VERSION "canboat-NMEA2000-curated"

NS_ :

BS_:

BU_: Vector__XXX
BO_ 2583633408 PGN_130846_furunoMotionSensorStatusExtended: 28 Vector__XXX
 SG_ Manufacturer_Code : 0|11@1+ (1.0,0) [0|2047] "" Vector__XXX
 SG_ Industry_Code : 13|3@1+ (1.0,0) [0|7] "" Vector__XXX
 SG_ Status : 16|8@1+ (1.0,0) [0|255] "" Vector__XXX
 SG_ Data : 24|200@1+ (1.0,0) [0|1606938044258990275541962092341162602522202993782792835301375] "" Vector__XXX

BO_ 2583633408 PGN_130846_maretronBatteryAmpHourRecord: 223 Vector__XXX
 SG_ Manufacturer_Code : 0|11@1+ (1.0,0) [0|2047] "" Vector__XXX
 SG_ Industry_Code : 13|3@1+ (1.0,0) [0|7] "" Vector__XXX
 SG_ Data : 16|1768@1+ (1.0,0) [0|16635364987126134419907490844611231857889171561340108669757218330385068731224834608417815051548234195819468783937845710359164977421616154908223175941492902641772198991471137845920843845811776377869137773379678289214194183661112800944378464511794046030758602257005203964634516091405743061582849883160885255175229773660916874237270946647032424101972117051870087763059119895517977437771543686400460392041962138103436564399831189767740372774280024852942859855049773927338342604171805121253257539126169331943684033945189625789470637817855] "" Vector__XXX

BO_ 2583633408 PGN_130846_simnetParameterSet: 12 Vector__XXX
 SG_ Manufacturer_Code : 0|11@1+ (1.0,0) [0|2047] "" Vector__XXX
 SG_ Industry_Code : 13|3@1+ (1.0,0) [0|7] "" Vector__XXX
 SG_ Address : 16|8@1+ (1.0,0) [0|255] "" Vector__XXX
 SG_ Instance : 24|8@1+ (1.0,0) [0|255] "" Vector__XXX
 SG_ Network_Group : 32|8@1+ (1.0,0) [0|255] "" Vector__XXX
 SG_ Source : 40|8@1+ (1.0,0) [0|255] "" Vector__XXX
 SG_ Key : 48|24@1+ (1.0,0) [0|16777215] "" Vector__XXX
 SG_ Operation : 72|8@1+ (1.0,0) [0|255] "" Vector__XXX
 SG_ Length : 80|8@1+ (1.0,0) [0|255] "" Vector__XXX
 SG_ Value : 88|8@1+ (1.0,0) [0|255] "" Vector__XXX

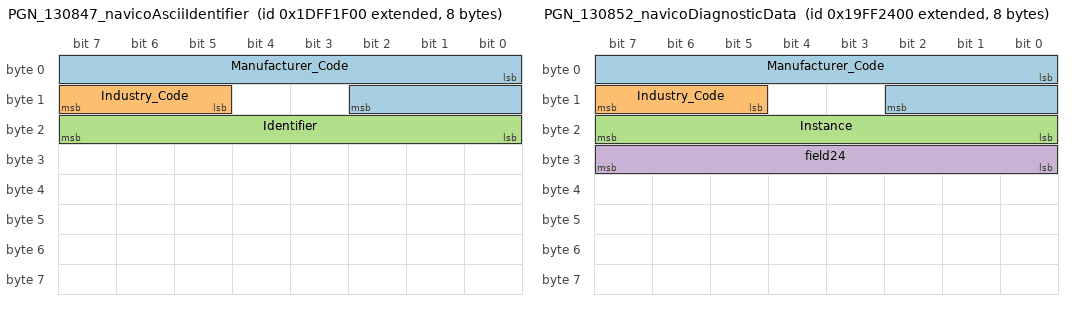
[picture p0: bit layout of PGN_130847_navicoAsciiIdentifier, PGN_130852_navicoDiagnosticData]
BO_ 2650742528 PGN_130847_navicoAsciiIdentifier: 8 Vector__XXX
 SG_ Manufacturer_Code : 0|11@1+ (1.0,0) [0|2047] "" Vector__XXX
 SG_ Industry_Code : 13|3@1+ (1.0,0) [0|7] "" Vector__XXX
 SG_ Identifier : 16|8@1+ (1.0,0) [0|255] "" Vector__XXX

BO_ 2583633664 PGN_130847_seatalkNodeStatistics: 10 Vector__XXX
 SG_ Manufacturer_Code : 0|11@1+ (1.0,0) [0|2047] "" Vector__XXX
 SG_ Industry_Code : 13|3@1+ (1.0,0) [0|7] "" Vector__XXX
 SG_ Product_Code : 16|16@1+ (1.0,0) [0|65535] "" Vector__XXX
 SG_ Year : 32|8@1+ (1.0,0) [0|255] "" Vector__XXX
 SG_ Month : 40|8@1+ (1.0,0) [0|255] "" Vector__XXX
 SG_ Device_Number : 48|16@1+ (1.0,0) [0|65535] "" Vector__XXX
 SG_ Node_Voltage : 64|16@1+ (0.01,0) [0.0|655.35] "" Vector__XXX

BO_ 2650742784 PGN_130848_seatalkWaypointInformation: 31 Vector__XXX
 SG_ Manufacturer_Code : 0|11@1+ (1.0,0) [0|2047] "" Vector__XXX
 SG_ Industry_Code : 13|3@1+ (1.0,0) [0|7] "" Vector__XXX
 SG_ SID : 16|8@1+ (1.0,0) [0|255] "" Vector__XXX
 SG_ Waypoint_Name : 24|128@1+ (1.0,0) [0|340282366920938463463374607431768211455] "" Vector__XXX
 SG_ Waypoint_Sequence : 152|32@1+ (1.0,0) [0|4294967295] "" Vector__XXX
 SG_ Bearing_to_Waypoint__True : 184|16@1+ (0.0001,0) [0.0|6.5535000000000005] "" Vector__XXX
 SG_ Bearing_to_Waypoint__Magnetic : 200|16@1+ (0.0001,0) [0.0|6.5535000000000005] "" Vector__XXX
 SG_ Distance_to_Waypoint : 216|32@1+ (0.01,0) [0.0|42949672.95] "" Vector__XXX

BO_ 2583634176 PGN_130849_navicoProprietaryFp: 8 Vector__XXX
 SG_ Manufacturer_Code : 0|11@1+ (1.0,0) [0|2047] "" Vector__XXX
 SG_ Industry_Code : 13|3@1+ (1.0,0) [0|7] "" Vector__XXX

BO_ 2315198976 PGN_130850_simnetAlarm: 12 Vector__XXX
 SG_ Manufacturer_Code : 0|11@1+ (1.0,0) [0|2047] "" Vector__XXX
 SG_ Industry_Code : 13|3@1+ (1.0,0) [0|7] "" Vector__XXX
 SG_ Address : 16|8@1+ (1.0,0) [0|255] "" Vector__XXX
 SG_ Network_Group : 32|8@1+ (1.0,0) [0|255] "" Vector__XXX
 SG_ Event_Type : 40|8@1+ (1.0,0) [0|255] "" Vector__XXX
 SG_ Command : 48|8@1+ (1.0,0) [0|255] "" Vector__XXX
 SG_ Spare : 56|8@1+ (1.0,0) [0|255] "" Vector__XXX
 SG_ Alarm_ID : 64|16@1+ (1.0,0) [0|65535] "" Vector__XXX
 SG_ F : 80|8@1+ (1.0,0) [0|255] "" Vector__XXX
 SG_ G : 88|8@1+ (1.0,0) [0|255] "" Vector__XXX

BO_ 2315198976 PGN_130850_simnetApCommand: 12 Vector__XXX
 SG_ Manufacturer_Code : 0|11@1+ (1.0,0) [0|2047] "" Vector__XXX
 SG_ Industry_Code : 13|3@1+ (1.0,0) [0|7] "" Vector__XXX
 SG_ Address : 16|8@1+ (1.0,0) [0|255] "" Vector__XXX
 SG_ Network_Group : 32|8@1+ (1.0,0) [0|255] "" Vector__XXX
 SG_ Command_Type : 40|8@1+ (1.0,0) [0|255] "" Vector__XXX
 SG_ Event : 48|8@1+ (1.0,0) [0|255] "" Vector__XXX
 SG_ Spare : 56|8@1+ (1.0,0) [0|255] "" Vector__XXX

BO_ 2315198976 PGN_130850_simnetCommandApChangeCourse: 12 Vector__XXX
 SG_ Manufacturer_Code : 0|11@1+ (1.0,0) [0|2047] "" Vector__XXX
 SG_ Industry_Code : 13|3@1+ (1.0,0) [0|7] "" Vector__XXX
 SG_ Address : 16|8@1+ (1.0,0) [0|255] "" Vector__XXX
 SG_ Network_Group : 32|8@1+ (1.0,0) [0|255] "" Vector__XXX
 SG_ Command_Type : 40|8@1+ (1.0,0) [0|255] "" Vector__XXX
 SG_ Event : 48|8@1+ (1.0,0) [0|255] "" Vector__XXX
 SG_ Spare : 56|8@1+ (1.0,0) [0|255] "" Vector__XXX
 SG_ Direction : 64|8@1+ (1.0,0) [0|255] "" Vector__XXX
 SG_ Angle : 72|16@1+ (0.0001,0) [0.0|6.5535000000000005] "" Vector__XXX

BO_ 2315198976 PGN_130850_simnetCommandApFollowUp: 12 Vector__XXX
 SG_ Manufacturer_Code : 0|11@1+ (1.0,0) [0|2047] "" Vector__XXX
 SG_ Industry_Code : 13|3@1+ (1.0,0) [0|7] "" Vector__XXX
 SG_ Address : 16|8@1+ (1.0,0) [0|255] "" Vector__XXX
 SG_ Network_Group : 32|8@1+ (1.0,0) [0|255] "" Vector__XXX
 SG_ Command_Type : 40|8@1+ (1.0,0) [0|255] "" Vector__XXX
 SG_ Event : 48|8@1+ (1.0,0) [0|255] "" Vector__XXX
 SG_ Spare : 56|8@1+ (1.0,0) [0|255] "" Vector__XXX

BO_ 2315198976 PGN_130850_simnetCommandApHeading: 12 Vector__XXX
 SG_ Manufacturer_Code : 0|11@1+ (1.0,0) [0|2047] "" Vector__XXX
 SG_ Industry_Code : 13|3@1+ (1.0,0) [0|7] "" Vector__XXX
 SG_ Address : 16|8@1+ (1.0,0) [0|255] "" Vector__XXX
 SG_ Network_Group : 32|8@1+ (1.0,0) [0|255] "" Vector__XXX
 SG_ Command_Type : 40|8@1+ (1.0,0) [0|255] "" Vector__XXX
 SG_ Event : 48|8@1+ (1.0,0) [0|255] "" Vector__XXX
 SG_ Spare : 56|8@1+ (1.0,0) [0|255] "" Vector__XXX

BO_ 2315198976 PGN_130850_simnetCommandApNav: 12 Vector__XXX
 SG_ Manufacturer_Code : 0|11@1+ (1.0,0) [0|2047] "" Vector__XXX
 SG_ Industry_Code : 13|3@1+ (1.0,0) [0|7] "" Vector__XXX
 SG_ Address : 16|8@1+ (1.0,0) [0|255] "" Vector__XXX
 SG_ Network_Group : 32|8@1+ (1.0,0) [0|255] "" Vector__XXX
 SG_ Command_Type : 40|8@1+ (1.0,0) [0|255] "" Vector__XXX
 SG_ Event : 48|8@1+ (1.0,0) [0|255] "" Vector__XXX
 SG_ Spare : 56|8@1+ (1.0,0) [0|255] "" Vector__XXX

BO_ 2315198976 PGN_130850_simnetCommandApNodrift: 12 Vector__XXX
 SG_ Manufacturer_Code : 0|11@1+ (1.0,0) [0|2047] "" Vector__XXX
 SG_ Industry_Code : 13|3@1+ (1.0,0) [0|7] "" Vector__XXX
 SG_ Address : 16|8@1+ (1.0,0) [0|255] "" Vector__XXX
 SG_ Network_Group : 32|8@1+ (1.0,0) [0|255] "" Vector__XXX
 SG_ Command_Type : 40|8@1+ (1.0,0) [0|255] "" Vector__XXX
 SG_ Event : 48|8@1+ (1.0,0) [0|255] "" Vector__XXX
 SG_ Spare : 56|8@1+ (1.0,0) [0|255] "" Vector__XXX

BO_ 2315198976 PGN_130850_simnetCommandApStandby: 12 Vector__XXX
 SG_ Manufacturer_Code : 0|11@1+ (1.0,0) [0|2047] "" Vector__XXX
 SG_ Industry_Code : 13|3@1+ (1.0,0) [0|7] "" Vector__XXX
 SG_ Address : 16|8@1+ (1.0,0) [0|255] "" Vector__XXX
 SG_ Network_Group : 32|8@1+ (1.0,0) [0|255] "" Vector__XXX
 SG_ Command_Type : 40|8@1+ (1.0,0) [0|255] "" Vector__XXX
 SG_ Event : 48|8@1+ (1.0,0) [0|255] "" Vector__XXX
 SG_ Spare : 56|8@1+ (1.0,0) [0|255] "" Vector__XXX

BO_ 2315198976 PGN_130850_simnetCommandApTack: 12 Vector__XXX
 SG_ Manufacturer_Code : 0|11@1+ (1.0,0) [0|2047] "" Vector__XXX
 SG_ Industry_Code : 13|3@1+ (1.0,0) [0|7] "" Vector__XXX
 SG_ Address : 16|8@1+ (1.0,0) [0|255] "" Vector__XXX
 SG_ Network_Group : 32|8@1+ (1.0,0) [0|255] "" Vector__XXX
 SG_ Command_Type : 40|8@1+ (1.0,0) [0|255] "" Vector__XXX
 SG_ Event : 48|8@1+ (1.0,0) [0|255] "" Vector__XXX
 SG_ Unknown_A : 56|8@1+ (1.0,0) [0|255] "" Vector__XXX
 SG_ Unknown_B : 64|8@1+ (1.0,0) [0|255] "" Vector__XXX

BO_ 2315198976 PGN_130850_simnetCommandApWind: 12 Vector__XXX
 SG_ Manufacturer_Code : 0|11@1+ (1.0,0) [0|2047] "" Vector__XXX
 SG_ Industry_Code : 13|3@1+ (1.0,0) [0|7] "" Vector__XXX
 SG_ Address : 16|8@1+ (1.0,0) [0|255] "" Vector__XXX
 SG_ Network_Group : 32|8@1+ (1.0,0) [0|255] "" Vector__XXX
 SG_ Command_Type : 40|8@1+ (1.0,0) [0|255] "" Vector__XXX
 SG_ Event : 48|8@1+ (1.0,0) [0|255] "" Vector__XXX
 SG_ Spare : 56|8@1+ (1.0,0) [0|255] "" Vector__XXX

BO_ 2315198976 PGN_130850_simnetEvent: 12 Vector__XXX
 SG_ Manufacturer_Code : 0|11@1+ (1.0,0) [0|2047] "" Vector__XXX
 SG_ Industry_Code : 13|3@1+ (1.0,0) [0|7] "" Vector__XXX
 SG_ Address : 16|8@1+ (1.0,0) [0|255] "" Vector__XXX
 SG_ Network_Group : 32|8@1+ (1.0,0) [0|255] "" Vector__XXX

BO_ 2315198976 PGN_130850_simnetEventCommandTimer: 12 Vector__XXX
 SG_ Manufacturer_Code : 0|11@1+ (1.0,0) [0|2047] "" Vector__XXX
 SG_ Industry_Code : 13|3@1+ (1.0,0) [0|7] "" Vector__XXX
 SG_ Address : 16|8@1+ (1.0,0) [0|255] "" Vector__XXX
 SG_ Network_Group : 32|8@1+ (1.0,0) [0|255] "" Vector__XXX
 SG_ Event_Type : 40|8@1+ (1.0,0) [0|255] "" Vector__XXX
 SG_ Event : 48|16@1+ (1.0,0) [0|65535] "" Vector__XXX
 SG_ Parameter_1 : 64|8@1+ (1.0,0) [0|255] "" Vector__XXX
 SG_ Parameter_2 : 72|16@1+ (1.0,0) [0|65535] "" Vector__XXX
 SG_ Parameter_3 : 88|8@1+ (1.0,0) [0|255] "" Vector__XXX

BO_ 2650743552 PGN_130851_simnetApCommandReply: 12 Vector__XXX
 SG_ Manufacturer_Code : 0|11@1+ (1.0,0) [0|2047] "" Vector__XXX
 SG_ Industry_Code : 13|3@1+ (1.0,0) [0|7] "" Vector__XXX
 SG_ Address : 16|8@1+ (1.0,0) [0|255] "" Vector__XXX
 SG_ Network_Group : 32|8@1+ (1.0,0) [0|255] "" Vector__XXX
 SG_ Command_Type : 40|8@1+ (1.0,0) [0|255] "" Vector__XXX
 SG_ Event : 48|8@1+ (1.0,0) [0|255] "" Vector__XXX
 SG_ Spare : 56|8@1+ (1.0,0) [0|255] "" Vector__XXX
 SG_ D : 64|8@1+ (1.0,0) [0|255] "" Vector__XXX
 SG_ Value : 72|16@1+ (1.0,0) [0|65535] "" Vector__XXX

BO_ 2650743552 PGN_130851_simnetApCommandReplyChangeCourse: 12 Vector__XXX
 SG_ Manufacturer_Code : 0|11@1+ (1.0,0) [0|2047] "" Vector__XXX
 SG_ Industry_Code : 13|3@1+ (1.0,0) [0|7] "" Vector__XXX
 SG_ Address : 16|8@1+ (1.0,0) [0|255] "" Vector__XXX
 SG_ Network_Group : 32|8@1+ (1.0,0) [0|255] "" Vector__XXX
 SG_ Command_Type : 40|8@1+ (1.0,0) [0|255] "" Vector__XXX
 SG_ Event : 48|8@1+ (1.0,0) [0|255] "" Vector__XXX
 SG_ Spare : 56|8@1+ (1.0,0) [0|255] "" Vector__XXX
 SG_ Direction : 64|8@1+ (1.0,0) [0|255] "" Vector__XXX
 SG_ Angle : 72|16@1+ (0.0001,0) [0.0|6.5535000000000005] "" Vector__XXX

BO_ 2583634944 PGN_130852_navicoDiagnosticData: 8 Vector__XXX
 SG_ Manufacturer_Code : 0|11@1+ (1.0,0) [0|2047] "" Vector__XXX
 SG_ Industry_Code : 13|3@1+ (1.0,0) [0|7] "" Vector__XXX
 SG_ Instance : 16|8@1+ (1.0,0) [0|255] "" Vector__XXX
 SG_ field24 : 24|8@1+ (1.0,0) [0|255] "" Vector__XXX

CM_ BO_ 2583633408 "NMEA2000: PGN 130846 - Furuno: Motion Sensor Status Extended (type: Fast)";
CM_ BO_ 2583633408 "NMEA2000: PGN 130846 - Maretron: Battery Amp Hour Record (type: Fast)";
CM_ BO_ 2583633408 "NMEA2000: PGN 130846 - Simnet: Key Value - Long (type: Fast)";
CM_ BO_ 2650742528 "NMEA2000: PGN 130847 - Navico: ASCII Identifier (type: Fast)";
CM_ BO_ 2583633664 "NMEA2000: PGN 130847 - SeaTalk: Node Statistics (type: Fast)";
CM_ BO_ 2650742784 "NMEA2000: PGN 130848 - SeaTalk: Waypoint Information (type: Fast)";
CM_ BO_ 2583634176 "NMEA2000: PGN 130849 - Navico: Proprietary FP (type: Fast)";
CM_ BO_ 2315198976 "NMEA2000: PGN 130850 - Simnet: Alarm (type: Fast)";
CM_ BO_ 2315198976 "NMEA2000: PGN 130850 - Simnet: AP command (type: Fast)";
CM_ BO_ 2315198976 "NMEA2000: PGN 130850 - Simnet: Command AP Change Course (type: Fast)";
CM_ BO_ 2315198976 "NMEA2000: PGN 130850 - Simnet: Command AP Follow Up (type: Fast)";
CM_ BO_ 2315198976 "NMEA2000: PGN 130850 - Simnet: Command AP Heading (type: Fast)";
CM_ BO_ 2315198976 "NMEA2000: PGN 130850 - Simnet: Command AP Nav (type: Fast)";
CM_ BO_ 2315198976 "NMEA2000: PGN 130850 - Simnet: Command AP NoDrift (type: Fast)";
CM_ BO_ 2315198976 "NMEA2000: PGN 130850 - Simnet: Command AP Standby (type: Fast)";
CM_ BO_ 2315198976 "NMEA2000: PGN 130850 - Simnet: Command AP Tack (type: Fast)";
CM_ BO_ 2315198976 "NMEA2000: PGN 130850 - Simnet: Command AP Wind (type: Fast)";
CM_ BO_ 2315198976 "NMEA2000: PGN 130850 - Simnet: Event (type: Fast)";
CM_ BO_ 2315198976 "NMEA2000: PGN 130850 - Simnet: Event Command: Timer (type: Fast)";
CM_ BO_ 2650743552 "NMEA2000: PGN 130851 - Simnet: AP command Reply (type: Fast)";
CM_ BO_ 2650743552 "NMEA2000: PGN 130851 - Simnet: AP command Reply: Change Course (type: Fast)";
CM_ BO_ 2583634944 "NMEA2000: PGN 130852 - Navico: Diagnostic Data (type: Fast)";
CM_ SG_ 2583633408 Manufacturer_Code "Furuno; canboat type: LOOKUP";
CM_ SG_ 2583633408 Industry_Code "Marine Industry; canboat type: LOOKUP";
CM_ SG_ 2583633408 Status "canboat type: UINT8";
CM_ SG_ 2583633408 Data "canboat type: BINARY";
CM_ SG_ 2583633408 Manufacturer_Code "Maretron; canboat type: LOOKUP";
CM_ SG_ 2583633408 Industry_Code "Marine Industry; canboat type: LOOKUP";
CM_ SG_ 2583633408 Data "canboat type: BINARY";
CM_ SG_ 2583633408 Manufacturer_Code "Simrad; canboat type: LOOKUP";
CM_ SG_ 2583633408 Industry_Code "Marine Industry; canboat type: LOOKUP";
CM_ SG_ 2583633408 Address "NMEA 2000 address of commanded device; canboat type: UINT8";
CM_ SG_ 2583633408 Instance "Instance index when a Key has multiple sources/instances; 0xFF when not applicable. Caller-supplied and echoed back in replies.; canboat type: UINT8";
CM_ SG_ 2583633408 Network_Group "This can be either the Display Group, Units Group, Damping Group or Alarms Group, depending on which key is being set; canboat type: LOOKUP";
CM_ SG_ 2583633408 Source "Source/owner that provided the value; set by the responder when Operation = Reply, 0xFF in read/set requests. This is NOT an NMEA 2000 bus address.; canboat type: UINT8";
CM_ SG_ 2583633408 Key "Composite 24-bit little-endian key = command group (low byte) | parameter key (upper 16 bits) << 8. The two parts are NOT split into separate fields because the parameter key is only unique within a command group (e.g. key 1 is 'True wind high' in group 4 but 'Deep water' in group 8), so the value's data type can only be resolved from the group and key together. This key space is distinct from the PGN 130822 tDataType ids and from the B&G and Mercury key spaces.; canboat type: DYNAMIC_FIELD_KEY";
CM_ SG_ 2583633408 Operation "canboat type: LOOKUP";
CM_ SG_ 2583633408 Length "Number of bytes in the Value field that follows; canboat type: DYNAMIC_FIELD_LENGTH";
CM_ SG_ 2583633408 Value "Variable-width value; width given by Length, datatype resolved per Key; canboat type: DYNAMIC_FIELD_VALUE";
CM_ SG_ 2650742528 Manufacturer_Code "Navico; canboat type: LOOKUP";
CM_ SG_ 2650742528 Industry_Code "Marine Industry; canboat type: LOOKUP";
CM_ SG_ 2650742528 Identifier "canboat type: STRING_LZ";
CM_ SG_ 2583633664 Manufacturer_Code "Raymarine; canboat type: LOOKUP";
CM_ SG_ 2583633664 Industry_Code "Marine Industry; canboat type: LOOKUP";
CM_ SG_ 2583633664 Product_Code "canboat type: UINT16";
CM_ SG_ 2583633664 Year "canboat type: UINT8";
CM_ SG_ 2583633664 Month "canboat type: UINT8";
CM_ SG_ 2583633664 Device_Number "canboat type: UINT16";
CM_ SG_ 2583633664 Node_Voltage "canboat type: VOLTAGE_UFIX16_10MV";
CM_ SG_ 2650742784 Manufacturer_Code "Raymarine; canboat type: LOOKUP";
CM_ SG_ 2650742784 Industry_Code "Marine Industry; canboat type: LOOKUP";
CM_ SG_ 2650742784 SID "canboat type: UINT8";
CM_ SG_ 2650742784 Waypoint_Name "canboat type: STRING_FIX";
CM_ SG_ 2650742784 Waypoint_Sequence "canboat type: STRING_FIX";
CM_ SG_ 2650742784 Bearing_to_Waypoint__True "canboat type: ANGLE_UFIX16";
CM_ SG_ 2650742784 Bearing_to_Waypoint__Magnetic "canboat type: ANGLE_UFIX16";
CM_ SG_ 2650742784 Distance_to_Waypoint "canboat type: LENGTH_UFIX32_CM";
CM_ SG_ 2583634176 Manufacturer_Code "Navico; canboat type: LOOKUP";
CM_ SG_ 2583634176 Industry_Code "Marine Industry; canboat type: LOOKUP";
CM_ SG_ 2315198976 Manufacturer_Code "Simrad; canboat type: LOOKUP";
CM_ SG_ 2315198976 Industry_Code "Marine Industry; canboat type: LOOKUP";
CM_ SG_ 2315198976 Address "NMEA 2000 address of commanded device; canboat type: UINT8";
CM_ SG_ 2315198976 Network_Group "canboat type: LOOKUP";
CM_ SG_ 2315198976 Event_Type "Alarm; canboat type: LOOKUP";
CM_ SG_ 2315198976 Command "canboat type: LOOKUP";
CM_ SG_ 2315198976 Spare "canboat type: SPARE";
CM_ SG_ 2315198976 Alarm_ID "canboat type: LOOKUP";
CM_ SG_ 2315198976 F "canboat type: UINT8";
CM_ SG_ 2315198976 G "canboat type: UINT8";
CM_ SG_ 2315198976 Manufacturer_Code "Simrad; canboat type: LOOKUP";
CM_ SG_ 2315198976 Industry_Code "Marine Industry; canboat type: LOOKUP";
CM_ SG_ 2315198976 Address "NMEA 2000 address of commanded device; canboat type: UINT8";
CM_ SG_ 2315198976 Network_Group "canboat type: LOOKUP";
CM_ SG_ 2315198976 Command_Type "AP Command; canboat type: LOOKUP";
CM_ SG_ 2315198976 Event "canboat type: LOOKUP";
CM_ SG_ 2315198976 Spare "canboat type: SPARE";
CM_ SG_ 2315198976 Manufacturer_Code "Simrad; canboat type: LOOKUP";
CM_ SG_ 2315198976 Industry_Code "Marine Industry; canboat type: LOOKUP";
CM_ SG_ 2315198976 Address "NMEA 2000 address of commanded device; canboat type: UINT8";
CM_ SG_ 2315198976 Network_Group "canboat type: LOOKUP";
CM_ SG_ 2315198976 Command_Type "AP Command; canboat type: LOOKUP";
CM_ SG_ 2315198976 Event "Change course; canboat type: LOOKUP";
CM_ SG_ 2315198976 Spare "canboat type: SPARE";
CM_ SG_ 2315198976 Direction "canboat type: LOOKUP";
CM_ SG_ 2315198976 Angle "Absolute change in desired attitude, generally 1 or 10 degrees; canboat type: ANGLE_UFIX16";
CM_ SG_ 2315198976 Manufacturer_Code "Simrad; canboat type: LOOKUP";
CM_ SG_ 2315198976 Industry_Code "Marine Industry; canboat type: LOOKUP";
CM_ SG_ 2315198976 Address "NMEA 2000 address of commanded device; canboat type: UINT8";
CM_ SG_ 2315198976 Network_Group "canboat type: LOOKUP";
CM_ SG_ 2315198976 Command_Type "Follow Up; canboat type: LOOKUP";
CM_ SG_ 2315198976 Event "Follow Up mode; canboat type: LOOKUP";
CM_ SG_ 2315198976 Spare "canboat type: SPARE";
CM_ SG_ 2315198976 Manufacturer_Code "Simrad; canboat type: LOOKUP";
CM_ SG_ 2315198976 Industry_Code "Marine Industry; canboat type: LOOKUP";
CM_ SG_ 2315198976 Address "NMEA 2000 address of commanded device; canboat type: UINT8";
CM_ SG_ 2315198976 Network_Group "canboat type: LOOKUP";
CM_ SG_ 2315198976 Command_Type "AP Command; canboat type: LOOKUP";
CM_ SG_ 2315198976 Event "Heading mode; canboat type: LOOKUP";
CM_ SG_ 2315198976 Spare "canboat type: SPARE";
CM_ SG_ 2315198976 Manufacturer_Code "Simrad; canboat type: LOOKUP";
CM_ SG_ 2315198976 Industry_Code "Marine Industry; canboat type: LOOKUP";
CM_ SG_ 2315198976 Address "NMEA 2000 address of commanded device; canboat type: UINT8";
CM_ SG_ 2315198976 Network_Group "canboat type: LOOKUP";
CM_ SG_ 2315198976 Command_Type "AP Command; canboat type: LOOKUP";
CM_ SG_ 2315198976 Event "Nav mode; canboat type: LOOKUP";
CM_ SG_ 2315198976 Spare "canboat type: SPARE";
CM_ SG_ 2315198976 Manufacturer_Code "Simrad; canboat type: LOOKUP";
CM_ SG_ 2315198976 Industry_Code "Marine Industry; canboat type: LOOKUP";
CM_ SG_ 2315198976 Address "NMEA 2000 address of commanded device; canboat type: UINT8";
CM_ SG_ 2315198976 Network_Group "canboat type: LOOKUP";
CM_ SG_ 2315198976 Command_Type "AP Command; canboat type: LOOKUP";
CM_ SG_ 2315198976 Event "No Drift mode; canboat type: LOOKUP";
CM_ SG_ 2315198976 Spare "canboat type: SPARE";
CM_ SG_ 2315198976 Manufacturer_Code "Simrad; canboat type: LOOKUP";
CM_ SG_ 2315198976 Industry_Code "Marine Industry; canboat type: LOOKUP";
CM_ SG_ 2315198976 Address "NMEA 2000 address of commanded device; canboat type: UINT8";
CM_ SG_ 2315198976 Network_Group "canboat type: LOOKUP";
CM_ SG_ 2315198976 Command_Type "AP Command; canboat type: LOOKUP";
CM_ SG_ 2315198976 Event "Standby; canboat type: LOOKUP";
CM_ SG_ 2315198976 Spare "canboat type: SPARE";
CM_ SG_ 2315198976 Manufacturer_Code "Simrad; canboat type: LOOKUP";
CM_ SG_ 2315198976 Industry_Code "Marine Industry; canboat type: LOOKUP";
CM_ SG_ 2315198976 Address "NMEA 2000 address of commanded device; canboat type: UINT8";
CM_ SG_ 2315198976 Network_Group "canboat type: LOOKUP";
CM_ SG_ 2315198976 Command_Type "AP Command; canboat type: LOOKUP";
CM_ SG_ 2315198976 Event "Tack; canboat type: LOOKUP";
CM_ SG_ 2315198976 Unknown_A "canboat type: UINT8";
CM_ SG_ 2315198976 Unknown_B "canboat type: UINT8";
CM_ SG_ 2315198976 Manufacturer_Code "Simrad; canboat type: LOOKUP";
CM_ SG_ 2315198976 Industry_Code "Marine Industry; canboat type: LOOKUP";
CM_ SG_ 2315198976 Address "NMEA 2000 address of commanded device; canboat type: UINT8";
CM_ SG_ 2315198976 Network_Group "canboat type: LOOKUP";
CM_ SG_ 2315198976 Command_Type "AP Command; canboat type: LOOKUP";
CM_ SG_ 2315198976 Event "Wind mode; canboat type: LOOKUP";
CM_ SG_ 2315198976 Spare "canboat type: SPARE";
CM_ SG_ 2315198976 Manufacturer_Code "Simrad; canboat type: LOOKUP";
CM_ SG_ 2315198976 Industry_Code "Marine Industry; canboat type: LOOKUP";
CM_ SG_ 2315198976 Address "NMEA 2000 address of commanded device; canboat type: UINT8";
CM_ SG_ 2315198976 Network_Group "canboat type: LOOKUP";
CM_ SG_ 2315198976 Manufacturer_Code "Simrad; canboat type: LOOKUP";
CM_ SG_ 2315198976 Industry_Code "Marine Industry; canboat type: LOOKUP";
CM_ SG_ 2315198976 Address "NMEA 2000 address of commanded device, used for autopilot events; canboat type: UINT8";
CM_ SG_ 2315198976 Network_Group "canboat type: LOOKUP";
CM_ SG_ 2315198976 Event_Type "Timer; canboat type: LOOKUP";
CM_ SG_ 2315198976 Event "canboat type: LOOKUP";
CM_ SG_ 2315198976 Parameter_1 "Event dependent; for the trip timer 0 = Trip 1, 1 = Trip 2; canboat type: UINT8";
CM_ SG_ 2315198976 Parameter_2 "Event dependent; canboat type: UINT16";
CM_ SG_ 2315198976 Parameter_3 "Event dependent; canboat type: UINT8";
CM_ SG_ 2650743552 Manufacturer_Code "Simrad; canboat type: LOOKUP";
CM_ SG_ 2650743552 Industry_Code "Marine Industry; canboat type: LOOKUP";
CM_ SG_ 2650743552 Address "NMEA 2000 address of the autopilot that ran the command; canboat type: UINT8";
CM_ SG_ 2650743552 Network_Group "canboat type: LOOKUP";
CM_ SG_ 2650743552 Command_Type "AP Command; canboat type: LOOKUP";
CM_ SG_ 2650743552 Event "canboat type: LOOKUP";
CM_ SG_ 2650743552 Spare "canboat type: SPARE";
CM_ SG_ 2650743552 D "canboat type: UINT8";
CM_ SG_ 2650743552 Value "canboat type: UINT16";
CM_ SG_ 2650743552 Manufacturer_Code "Simrad; canboat type: LOOKUP";
CM_ SG_ 2650743552 Industry_Code "Marine Industry; canboat type: LOOKUP";
CM_ SG_ 2650743552 Address "NMEA 2000 address of the autopilot that ran the command; canboat type: UINT8";
CM_ SG_ 2650743552 Network_Group "canboat type: LOOKUP";
CM_ SG_ 2650743552 Command_Type "AP Command; canboat type: LOOKUP";
CM_ SG_ 2650743552 Event "Change course; canboat type: LOOKUP";
CM_ SG_ 2650743552 Spare "canboat type: SPARE";
CM_ SG_ 2650743552 Direction "canboat type: LOOKUP";
CM_ SG_ 2650743552 Angle "Absolute change in desired attitude, generally 1 or 10 degrees; canboat type: ANGLE_UFIX16";
CM_ SG_ 2583634944 Manufacturer_Code "Navico; canboat type: LOOKUP";
CM_ SG_ 2583634944 Industry_Code "Marine Industry; canboat type: LOOKUP";
CM_ SG_ 2583634944 Instance "Diagnostic channel/instance the report covers; echoed from the request (0 when unspecified); canboat type: UINT8";
CM_ SG_ 2583634944 field24 "canboat type: NUMBER";
VAL_ 2583633408 Manufacturer_Code 69 "ARKS Enterprises" 78 "FW Murphy/Enovation Controls" 80 "Twin Disc" 85 "Kohler Power Systems" 88 "Hemisphere GPS" 135 "Airmar" 137 "Maretron" 140 "Lowrance" 144 "Mercury Marine" 147 "Nautibus Electronic" 148 "Blue Water Data" 154 "Westerbeke" 157 "ISSPRO" 161 "Offshore Systems (UK)" 163 "Evinrude/BRP" 165 "CPAC Systems" 168 "Xantrex Technology" 169 "Marlin Technologies" 172 "Yanmar Marine" 174 "Volvo Penta" 176 "Carling Technologies Inc. (Moritz Aerospace)" 185 "Beede Instruments" 192 "Floscan Instrument" 193 "Nobeltec" 198 "Mystic Valley Communications" 199 "Actia" 201 "Disenos Y Technologia" 211 "Digital Switching Systems" 215 "Xintex/Atena" 224 "EMMI NETWORK" 228 "ZF" 229 "Garmin" 233 "Yacht Monitoring Solutions" 235 "Sailormade Marine Telemetry/Tetra Technology" 243 "Eride" 257 "Honda Motor" 272 "Groco" 273 "Actisense" 274 "Amphenol LTW Technology" 275 "Navico" 283 "Hamilton Jet" 285 "Sea Recovery" 286 "Coelmo SRL Italy" 295 "BEP Marine" 304 "Empir Bus" 305 "NovAtel" 306 "Sleipner Motor" 307 "MBW Technologies" 315 "ICOM" 328 "Qwerty" 329 "Dief" 341 "Boening Automationstechnologie" 345 "Korean Maritime University" 351 "Thrane and Thrane" 355 "Mastervolt" 356 "Fischer Panda Generators" 358 "Victron Energy" 370 "Rolls Royce Marine" 373 "Electronic Design" 374 "Northern Lights" 378 "Glendinning" 381 "B & G" 384 "Rose Point Navigation Systems" 385 "Johnson Outdoors Marine Electronics Inc Geonav" 394 "Capi 2" 396 "Beyond Measure" 400 "Livorsi Marine" 404 "ComNav" 409 "Chetco" 419 "Fusion Electronics" 421 "Standard Horizon" 422 "True Heading" 426 "Egersund Marine Electronics" 427 "em-trak Marine Electronics" 431 "Tohatsu Co, JP" 437 "Digital Yacht" 438 "Comar Systems Limited" 440 "Cummins" 443 "VDO (aka Continental-Corporation)" 451 "Parker Hannifin aka Village Marine Tech" 459 "Alltek Marine Electronics" 460 "SAN GIORGIO S.E.I.N" 466 "Veethree Electronics & Marine" 470 "SI-TEX Marine Electronics" 471 "Sea Cross Marine" 475 "GME aka Standard Communications" 476 "Humminbird Marine Electronics" 478 "Ocean Sat" 481 "Chetco Digital Instruments" 493 "Watcheye" 499 "Lcj Capteurs" 502 "Attwood Marine" 503 "Naviop S.R.L." 504 "Vesper Marine" 510 "Marinesoft" 513 "Simarine" 517 "NoLand Engineering" 518 "Transas USA" 529 "National Instruments Korea" 530 "National Marine Electronics Association" 532 "Onwa Marine" 540 "Webasto" 571 "Marinecraft (South Korea)" 573 "McMurdo Group aka Orolia" 578 "Advansea" 579 "KVH" 580 "San Jose Technology" 583 "Yacht Control" 586 "Suzuki Motor" 591 "US Coast Guard" 595 "Ship Module aka Customware" 600 "Aquatic AV" 605 "Aventics" 606 "Intellian" 612 "SamwonIT" 614 "Arlt Tecnologies" 637 "Bavaria Yachts" 641 "Diverse Yacht Services" 644 "Wema U.S.A dba KUS" 658 "Shenzhen Jiuzhou Himunication" 688 "Rockford" 699 "Harman International" 704 "JL Audio" 708 "Lars Thrane" 715 "Autonnic" 717 "Yacht Devices" 734 "REAP Systems" 735 "AEM Performance Electronics" 739 "LxNav" 741 "Littelfuse, Inc (formerly Carling Technologies)" 743 "DaeMyung" 744 "Woosung" 748 "ISOTTA IFRA srl" 773 "Clarion US" 776 "HMI Systems" 777 "Ocean Signal" 778 "Seakeeper" 781 "Poly Planar" 785 "Fischer Panda DE" 795 "Broyda Industries" 796 "Canadian Automotive" 797 "Tides Marine" 798 "Lumishore" 799 "Still Water Designs and Audio" 802 "BJ Technologies (Beneteau)" 803 "Gill Sensors" 811 "Blue Water Desalination" 815 "FLIR" 824 "Undheim Systems" 826 "Lewmar" 838 "TeamSurv" 844 "Fell Marine" 847 "Oceanvolt" 862 "Prospec" 868 "Data Panel" 890 "L3 Technologies" 894 "Rhodan Marine Systems" 896 "Nexfour Solutions" 905 "ASA Electronics" 909 "Marines Co (South Korea)" 911 "Nautic-on" 917 "Sentinel" 929 "JL Marine Systems" 930 "Ecotronix" 944 "Zontisa Marine" 951 "EXOR International" 962 "Timbolier Industries" 963 "TJC Micro" 968 "Cox Powertrain" 969 "Blue Seas" 981 "Kobelt Manufacturing" 992 "Blue Ocean IOT" 997 "Xenta Systems" 999 "Signal K" 1004 "Ultraflex" 1008 "Lintest SmartBoat" 1011 "Soundmax" 1020 "Team Italia Marine (Onyx Marine Automation s.r.l)" 1021 "Entratech" 1022 "ITC" 1029 "The Marine Guardian" 1047 "Sonic" 1051 "ProNav" 1053 "Vetus Maxwell INC." 1056 "Lithium Pros" 1059 "Boatrax" 1062 "Marol Co ltd" 1065 "CALYPSO Instruments" 1066 "Spot Zero Water" 1069 "Lithionics Battery" 1070 "Quick-teck Electronics" 1075 "Uniden America" 1083 "Nauticoncept" 1084 "Shadow-Caster LED lighting" 1085 "Wet Sounds" 1088 "E-T-A Circuit Breakers" 1092 "Scheiber" 1100 "Smart Yachts International Limited" 1109 "Dockmate" 1114 "Bobs Machine" 1118 "L3Harris ASV" 1119 "Balmar" 1120 "Elettromedia" 1127 "Electromaax" 1140 "Across Oceans Systems" 1145 "Kiwi Yachting" 1150 "BSB Artificial Intelligence" 1151 "Orca Technologies" 1154 "TBS Electronics" 1158 "Technoton Electroics" 1160 "MG Energy Systems" 1169 "Sea Machine Robotics" 1171 "Vista Manufacturing" 1183 "Zipwake" 1186 "Sailmon" 1192 "Airmoniq Pro Kft" 1194 "Sierra Marine" 1200 "Xinuo Information Technology (Xiamen)" 1218 "Septentrio" 1233 "NKE Marine Electronics" 1238 "SuperTrack Aps" 1239 "Honda Electronics" 1245 "Raritan Engineering" 1249 "Integrated Power Solutions AG" 1260 "Interactive Technologies" 1283 "LTG-Tech" 1299 "Energy Solutions (UK)" 1300 "WATT Fuel Cell" 1302 "Pro Mainer" 1305 "Dragonfly Energy" 1306 "Koden Electronics" 1311 "Humphree" 1316 "Hinkley Yachts" 1317 "Global Marine Management GmbH (GMM)" 1320 "Triskel Marine" 1330 "Warwick Control Technologies" 1331 "Dolphin Charger" 1337 "Barnacle Systems" 1348 "Radian IoT" 1353 "Ocean LED Marine" 1359 "BluNav" 1361 "OVA (Nantong Saiyang Electronics Co., Ltd)" 1368 "RAD Propulsion" 1369 "Electric Yacht" 1372 "Elco Motor Yachts" 1384 "Tecnoseal Foundry S.r.l" 1385 "Pro Charging Systems" 1389 "EVEX" 1398 "Gobius Sensor Technology" 1403 "Arco Marine" 1408 "Lenco Marine" 1413 "Naocontrol" 1417 "Revatek" 1438 "Aeolionics" 1439 "PredictWind" 1440 "Egis Mobile Electric" 1445 "Starboard Yacht Group" 1446 "Roswell Marine" 1451 "ePropulsion (Guangdong ePropulsion Technology Ltd.)" 1452 "Micro-Air" 1453 "Vital Battery" 1458 "Ride Controller" 1460 "Tocaro Blue" 1461 "Vanquish Yachts" 1471 "FT Technologies" 1478 "Alps Alpine" 1481 "E-Force Marine" 1482 "CMC Marine" 1483 "Nanjing Sandemarine Information Technology" 1850 "Teleflex Marine (SeaStar Solutions)" 1851 "Raymarine" 1852 "Navionics" 1853 "Japan Radio" 1854 "Northstar Technologies" 1855 "Furuno" 1856 "Trimble" 1857 "Simrad" 1858 "Litton" 1859 "Kvasar" 1860 "MMP" 1861 "Vector Cantech" 1862 "Yamaha Marine" 1863 "Faria Instruments" ;
VAL_ 2583633408 Industry_Code 0 "Global" 1 "Highway" 2 "Agriculture" 3 "Construction" 4 "Marine Industry" 5 "Industrial" ;
VAL_ 2583633408 Manufacturer_Code 69 "ARKS Enterprises" 78 "FW Murphy/Enovation Controls" 80 "Twin Disc" 85 "Kohler Power Systems" 88 "Hemisphere GPS" 135 "Airmar" 137 "Maretron" 140 "Lowrance" 144 "Mercury Marine" 147 "Nautibus Electronic" 148 "Blue Water Data" 154 "Westerbeke" 157 "ISSPRO" 161 "Offshore Systems (UK)" 163 "Evinrude/BRP" 165 "CPAC Systems" 168 "Xantrex Technology" 169 "Marlin Technologies" 172 "Yanmar Marine" 174 "Volvo Penta" 176 "Carling Technologies Inc. (Moritz Aerospace)" 185 "Beede Instruments" 192 "Floscan Instrument" 193 "Nobeltec" 198 "Mystic Valley Communications" 199 "Actia" 201 "Disenos Y Technologia" 211 "Digital Switching Systems" 215 "Xintex/Atena" 224 "EMMI NETWORK" 228 "ZF" 229 "Garmin" 233 "Yacht Monitoring Solutions" 235 "Sailormade Marine Telemetry/Tetra Technology" 243 "Eride" 257 "Honda Motor" 272 "Groco" 273 "Actisense" 274 "Amphenol LTW Technology" 275 "Navico" 283 "Hamilton Jet" 285 "Sea Recovery" 286 "Coelmo SRL Italy" 295 "BEP Marine" 304 "Empir Bus" 305 "NovAtel" 306 "Sleipner Motor" 307 "MBW Technologies" 315 "ICOM" 328 "Qwerty" 329 "Dief" 341 "Boening Automationstechnologie" 345 "Korean Maritime University" 351 "Thrane and Thrane" 355 "Mastervolt" 356 "Fischer Panda Generators" 358 "Victron Energy" 370 "Rolls Royce Marine" 373 "Electronic Design" 374 "Northern Lights" 378 "Glendinning" 381 "B & G" 384 "Rose Point Navigation Systems" 385 "Johnson Outdoors Marine Electronics Inc Geonav" 394 "Capi 2" 396 "Beyond Measure" 400 "Livorsi Marine" 404 "ComNav" 409 "Chetco" 419 "Fusion Electronics" 421 "Standard Horizon" 422 "True Heading" 426 "Egersund Marine Electronics" 427 "em-trak Marine Electronics" 431 "Tohatsu Co, JP" 437 "Digital Yacht" 438 "Comar Systems Limited" 440 "Cummins" 443 "VDO (aka Continental-Corporation)" 451 "Parker Hannifin aka Village Marine Tech" 459 "Alltek Marine Electronics" 460 "SAN GIORGIO S.E.I.N" 466 "Veethree Electronics & Marine" 470 "SI-TEX Marine Electronics" 471 "Sea Cross Marine" 475 "GME aka Standard Communications" 476 "Humminbird Marine Electronics" 478 "Ocean Sat" 481 "Chetco Digital Instruments" 493 "Watcheye" 499 "Lcj Capteurs" 502 "Attwood Marine" 503 "Naviop S.R.L." 504 "Vesper Marine" 510 "Marinesoft" 513 "Simarine" 517 "NoLand Engineering" 518 "Transas USA" 529 "National Instruments Korea" 530 "National Marine Electronics Association" 532 "Onwa Marine" 540 "Webasto" 571 "Marinecraft (South Korea)" 573 "McMurdo Group aka Orolia" 578 "Advansea" 579 "KVH" 580 "San Jose Technology" 583 "Yacht Control" 586 "Suzuki Motor" 591 "US Coast Guard" 595 "Ship Module aka Customware" 600 "Aquatic AV" 605 "Aventics" 606 "Intellian" 612 "SamwonIT" 614 "Arlt Tecnologies" 637 "Bavaria Yachts" 641 "Diverse Yacht Services" 644 "Wema U.S.A dba KUS" 658 "Shenzhen Jiuzhou Himunication" 688 "Rockford" 699 "Harman International" 704 "JL Audio" 708 "Lars Thrane" 715 "Autonnic" 717 "Yacht Devices" 734 "REAP Systems" 735 "AEM Performance Electronics" 739 "LxNav" 741 "Littelfuse, Inc (formerly Carling Technologies)" 743 "DaeMyung" 744 "Woosung" 748 "ISOTTA IFRA srl" 773 "Clarion US" 776 "HMI Systems" 777 "Ocean Signal" 778 "Seakeeper" 781 "Poly Planar" 785 "Fischer Panda DE" 795 "Broyda Industries" 796 "Canadian Automotive" 797 "Tides Marine" 798 "Lumishore" 799 "Still Water Designs and Audio" 802 "BJ Technologies (Beneteau)" 803 "Gill Sensors" 811 "Blue Water Desalination" 815 "FLIR" 824 "Undheim Systems" 826 "Lewmar" 838 "TeamSurv" 844 "Fell Marine" 847 "Oceanvolt" 862 "Prospec" 868 "Data Panel" 890 "L3 Technologies" 894 "Rhodan Marine Systems" 896 "Nexfour Solutions" 905 "ASA Electronics" 909 "Marines Co (South Korea)" 911 "Nautic-on" 917 "Sentinel" 929 "JL Marine Systems" 930 "Ecotronix" 944 "Zontisa Marine" 951 "EXOR International" 962 "Timbolier Industries" 963 "TJC Micro" 968 "Cox Powertrain" 969 "Blue Seas" 981 "Kobelt Manufacturing" 992 "Blue Ocean IOT" 997 "Xenta Systems" 999 "Signal K" 1004 "Ultraflex" 1008 "Lintest SmartBoat" 1011 "Soundmax" 1020 "Team Italia Marine (Onyx Marine Automation s.r.l)" 1021 "Entratech" 1022 "ITC" 1029 "The Marine Guardian" 1047 "Sonic" 1051 "ProNav" 1053 "Vetus Maxwell INC." 1056 "Lithium Pros" 1059 "Boatrax" 1062 "Marol Co ltd" 1065 "CALYPSO Instruments" 1066 "Spot Zero Water" 1069 "Lithionics Battery" 1070 "Quick-teck Electronics" 1075 "Uniden America" 1083 "Nauticoncept" 1084 "Shadow-Caster LED lighting" 1085 "Wet Sounds" 1088 "E-T-A Circuit Breakers" 1092 "Scheiber" 1100 "Smart Yachts International Limited" 1109 "Dockmate" 1114 "Bobs Machine" 1118 "L3Harris ASV" 1119 "Balmar" 1120 "Elettromedia" 1127 "Electromaax" 1140 "Across Oceans Systems" 1145 "Kiwi Yachting" 1150 "BSB Artificial Intelligence" 1151 "Orca Technologies" 1154 "TBS Electronics" 1158 "Technoton Electroics" 1160 "MG Energy Systems" 1169 "Sea Machine Robotics" 1171 "Vista Manufacturing" 1183 "Zipwake" 1186 "Sailmon" 1192 "Airmoniq Pro Kft" 1194 "Sierra Marine" 1200 "Xinuo Information Technology (Xiamen)" 1218 "Septentrio" 1233 "NKE Marine Electronics" 1238 "SuperTrack Aps" 1239 "Honda Electronics" 1245 "Raritan Engineering" 1249 "Integrated Power Solutions AG" 1260 "Interactive Technologies" 1283 "LTG-Tech" 1299 "Energy Solutions (UK)" 1300 "WATT Fuel Cell" 1302 "Pro Mainer" 1305 "Dragonfly Energy" 1306 "Koden Electronics" 1311 "Humphree" 1316 "Hinkley Yachts" 1317 "Global Marine Management GmbH (GMM)" 1320 "Triskel Marine" 1330 "Warwick Control Technologies" 1331 "Dolphin Charger" 1337 "Barnacle Systems" 1348 "Radian IoT" 1353 "Ocean LED Marine" 1359 "BluNav" 1361 "OVA (Nantong Saiyang Electronics Co., Ltd)" 1368 "RAD Propulsion" 1369 "Electric Yacht" 1372 "Elco Motor Yachts" 1384 "Tecnoseal Foundry S.r.l" 1385 "Pro Charging Systems" 1389 "EVEX" 1398 "Gobius Sensor Technology" 1403 "Arco Marine" 1408 "Lenco Marine" 1413 "Naocontrol" 1417 "Revatek" 1438 "Aeolionics" 1439 "PredictWind" 1440 "Egis Mobile Electric" 1445 "Starboard Yacht Group" 1446 "Roswell Marine" 1451 "ePropulsion (Guangdong ePropulsion Technology Ltd.)" 1452 "Micro-Air" 1453 "Vital Battery" 1458 "Ride Controller" 1460 "Tocaro Blue" 1461 "Vanquish Yachts" 1471 "FT Technologies" 1478 "Alps Alpine" 1481 "E-Force Marine" 1482 "CMC Marine" 1483 "Nanjing Sandemarine Information Technology" 1850 "Teleflex Marine (SeaStar Solutions)" 1851 "Raymarine" 1852 "Navionics" 1853 "Japan Radio" 1854 "Northstar Technologies" 1855 "Furuno" 1856 "Trimble" 1857 "Simrad" 1858 "Litton" 1859 "Kvasar" 1860 "MMP" 1861 "Vector Cantech" 1862 "Yamaha Marine" 1863 "Faria Instruments" ;
VAL_ 2583633408 Industry_Code 0 "Global" 1 "Highway" 2 "Agriculture" 3 "Construction" 4 "Marine Industry" 5 "Industrial" ;
VAL_ 2583633408 Manufacturer_Code 69 "ARKS Enterprises" 78 "FW Murphy/Enovation Controls" 80 "Twin Disc" 85 "Kohler Power Systems" 88 "Hemisphere GPS" 135 "Airmar" 137 "Maretron" 140 "Lowrance" 144 "Mercury Marine" 147 "Nautibus Electronic" 148 "Blue Water Data" 154 "Westerbeke" 157 "ISSPRO" 161 "Offshore Systems (UK)" 163 "Evinrude/BRP" 165 "CPAC Systems" 168 "Xantrex Technology" 169 "Marlin Technologies" 172 "Yanmar Marine" 174 "Volvo Penta" 176 "Carling Technologies Inc. (Moritz Aerospace)" 185 "Beede Instruments" 192 "Floscan Instrument" 193 "Nobeltec" 198 "Mystic Valley Communications" 199 "Actia" 201 "Disenos Y Technologia" 211 "Digital Switching Systems" 215 "Xintex/Atena" 224 "EMMI NETWORK" 228 "ZF" 229 "Garmin" 233 "Yacht Monitoring Solutions" 235 "Sailormade Marine Telemetry/Tetra Technology" 243 "Eride" 257 "Honda Motor" 272 "Groco" 273 "Actisense" 274 "Amphenol LTW Technology" 275 "Navico" 283 "Hamilton Jet" 285 "Sea Recovery" 286 "Coelmo SRL Italy" 295 "BEP Marine" 304 "Empir Bus" 305 "NovAtel" 306 "Sleipner Motor" 307 "MBW Technologies" 315 "ICOM" 328 "Qwerty" 329 "Dief" 341 "Boening Automationstechnologie" 345 "Korean Maritime University" 351 "Thrane and Thrane" 355 "Mastervolt" 356 "Fischer Panda Generators" 358 "Victron Energy" 370 "Rolls Royce Marine" 373 "Electronic Design" 374 "Northern Lights" 378 "Glendinning" 381 "B & G" 384 "Rose Point Navigation Systems" 385 "Johnson Outdoors Marine Electronics Inc Geonav" 394 "Capi 2" 396 "Beyond Measure" 400 "Livorsi Marine" 404 "ComNav" 409 "Chetco" 419 "Fusion Electronics" 421 "Standard Horizon" 422 "True Heading" 426 "Egersund Marine Electronics" 427 "em-trak Marine Electronics" 431 "Tohatsu Co, JP" 437 "Digital Yacht" 438 "Comar Systems Limited" 440 "Cummins" 443 "VDO (aka Continental-Corporation)" 451 "Parker Hannifin aka Village Marine Tech" 459 "Alltek Marine Electronics" 460 "SAN GIORGIO S.E.I.N" 466 "Veethree Electronics & Marine" 470 "SI-TEX Marine Electronics" 471 "Sea Cross Marine" 475 "GME aka Standard Communications" 476 "Humminbird Marine Electronics" 478 "Ocean Sat" 481 "Chetco Digital Instruments" 493 "Watcheye" 499 "Lcj Capteurs" 502 "Attwood Marine" 503 "Naviop S.R.L." 504 "Vesper Marine" 510 "Marinesoft" 513 "Simarine" 517 "NoLand Engineering" 518 "Transas USA" 529 "National Instruments Korea" 530 "National Marine Electronics Association" 532 "Onwa Marine" 540 "Webasto" 571 "Marinecraft (South Korea)" 573 "McMurdo Group aka Orolia" 578 "Advansea" 579 "KVH" 580 "San Jose Technology" 583 "Yacht Control" 586 "Suzuki Motor" 591 "US Coast Guard" 595 "Ship Module aka Customware" 600 "Aquatic AV" 605 "Aventics" 606 "Intellian" 612 "SamwonIT" 614 "Arlt Tecnologies" 637 "Bavaria Yachts" 641 "Diverse Yacht Services" 644 "Wema U.S.A dba KUS" 658 "Shenzhen Jiuzhou Himunication" 688 "Rockford" 699 "Harman International" 704 "JL Audio" 708 "Lars Thrane" 715 "Autonnic" 717 "Yacht Devices" 734 "REAP Systems" 735 "AEM Performance Electronics" 739 "LxNav" 741 "Littelfuse, Inc (formerly Carling Technologies)" 743 "DaeMyung" 744 "Woosung" 748 "ISOTTA IFRA srl" 773 "Clarion US" 776 "HMI Systems" 777 "Ocean Signal" 778 "Seakeeper" 781 "Poly Planar" 785 "Fischer Panda DE" 795 "Broyda Industries" 796 "Canadian Automotive" 797 "Tides Marine" 798 "Lumishore" 799 "Still Water Designs and Audio" 802 "BJ Technologies (Beneteau)" 803 "Gill Sensors" 811 "Blue Water Desalination" 815 "FLIR" 824 "Undheim Systems" 826 "Lewmar" 838 "TeamSurv" 844 "Fell Marine" 847 "Oceanvolt" 862 "Prospec" 868 "Data Panel" 890 "L3 Technologies" 894 "Rhodan Marine Systems" 896 "Nexfour Solutions" 905 "ASA Electronics" 909 "Marines Co (South Korea)" 911 "Nautic-on" 917 "Sentinel" 929 "JL Marine Systems" 930 "Ecotronix" 944 "Zontisa Marine" 951 "EXOR International" 962 "Timbolier Industries" 963 "TJC Micro" 968 "Cox Powertrain" 969 "Blue Seas" 981 "Kobelt Manufacturing" 992 "Blue Ocean IOT" 997 "Xenta Systems" 999 "Signal K" 1004 "Ultraflex" 1008 "Lintest SmartBoat" 1011 "Soundmax" 1020 "Team Italia Marine (Onyx Marine Automation s.r.l)" 1021 "Entratech" 1022 "ITC" 1029 "The Marine Guardian" 1047 "Sonic" 1051 "ProNav" 1053 "Vetus Maxwell INC." 1056 "Lithium Pros" 1059 "Boatrax" 1062 "Marol Co ltd" 1065 "CALYPSO Instruments" 1066 "Spot Zero Water" 1069 "Lithionics Battery" 1070 "Quick-teck Electronics" 1075 "Uniden America" 1083 "Nauticoncept" 1084 "Shadow-Caster LED lighting" 1085 "Wet Sounds" 1088 "E-T-A Circuit Breakers" 1092 "Scheiber" 1100 "Smart Yachts International Limited" 1109 "Dockmate" 1114 "Bobs Machine" 1118 "L3Harris ASV" 1119 "Balmar" 1120 "Elettromedia" 1127 "Electromaax" 1140 "Across Oceans Systems" 1145 "Kiwi Yachting" 1150 "BSB Artificial Intelligence" 1151 "Orca Technologies" 1154 "TBS Electronics" 1158 "Technoton Electroics" 1160 "MG Energy Systems" 1169 "Sea Machine Robotics" 1171 "Vista Manufacturing" 1183 "Zipwake" 1186 "Sailmon" 1192 "Airmoniq Pro Kft" 1194 "Sierra Marine" 1200 "Xinuo Information Technology (Xiamen)" 1218 "Septentrio" 1233 "NKE Marine Electronics" 1238 "SuperTrack Aps" 1239 "Honda Electronics" 1245 "Raritan Engineering" 1249 "Integrated Power Solutions AG" 1260 "Interactive Technologies" 1283 "LTG-Tech" 1299 "Energy Solutions (UK)" 1300 "WATT Fuel Cell" 1302 "Pro Mainer" 1305 "Dragonfly Energy" 1306 "Koden Electronics" 1311 "Humphree" 1316 "Hinkley Yachts" 1317 "Global Marine Management GmbH (GMM)" 1320 "Triskel Marine" 1330 "Warwick Control Technologies" 1331 "Dolphin Charger" 1337 "Barnacle Systems" 1348 "Radian IoT" 1353 "Ocean LED Marine" 1359 "BluNav" 1361 "OVA (Nantong Saiyang Electronics Co., Ltd)" 1368 "RAD Propulsion" 1369 "Electric Yacht" 1372 "Elco Motor Yachts" 1384 "Tecnoseal Foundry S.r.l" 1385 "Pro Charging Systems" 1389 "EVEX" 1398 "Gobius Sensor Technology" 1403 "Arco Marine" 1408 "Lenco Marine" 1413 "Naocontrol" 1417 "Revatek" 1438 "Aeolionics" 1439 "PredictWind" 1440 "Egis Mobile Electric" 1445 "Starboard Yacht Group" 1446 "Roswell Marine" 1451 "ePropulsion (Guangdong ePropulsion Technology Ltd.)" 1452 "Micro-Air" 1453 "Vital Battery" 1458 "Ride Controller" 1460 "Tocaro Blue" 1461 "Vanquish Yachts" 1471 "FT Technologies" 1478 "Alps Alpine" 1481 "E-Force Marine" 1482 "CMC Marine" 1483 "Nanjing Sandemarine Information Technology" 1850 "Teleflex Marine (SeaStar Solutions)" 1851 "Raymarine" 1852 "Navionics" 1853 "Japan Radio" 1854 "Northstar Technologies" 1855 "Furuno" 1856 "Trimble" 1857 "Simrad" 1858 "Litton" 1859 "Kvasar" 1860 "MMP" 1861 "Vector Cantech" 1862 "Yamaha Marine" 1863 "Faria Instruments" ;
VAL_ 2583633408 Industry_Code 0 "Global" 1 "Highway" 2 "Agriculture" 3 "Construction" 4 "Marine Industry" 5 "Industrial" ;
VAL_ 2583633408 Network_Group 0 "None" 1 "Default" 2 "Group 1" 3 "Group 2" 4 "Group 3" 5 "Group 4" 6 "Group 5" 7 "Group 6" ;
VAL_ 2583633408 Operation 0 "Read" 1 "Set" 2 "Reply" ;
VAL_ 2650742528 Manufacturer_Code 69 "ARKS Enterprises" 78 "FW Murphy/Enovation Controls" 80 "Twin Disc" 85 "Kohler Power Systems" 88 "Hemisphere GPS" 135 "Airmar" 137 "Maretron" 140 "Lowrance" 144 "Mercury Marine" 147 "Nautibus Electronic" 148 "Blue Water Data" 154 "Westerbeke" 157 "ISSPRO" 161 "Offshore Systems (UK)" 163 "Evinrude/BRP" 165 "CPAC Systems" 168 "Xantrex Technology" 169 "Marlin Technologies" 172 "Yanmar Marine" 174 "Volvo Penta" 176 "Carling Technologies Inc. (Moritz Aerospace)" 185 "Beede Instruments" 192 "Floscan Instrument" 193 "Nobeltec" 198 "Mystic Valley Communications" 199 "Actia" 201 "Disenos Y Technologia" 211 "Digital Switching Systems" 215 "Xintex/Atena" 224 "EMMI NETWORK" 228 "ZF" 229 "Garmin" 233 "Yacht Monitoring Solutions" 235 "Sailormade Marine Telemetry/Tetra Technology" 243 "Eride" 257 "Honda Motor" 272 "Groco" 273 "Actisense" 274 "Amphenol LTW Technology" 275 "Navico" 283 "Hamilton Jet" 285 "Sea Recovery" 286 "Coelmo SRL Italy" 295 "BEP Marine" 304 "Empir Bus" 305 "NovAtel" 306 "Sleipner Motor" 307 "MBW Technologies" 315 "ICOM" 328 "Qwerty" 329 "Dief" 341 "Boening Automationstechnologie" 345 "Korean Maritime University" 351 "Thrane and Thrane" 355 "Mastervolt" 356 "Fischer Panda Generators" 358 "Victron Energy" 370 "Rolls Royce Marine" 373 "Electronic Design" 374 "Northern Lights" 378 "Glendinning" 381 "B & G" 384 "Rose Point Navigation Systems" 385 "Johnson Outdoors Marine Electronics Inc Geonav" 394 "Capi 2" 396 "Beyond Measure" 400 "Livorsi Marine" 404 "ComNav" 409 "Chetco" 419 "Fusion Electronics" 421 "Standard Horizon" 422 "True Heading" 426 "Egersund Marine Electronics" 427 "em-trak Marine Electronics" 431 "Tohatsu Co, JP" 437 "Digital Yacht" 438 "Comar Systems Limited" 440 "Cummins" 443 "VDO (aka Continental-Corporation)" 451 "Parker Hannifin aka Village Marine Tech" 459 "Alltek Marine Electronics" 460 "SAN GIORGIO S.E.I.N" 466 "Veethree Electronics & Marine" 470 "SI-TEX Marine Electronics" 471 "Sea Cross Marine" 475 "GME aka Standard Communications" 476 "Humminbird Marine Electronics" 478 "Ocean Sat" 481 "Chetco Digital Instruments" 493 "Watcheye" 499 "Lcj Capteurs" 502 "Attwood Marine" 503 "Naviop S.R.L." 504 "Vesper Marine" 510 "Marinesoft" 513 "Simarine" 517 "NoLand Engineering" 518 "Transas USA" 529 "National Instruments Korea" 530 "National Marine Electronics Association" 532 "Onwa Marine" 540 "Webasto" 571 "Marinecraft (South Korea)" 573 "McMurdo Group aka Orolia" 578 "Advansea" 579 "KVH" 580 "San Jose Technology" 583 "Yacht Control" 586 "Suzuki Motor" 591 "US Coast Guard" 595 "Ship Module aka Customware" 600 "Aquatic AV" 605 "Aventics" 606 "Intellian" 612 "SamwonIT" 614 "Arlt Tecnologies" 637 "Bavaria Yachts" 641 "Diverse Yacht Services" 644 "Wema U.S.A dba KUS" 658 "Shenzhen Jiuzhou Himunication" 688 "Rockford" 699 "Harman International" 704 "JL Audio" 708 "Lars Thrane" 715 "Autonnic" 717 "Yacht Devices" 734 "REAP Systems" 735 "AEM Performance Electronics" 739 "LxNav" 741 "Littelfuse, Inc (formerly Carling Technologies)" 743 "DaeMyung" 744 "Woosung" 748 "ISOTTA IFRA srl" 773 "Clarion US" 776 "HMI Systems" 777 "Ocean Signal" 778 "Seakeeper" 781 "Poly Planar" 785 "Fischer Panda DE" 795 "Broyda Industries" 796 "Canadian Automotive" 797 "Tides Marine" 798 "Lumishore" 799 "Still Water Designs and Audio" 802 "BJ Technologies (Beneteau)" 803 "Gill Sensors" 811 "Blue Water Desalination" 815 "FLIR" 824 "Undheim Systems" 826 "Lewmar" 838 "TeamSurv" 844 "Fell Marine" 847 "Oceanvolt" 862 "Prospec" 868 "Data Panel" 890 "L3 Technologies" 894 "Rhodan Marine Systems" 896 "Nexfour Solutions" 905 "ASA Electronics" 909 "Marines Co (South Korea)" 911 "Nautic-on" 917 "Sentinel" 929 "JL Marine Systems" 930 "Ecotronix" 944 "Zontisa Marine" 951 "EXOR International" 962 "Timbolier Industries" 963 "TJC Micro" 968 "Cox Powertrain" 969 "Blue Seas" 981 "Kobelt Manufacturing" 992 "Blue Ocean IOT" 997 "Xenta Systems" 999 "Signal K" 1004 "Ultraflex" 1008 "Lintest SmartBoat" 1011 "Soundmax" 1020 "Team Italia Marine (Onyx Marine Automation s.r.l)" 1021 "Entratech" 1022 "ITC" 1029 "The Marine Guardian" 1047 "Sonic" 1051 "ProNav" 1053 "Vetus Maxwell INC." 1056 "Lithium Pros" 1059 "Boatrax" 1062 "Marol Co ltd" 1065 "CALYPSO Instruments" 1066 "Spot Zero Water" 1069 "Lithionics Battery" 1070 "Quick-teck Electronics" 1075 "Uniden America" 1083 "Nauticoncept" 1084 "Shadow-Caster LED lighting" 1085 "Wet Sounds" 1088 "E-T-A Circuit Breakers" 1092 "Scheiber" 1100 "Smart Yachts International Limited" 1109 "Dockmate" 1114 "Bobs Machine" 1118 "L3Harris ASV" 1119 "Balmar" 1120 "Elettromedia" 1127 "Electromaax" 1140 "Across Oceans Systems" 1145 "Kiwi Yachting" 1150 "BSB Artificial Intelligence" 1151 "Orca Technologies" 1154 "TBS Electronics" 1158 "Technoton Electroics" 1160 "MG Energy Systems" 1169 "Sea Machine Robotics" 1171 "Vista Manufacturing" 1183 "Zipwake" 1186 "Sailmon" 1192 "Airmoniq Pro Kft" 1194 "Sierra Marine" 1200 "Xinuo Information Technology (Xiamen)" 1218 "Septentrio" 1233 "NKE Marine Electronics" 1238 "SuperTrack Aps" 1239 "Honda Electronics" 1245 "Raritan Engineering" 1249 "Integrated Power Solutions AG" 1260 "Interactive Technologies" 1283 "LTG-Tech" 1299 "Energy Solutions (UK)" 1300 "WATT Fuel Cell" 1302 "Pro Mainer" 1305 "Dragonfly Energy" 1306 "Koden Electronics" 1311 "Humphree" 1316 "Hinkley Yachts" 1317 "Global Marine Management GmbH (GMM)" 1320 "Triskel Marine" 1330 "Warwick Control Technologies" 1331 "Dolphin Charger" 1337 "Barnacle Systems" 1348 "Radian IoT" 1353 "Ocean LED Marine" 1359 "BluNav" 1361 "OVA (Nantong Saiyang Electronics Co., Ltd)" 1368 "RAD Propulsion" 1369 "Electric Yacht" 1372 "Elco Motor Yachts" 1384 "Tecnoseal Foundry S.r.l" 1385 "Pro Charging Systems" 1389 "EVEX" 1398 "Gobius Sensor Technology" 1403 "Arco Marine" 1408 "Lenco Marine" 1413 "Naocontrol" 1417 "Revatek" 1438 "Aeolionics" 1439 "PredictWind" 1440 "Egis Mobile Electric" 1445 "Starboard Yacht Group" 1446 "Roswell Marine" 1451 "ePropulsion (Guangdong ePropulsion Technology Ltd.)" 1452 "Micro-Air" 1453 "Vital Battery" 1458 "Ride Controller" 1460 "Tocaro Blue" 1461 "Vanquish Yachts" 1471 "FT Technologies" 1478 "Alps Alpine" 1481 "E-Force Marine" 1482 "CMC Marine" 1483 "Nanjing Sandemarine Information Technology" 1850 "Teleflex Marine (SeaStar Solutions)" 1851 "Raymarine" 1852 "Navionics" 1853 "Japan Radio" 1854 "Northstar Technologies" 1855 "Furuno" 1856 "Trimble" 1857 "Simrad" 1858 "Litton" 1859 "Kvasar" 1860 "MMP" 1861 "Vector Cantech" 1862 "Yamaha Marine" 1863 "Faria Instruments" ;
VAL_ 2650742528 Industry_Code 0 "Global" 1 "Highway" 2 "Agriculture" 3 "Construction" 4 "Marine Industry" 5 "Industrial" ;
VAL_ 2583633664 Manufacturer_Code 69 "ARKS Enterprises" 78 "FW Murphy/Enovation Controls" 80 "Twin Disc" 85 "Kohler Power Systems" 88 "Hemisphere GPS" 135 "Airmar" 137 "Maretron" 140 "Lowrance" 144 "Mercury Marine" 147 "Nautibus Electronic" 148 "Blue Water Data" 154 "Westerbeke" 157 "ISSPRO" 161 "Offshore Systems (UK)" 163 "Evinrude/BRP" 165 "CPAC Systems" 168 "Xantrex Technology" 169 "Marlin Technologies" 172 "Yanmar Marine" 174 "Volvo Penta" 176 "Carling Technologies Inc. (Moritz Aerospace)" 185 "Beede Instruments" 192 "Floscan Instrument" 193 "Nobeltec" 198 "Mystic Valley Communications" 199 "Actia" 201 "Disenos Y Technologia" 211 "Digital Switching Systems" 215 "Xintex/Atena" 224 "EMMI NETWORK" 228 "ZF" 229 "Garmin" 233 "Yacht Monitoring Solutions" 235 "Sailormade Marine Telemetry/Tetra Technology" 243 "Eride" 257 "Honda Motor" 272 "Groco" 273 "Actisense" 274 "Amphenol LTW Technology" 275 "Navico" 283 "Hamilton Jet" 285 "Sea Recovery" 286 "Coelmo SRL Italy" 295 "BEP Marine" 304 "Empir Bus" 305 "NovAtel" 306 "Sleipner Motor" 307 "MBW Technologies" 315 "ICOM" 328 "Qwerty" 329 "Dief" 341 "Boening Automationstechnologie" 345 "Korean Maritime University" 351 "Thrane and Thrane" 355 "Mastervolt" 356 "Fischer Panda Generators" 358 "Victron Energy" 370 "Rolls Royce Marine" 373 "Electronic Design" 374 "Northern Lights" 378 "Glendinning" 381 "B & G" 384 "Rose Point Navigation Systems" 385 "Johnson Outdoors Marine Electronics Inc Geonav" 394 "Capi 2" 396 "Beyond Measure" 400 "Livorsi Marine" 404 "ComNav" 409 "Chetco" 419 "Fusion Electronics" 421 "Standard Horizon" 422 "True Heading" 426 "Egersund Marine Electronics" 427 "em-trak Marine Electronics" 431 "Tohatsu Co, JP" 437 "Digital Yacht" 438 "Comar Systems Limited" 440 "Cummins" 443 "VDO (aka Continental-Corporation)" 451 "Parker Hannifin aka Village Marine Tech" 459 "Alltek Marine Electronics" 460 "SAN GIORGIO S.E.I.N" 466 "Veethree Electronics & Marine" 470 "SI-TEX Marine Electronics" 471 "Sea Cross Marine" 475 "GME aka Standard Communications" 476 "Humminbird Marine Electronics" 478 "Ocean Sat" 481 "Chetco Digital Instruments" 493 "Watcheye" 499 "Lcj Capteurs" 502 "Attwood Marine" 503 "Naviop S.R.L." 504 "Vesper Marine" 510 "Marinesoft" 513 "Simarine" 517 "NoLand Engineering" 518 "Transas USA" 529 "National Instruments Korea" 530 "National Marine Electronics Association" 532 "Onwa Marine" 540 "Webasto" 571 "Marinecraft (South Korea)" 573 "McMurdo Group aka Orolia" 578 "Advansea" 579 "KVH" 580 "San Jose Technology" 583 "Yacht Control" 586 "Suzuki Motor" 591 "US Coast Guard" 595 "Ship Module aka Customware" 600 "Aquatic AV" 605 "Aventics" 606 "Intellian" 612 "SamwonIT" 614 "Arlt Tecnologies" 637 "Bavaria Yachts" 641 "Diverse Yacht Services" 644 "Wema U.S.A dba KUS" 658 "Shenzhen Jiuzhou Himunication" 688 "Rockford" 699 "Harman International" 704 "JL Audio" 708 "Lars Thrane" 715 "Autonnic" 717 "Yacht Devices" 734 "REAP Systems" 735 "AEM Performance Electronics" 739 "LxNav" 741 "Littelfuse, Inc (formerly Carling Technologies)" 743 "DaeMyung" 744 "Woosung" 748 "ISOTTA IFRA srl" 773 "Clarion US" 776 "HMI Systems" 777 "Ocean Signal" 778 "Seakeeper" 781 "Poly Planar" 785 "Fischer Panda DE" 795 "Broyda Industries" 796 "Canadian Automotive" 797 "Tides Marine" 798 "Lumishore" 799 "Still Water Designs and Audio" 802 "BJ Technologies (Beneteau)" 803 "Gill Sensors" 811 "Blue Water Desalination" 815 "FLIR" 824 "Undheim Systems" 826 "Lewmar" 838 "TeamSurv" 844 "Fell Marine" 847 "Oceanvolt" 862 "Prospec" 868 "Data Panel" 890 "L3 Technologies" 894 "Rhodan Marine Systems" 896 "Nexfour Solutions" 905 "ASA Electronics" 909 "Marines Co (South Korea)" 911 "Nautic-on" 917 "Sentinel" 929 "JL Marine Systems" 930 "Ecotronix" 944 "Zontisa Marine" 951 "EXOR International" 962 "Timbolier Industries" 963 "TJC Micro" 968 "Cox Powertrain" 969 "Blue Seas" 981 "Kobelt Manufacturing" 992 "Blue Ocean IOT" 997 "Xenta Systems" 999 "Signal K" 1004 "Ultraflex" 1008 "Lintest SmartBoat" 1011 "Soundmax" 1020 "Team Italia Marine (Onyx Marine Automation s.r.l)" 1021 "Entratech" 1022 "ITC" 1029 "The Marine Guardian" 1047 "Sonic" 1051 "ProNav" 1053 "Vetus Maxwell INC." 1056 "Lithium Pros" 1059 "Boatrax" 1062 "Marol Co ltd" 1065 "CALYPSO Instruments" 1066 "Spot Zero Water" 1069 "Lithionics Battery" 1070 "Quick-teck Electronics" 1075 "Uniden America" 1083 "Nauticoncept" 1084 "Shadow-Caster LED lighting" 1085 "Wet Sounds" 1088 "E-T-A Circuit Breakers" 1092 "Scheiber" 1100 "Smart Yachts International Limited" 1109 "Dockmate" 1114 "Bobs Machine" 1118 "L3Harris ASV" 1119 "Balmar" 1120 "Elettromedia" 1127 "Electromaax" 1140 "Across Oceans Systems" 1145 "Kiwi Yachting" 1150 "BSB Artificial Intelligence" 1151 "Orca Technologies" 1154 "TBS Electronics" 1158 "Technoton Electroics" 1160 "MG Energy Systems" 1169 "Sea Machine Robotics" 1171 "Vista Manufacturing" 1183 "Zipwake" 1186 "Sailmon" 1192 "Airmoniq Pro Kft" 1194 "Sierra Marine" 1200 "Xinuo Information Technology (Xiamen)" 1218 "Septentrio" 1233 "NKE Marine Electronics" 1238 "SuperTrack Aps" 1239 "Honda Electronics" 1245 "Raritan Engineering" 1249 "Integrated Power Solutions AG" 1260 "Interactive Technologies" 1283 "LTG-Tech" 1299 "Energy Solutions (UK)" 1300 "WATT Fuel Cell" 1302 "Pro Mainer" 1305 "Dragonfly Energy" 1306 "Koden Electronics" 1311 "Humphree" 1316 "Hinkley Yachts" 1317 "Global Marine Management GmbH (GMM)" 1320 "Triskel Marine" 1330 "Warwick Control Technologies" 1331 "Dolphin Charger" 1337 "Barnacle Systems" 1348 "Radian IoT" 1353 "Ocean LED Marine" 1359 "BluNav" 1361 "OVA (Nantong Saiyang Electronics Co., Ltd)" 1368 "RAD Propulsion" 1369 "Electric Yacht" 1372 "Elco Motor Yachts" 1384 "Tecnoseal Foundry S.r.l" 1385 "Pro Charging Systems" 1389 "EVEX" 1398 "Gobius Sensor Technology" 1403 "Arco Marine" 1408 "Lenco Marine" 1413 "Naocontrol" 1417 "Revatek" 1438 "Aeolionics" 1439 "PredictWind" 1440 "Egis Mobile Electric" 1445 "Starboard Yacht Group" 1446 "Roswell Marine" 1451 "ePropulsion (Guangdong ePropulsion Technology Ltd.)" 1452 "Micro-Air" 1453 "Vital Battery" 1458 "Ride Controller" 1460 "Tocaro Blue" 1461 "Vanquish Yachts" 1471 "FT Technologies" 1478 "Alps Alpine" 1481 "E-Force Marine" 1482 "CMC Marine" 1483 "Nanjing Sandemarine Information Technology" 1850 "Teleflex Marine (SeaStar Solutions)" 1851 "Raymarine" 1852 "Navionics" 1853 "Japan Radio" 1854 "Northstar Technologies" 1855 "Furuno" 1856 "Trimble" 1857 "Simrad" 1858 "Litton" 1859 "Kvasar" 1860 "MMP" 1861 "Vector Cantech" 1862 "Yamaha Marine" 1863 "Faria Instruments" ;
VAL_ 2583633664 Industry_Code 0 "Global" 1 "Highway" 2 "Agriculture" 3 "Construction" 4 "Marine Industry" 5 "Industrial" ;
VAL_ 2650742784 Manufacturer_Code 69 "ARKS Enterprises" 78 "FW Murphy/Enovation Controls" 80 "Twin Disc" 85 "Kohler Power Systems" 88 "Hemisphere GPS" 135 "Airmar" 137 "Maretron" 140 "Lowrance" 144 "Mercury Marine" 147 "Nautibus Electronic" 148 "Blue Water Data" 154 "Westerbeke" 157 "ISSPRO" 161 "Offshore Systems (UK)" 163 "Evinrude/BRP" 165 "CPAC Systems" 168 "Xantrex Technology" 169 "Marlin Technologies" 172 "Yanmar Marine" 174 "Volvo Penta" 176 "Carling Technologies Inc. (Moritz Aerospace)" 185 "Beede Instruments" 192 "Floscan Instrument" 193 "Nobeltec" 198 "Mystic Valley Communications" 199 "Actia" 201 "Disenos Y Technologia" 211 "Digital Switching Systems" 215 "Xintex/Atena" 224 "EMMI NETWORK" 228 "ZF" 229 "Garmin" 233 "Yacht Monitoring Solutions" 235 "Sailormade Marine Telemetry/Tetra Technology" 243 "Eride" 257 "Honda Motor" 272 "Groco" 273 "Actisense" 274 "Amphenol LTW Technology" 275 "Navico" 283 "Hamilton Jet" 285 "Sea Recovery" 286 "Coelmo SRL Italy" 295 "BEP Marine" 304 "Empir Bus" 305 "NovAtel" 306 "Sleipner Motor" 307 "MBW Technologies" 315 "ICOM" 328 "Qwerty" 329 "Dief" 341 "Boening Automationstechnologie" 345 "Korean Maritime University" 351 "Thrane and Thrane" 355 "Mastervolt" 356 "Fischer Panda Generators" 358 "Victron Energy" 370 "Rolls Royce Marine" 373 "Electronic Design" 374 "Northern Lights" 378 "Glendinning" 381 "B & G" 384 "Rose Point Navigation Systems" 385 "Johnson Outdoors Marine Electronics Inc Geonav" 394 "Capi 2" 396 "Beyond Measure" 400 "Livorsi Marine" 404 "ComNav" 409 "Chetco" 419 "Fusion Electronics" 421 "Standard Horizon" 422 "True Heading" 426 "Egersund Marine Electronics" 427 "em-trak Marine Electronics" 431 "Tohatsu Co, JP" 437 "Digital Yacht" 438 "Comar Systems Limited" 440 "Cummins" 443 "VDO (aka Continental-Corporation)" 451 "Parker Hannifin aka Village Marine Tech" 459 "Alltek Marine Electronics" 460 "SAN GIORGIO S.E.I.N" 466 "Veethree Electronics & Marine" 470 "SI-TEX Marine Electronics" 471 "Sea Cross Marine" 475 "GME aka Standard Communications" 476 "Humminbird Marine Electronics" 478 "Ocean Sat" 481 "Chetco Digital Instruments" 493 "Watcheye" 499 "Lcj Capteurs" 502 "Attwood Marine" 503 "Naviop S.R.L." 504 "Vesper Marine" 510 "Marinesoft" 513 "Simarine" 517 "NoLand Engineering" 518 "Transas USA" 529 "National Instruments Korea" 530 "National Marine Electronics Association" 532 "Onwa Marine" 540 "Webasto" 571 "Marinecraft (South Korea)" 573 "McMurdo Group aka Orolia" 578 "Advansea" 579 "KVH" 580 "San Jose Technology" 583 "Yacht Control" 586 "Suzuki Motor" 591 "US Coast Guard" 595 "Ship Module aka Customware" 600 "Aquatic AV" 605 "Aventics" 606 "Intellian" 612 "SamwonIT" 614 "Arlt Tecnologies" 637 "Bavaria Yachts" 641 "Diverse Yacht Services" 644 "Wema U.S.A dba KUS" 658 "Shenzhen Jiuzhou Himunication" 688 "Rockford" 699 "Harman International" 704 "JL Audio" 708 "Lars Thrane" 715 "Autonnic" 717 "Yacht Devices" 734 "REAP Systems" 735 "AEM Performance Electronics" 739 "LxNav" 741 "Littelfuse, Inc (formerly Carling Technologies)" 743 "DaeMyung" 744 "Woosung" 748 "ISOTTA IFRA srl" 773 "Clarion US" 776 "HMI Systems" 777 "Ocean Signal" 778 "Seakeeper" 781 "Poly Planar" 785 "Fischer Panda DE" 795 "Broyda Industries" 796 "Canadian Automotive" 797 "Tides Marine" 798 "Lumishore" 799 "Still Water Designs and Audio" 802 "BJ Technologies (Beneteau)" 803 "Gill Sensors" 811 "Blue Water Desalination" 815 "FLIR" 824 "Undheim Systems" 826 "Lewmar" 838 "TeamSurv" 844 "Fell Marine" 847 "Oceanvolt" 862 "Prospec" 868 "Data Panel" 890 "L3 Technologies" 894 "Rhodan Marine Systems" 896 "Nexfour Solutions" 905 "ASA Electronics" 909 "Marines Co (South Korea)" 911 "Nautic-on" 917 "Sentinel" 929 "JL Marine Systems" 930 "Ecotronix" 944 "Zontisa Marine" 951 "EXOR International" 962 "Timbolier Industries" 963 "TJC Micro" 968 "Cox Powertrain" 969 "Blue Seas" 981 "Kobelt Manufacturing" 992 "Blue Ocean IOT" 997 "Xenta Systems" 999 "Signal K" 1004 "Ultraflex" 1008 "Lintest SmartBoat" 1011 "Soundmax" 1020 "Team Italia Marine (Onyx Marine Automation s.r.l)" 1021 "Entratech" 1022 "ITC" 1029 "The Marine Guardian" 1047 "Sonic" 1051 "ProNav" 1053 "Vetus Maxwell INC." 1056 "Lithium Pros" 1059 "Boatrax" 1062 "Marol Co ltd" 1065 "CALYPSO Instruments" 1066 "Spot Zero Water" 1069 "Lithionics Battery" 1070 "Quick-teck Electronics" 1075 "Uniden America" 1083 "Nauticoncept" 1084 "Shadow-Caster LED lighting" 1085 "Wet Sounds" 1088 "E-T-A Circuit Breakers" 1092 "Scheiber" 1100 "Smart Yachts International Limited" 1109 "Dockmate" 1114 "Bobs Machine" 1118 "L3Harris ASV" 1119 "Balmar" 1120 "Elettromedia" 1127 "Electromaax" 1140 "Across Oceans Systems" 1145 "Kiwi Yachting" 1150 "BSB Artificial Intelligence" 1151 "Orca Technologies" 1154 "TBS Electronics" 1158 "Technoton Electroics" 1160 "MG Energy Systems" 1169 "Sea Machine Robotics" 1171 "Vista Manufacturing" 1183 "Zipwake" 1186 "Sailmon" 1192 "Airmoniq Pro Kft" 1194 "Sierra Marine" 1200 "Xinuo Information Technology (Xiamen)" 1218 "Septentrio" 1233 "NKE Marine Electronics" 1238 "SuperTrack Aps" 1239 "Honda Electronics" 1245 "Raritan Engineering" 1249 "Integrated Power Solutions AG" 1260 "Interactive Technologies" 1283 "LTG-Tech" 1299 "Energy Solutions (UK)" 1300 "WATT Fuel Cell" 1302 "Pro Mainer" 1305 "Dragonfly Energy" 1306 "Koden Electronics" 1311 "Humphree" 1316 "Hinkley Yachts" 1317 "Global Marine Management GmbH (GMM)" 1320 "Triskel Marine" 1330 "Warwick Control Technologies" 1331 "Dolphin Charger" 1337 "Barnacle Systems" 1348 "Radian IoT" 1353 "Ocean LED Marine" 1359 "BluNav" 1361 "OVA (Nantong Saiyang Electronics Co., Ltd)" 1368 "RAD Propulsion" 1369 "Electric Yacht" 1372 "Elco Motor Yachts" 1384 "Tecnoseal Foundry S.r.l" 1385 "Pro Charging Systems" 1389 "EVEX" 1398 "Gobius Sensor Technology" 1403 "Arco Marine" 1408 "Lenco Marine" 1413 "Naocontrol" 1417 "Revatek" 1438 "Aeolionics" 1439 "PredictWind" 1440 "Egis Mobile Electric" 1445 "Starboard Yacht Group" 1446 "Roswell Marine" 1451 "ePropulsion (Guangdong ePropulsion Technology Ltd.)" 1452 "Micro-Air" 1453 "Vital Battery" 1458 "Ride Controller" 1460 "Tocaro Blue" 1461 "Vanquish Yachts" 1471 "FT Technologies" 1478 "Alps Alpine" 1481 "E-Force Marine" 1482 "CMC Marine" 1483 "Nanjing Sandemarine Information Technology" 1850 "Teleflex Marine (SeaStar Solutions)" 1851 "Raymarine" 1852 "Navionics" 1853 "Japan Radio" 1854 "Northstar Technologies" 1855 "Furuno" 1856 "Trimble" 1857 "Simrad" 1858 "Litton" 1859 "Kvasar" 1860 "MMP" 1861 "Vector Cantech" 1862 "Yamaha Marine" 1863 "Faria Instruments" ;
VAL_ 2650742784 Industry_Code 0 "Global" 1 "Highway" 2 "Agriculture" 3 "Construction" 4 "Marine Industry" 5 "Industrial" ;
VAL_ 2583634176 Manufacturer_Code 69 "ARKS Enterprises" 78 "FW Murphy/Enovation Controls" 80 "Twin Disc" 85 "Kohler Power Systems" 88 "Hemisphere GPS" 135 "Airmar" 137 "Maretron" 140 "Lowrance" 144 "Mercury Marine" 147 "Nautibus Electronic" 148 "Blue Water Data" 154 "Westerbeke" 157 "ISSPRO" 161 "Offshore Systems (UK)" 163 "Evinrude/BRP" 165 "CPAC Systems" 168 "Xantrex Technology" 169 "Marlin Technologies" 172 "Yanmar Marine" 174 "Volvo Penta" 176 "Carling Technologies Inc. (Moritz Aerospace)" 185 "Beede Instruments" 192 "Floscan Instrument" 193 "Nobeltec" 198 "Mystic Valley Communications" 199 "Actia" 201 "Disenos Y Technologia" 211 "Digital Switching Systems" 215 "Xintex/Atena" 224 "EMMI NETWORK" 228 "ZF" 229 "Garmin" 233 "Yacht Monitoring Solutions" 235 "Sailormade Marine Telemetry/Tetra Technology" 243 "Eride" 257 "Honda Motor" 272 "Groco" 273 "Actisense" 274 "Amphenol LTW Technology" 275 "Navico" 283 "Hamilton Jet" 285 "Sea Recovery" 286 "Coelmo SRL Italy" 295 "BEP Marine" 304 "Empir Bus" 305 "NovAtel" 306 "Sleipner Motor" 307 "MBW Technologies" 315 "ICOM" 328 "Qwerty" 329 "Dief" 341 "Boening Automationstechnologie" 345 "Korean Maritime University" 351 "Thrane and Thrane" 355 "Mastervolt" 356 "Fischer Panda Generators" 358 "Victron Energy" 370 "Rolls Royce Marine" 373 "Electronic Design" 374 "Northern Lights" 378 "Glendinning" 381 "B & G" 384 "Rose Point Navigation Systems" 385 "Johnson Outdoors Marine Electronics Inc Geonav" 394 "Capi 2" 396 "Beyond Measure" 400 "Livorsi Marine" 404 "ComNav" 409 "Chetco" 419 "Fusion Electronics" 421 "Standard Horizon" 422 "True Heading" 426 "Egersund Marine Electronics" 427 "em-trak Marine Electronics" 431 "Tohatsu Co, JP" 437 "Digital Yacht" 438 "Comar Systems Limited" 440 "Cummins" 443 "VDO (aka Continental-Corporation)" 451 "Parker Hannifin aka Village Marine Tech" 459 "Alltek Marine Electronics" 460 "SAN GIORGIO S.E.I.N" 466 "Veethree Electronics & Marine" 470 "SI-TEX Marine Electronics" 471 "Sea Cross Marine" 475 "GME aka Standard Communications" 476 "Humminbird Marine Electronics" 478 "Ocean Sat" 481 "Chetco Digital Instruments" 493 "Watcheye" 499 "Lcj Capteurs" 502 "Attwood Marine" 503 "Naviop S.R.L." 504 "Vesper Marine" 510 "Marinesoft" 513 "Simarine" 517 "NoLand Engineering" 518 "Transas USA" 529 "National Instruments Korea" 530 "National Marine Electronics Association" 532 "Onwa Marine" 540 "Webasto" 571 "Marinecraft (South Korea)" 573 "McMurdo Group aka Orolia" 578 "Advansea" 579 "KVH" 580 "San Jose Technology" 583 "Yacht Control" 586 "Suzuki Motor" 591 "US Coast Guard" 595 "Ship Module aka Customware" 600 "Aquatic AV" 605 "Aventics" 606 "Intellian" 612 "SamwonIT" 614 "Arlt Tecnologies" 637 "Bavaria Yachts" 641 "Diverse Yacht Services" 644 "Wema U.S.A dba KUS" 658 "Shenzhen Jiuzhou Himunication" 688 "Rockford" 699 "Harman International" 704 "JL Audio" 708 "Lars Thrane" 715 "Autonnic" 717 "Yacht Devices" 734 "REAP Systems" 735 "AEM Performance Electronics" 739 "LxNav" 741 "Littelfuse, Inc (formerly Carling Technologies)" 743 "DaeMyung" 744 "Woosung" 748 "ISOTTA IFRA srl" 773 "Clarion US" 776 "HMI Systems" 777 "Ocean Signal" 778 "Seakeeper" 781 "Poly Planar" 785 "Fischer Panda DE" 795 "Broyda Industries" 796 "Canadian Automotive" 797 "Tides Marine" 798 "Lumishore" 799 "Still Water Designs and Audio" 802 "BJ Technologies (Beneteau)" 803 "Gill Sensors" 811 "Blue Water Desalination" 815 "FLIR" 824 "Undheim Systems" 826 "Lewmar" 838 "TeamSurv" 844 "Fell Marine" 847 "Oceanvolt" 862 "Prospec" 868 "Data Panel" 890 "L3 Technologies" 894 "Rhodan Marine Systems" 896 "Nexfour Solutions" 905 "ASA Electronics" 909 "Marines Co (South Korea)" 911 "Nautic-on" 917 "Sentinel" 929 "JL Marine Systems" 930 "Ecotronix" 944 "Zontisa Marine" 951 "EXOR International" 962 "Timbolier Industries" 963 "TJC Micro" 968 "Cox Powertrain" 969 "Blue Seas" 981 "Kobelt Manufacturing" 992 "Blue Ocean IOT" 997 "Xenta Systems" 999 "Signal K" 1004 "Ultraflex" 1008 "Lintest SmartBoat" 1011 "Soundmax" 1020 "Team Italia Marine (Onyx Marine Automation s.r.l)" 1021 "Entratech" 1022 "ITC" 1029 "The Marine Guardian" 1047 "Sonic" 1051 "ProNav" 1053 "Vetus Maxwell INC." 1056 "Lithium Pros" 1059 "Boatrax" 1062 "Marol Co ltd" 1065 "CALYPSO Instruments" 1066 "Spot Zero Water" 1069 "Lithionics Battery" 1070 "Quick-teck Electronics" 1075 "Uniden America" 1083 "Nauticoncept" 1084 "Shadow-Caster LED lighting" 1085 "Wet Sounds" 1088 "E-T-A Circuit Breakers" 1092 "Scheiber" 1100 "Smart Yachts International Limited" 1109 "Dockmate" 1114 "Bobs Machine" 1118 "L3Harris ASV" 1119 "Balmar" 1120 "Elettromedia" 1127 "Electromaax" 1140 "Across Oceans Systems" 1145 "Kiwi Yachting" 1150 "BSB Artificial Intelligence" 1151 "Orca Technologies" 1154 "TBS Electronics" 1158 "Technoton Electroics" 1160 "MG Energy Systems" 1169 "Sea Machine Robotics" 1171 "Vista Manufacturing" 1183 "Zipwake" 1186 "Sailmon" 1192 "Airmoniq Pro Kft" 1194 "Sierra Marine" 1200 "Xinuo Information Technology (Xiamen)" 1218 "Septentrio" 1233 "NKE Marine Electronics" 1238 "SuperTrack Aps" 1239 "Honda Electronics" 1245 "Raritan Engineering" 1249 "Integrated Power Solutions AG" 1260 "Interactive Technologies" 1283 "LTG-Tech" 1299 "Energy Solutions (UK)" 1300 "WATT Fuel Cell" 1302 "Pro Mainer" 1305 "Dragonfly Energy" 1306 "Koden Electronics" 1311 "Humphree" 1316 "Hinkley Yachts" 1317 "Global Marine Management GmbH (GMM)" 1320 "Triskel Marine" 1330 "Warwick Control Technologies" 1331 "Dolphin Charger" 1337 "Barnacle Systems" 1348 "Radian IoT" 1353 "Ocean LED Marine" 1359 "BluNav" 1361 "OVA (Nantong Saiyang Electronics Co., Ltd)" 1368 "RAD Propulsion" 1369 "Electric Yacht" 1372 "Elco Motor Yachts" 1384 "Tecnoseal Foundry S.r.l" 1385 "Pro Charging Systems" 1389 "EVEX" 1398 "Gobius Sensor Technology" 1403 "Arco Marine" 1408 "Lenco Marine" 1413 "Naocontrol" 1417 "Revatek" 1438 "Aeolionics" 1439 "PredictWind" 1440 "Egis Mobile Electric" 1445 "Starboard Yacht Group" 1446 "Roswell Marine" 1451 "ePropulsion (Guangdong ePropulsion Technology Ltd.)" 1452 "Micro-Air" 1453 "Vital Battery" 1458 "Ride Controller" 1460 "Tocaro Blue" 1461 "Vanquish Yachts" 1471 "FT Technologies" 1478 "Alps Alpine" 1481 "E-Force Marine" 1482 "CMC Marine" 1483 "Nanjing Sandemarine Information Technology" 1850 "Teleflex Marine (SeaStar Solutions)" 1851 "Raymarine" 1852 "Navionics" 1853 "Japan Radio" 1854 "Northstar Technologies" 1855 "Furuno" 1856 "Trimble" 1857 "Simrad" 1858 "Litton" 1859 "Kvasar" 1860 "MMP" 1861 "Vector Cantech" 1862 "Yamaha Marine" 1863 "Faria Instruments" ;
VAL_ 2583634176 Industry_Code 0 "Global" 1 "Highway" 2 "Agriculture" 3 "Construction" 4 "Marine Industry" 5 "Industrial" ;
VAL_ 2315198976 Manufacturer_Code 69 "ARKS Enterprises" 78 "FW Murphy/Enovation Controls" 80 "Twin Disc" 85 "Kohler Power Systems" 88 "Hemisphere GPS" 135 "Airmar" 137 "Maretron" 140 "Lowrance" 144 "Mercury Marine" 147 "Nautibus Electronic" 148 "Blue Water Data" 154 "Westerbeke" 157 "ISSPRO" 161 "Offshore Systems (UK)" 163 "Evinrude/BRP" 165 "CPAC Systems" 168 "Xantrex Technology" 169 "Marlin Technologies" 172 "Yanmar Marine" 174 "Volvo Penta" 176 "Carling Technologies Inc. (Moritz Aerospace)" 185 "Beede Instruments" 192 "Floscan Instrument" 193 "Nobeltec" 198 "Mystic Valley Communications" 199 "Actia" 201 "Disenos Y Technologia" 211 "Digital Switching Systems" 215 "Xintex/Atena" 224 "EMMI NETWORK" 228 "ZF" 229 "Garmin" 233 "Yacht Monitoring Solutions" 235 "Sailormade Marine Telemetry/Tetra Technology" 243 "Eride" 257 "Honda Motor" 272 "Groco" 273 "Actisense" 274 "Amphenol LTW Technology" 275 "Navico" 283 "Hamilton Jet" 285 "Sea Recovery" 286 "Coelmo SRL Italy" 295 "BEP Marine" 304 "Empir Bus" 305 "NovAtel" 306 "Sleipner Motor" 307 "MBW Technologies" 315 "ICOM" 328 "Qwerty" 329 "Dief" 341 "Boening Automationstechnologie" 345 "Korean Maritime University" 351 "Thrane and Thrane" 355 "Mastervolt" 356 "Fischer Panda Generators" 358 "Victron Energy" 370 "Rolls Royce Marine" 373 "Electronic Design" 374 "Northern Lights" 378 "Glendinning" 381 "B & G" 384 "Rose Point Navigation Systems" 385 "Johnson Outdoors Marine Electronics Inc Geonav" 394 "Capi 2" 396 "Beyond Measure" 400 "Livorsi Marine" 404 "ComNav" 409 "Chetco" 419 "Fusion Electronics" 421 "Standard Horizon" 422 "True Heading" 426 "Egersund Marine Electronics" 427 "em-trak Marine Electronics" 431 "Tohatsu Co, JP" 437 "Digital Yacht" 438 "Comar Systems Limited" 440 "Cummins" 443 "VDO (aka Continental-Corporation)" 451 "Parker Hannifin aka Village Marine Tech" 459 "Alltek Marine Electronics" 460 "SAN GIORGIO S.E.I.N" 466 "Veethree Electronics & Marine" 470 "SI-TEX Marine Electronics" 471 "Sea Cross Marine" 475 "GME aka Standard Communications" 476 "Humminbird Marine Electronics" 478 "Ocean Sat" 481 "Chetco Digital Instruments" 493 "Watcheye" 499 "Lcj Capteurs" 502 "Attwood Marine" 503 "Naviop S.R.L." 504 "Vesper Marine" 510 "Marinesoft" 513 "Simarine" 517 "NoLand Engineering" 518 "Transas USA" 529 "National Instruments Korea" 530 "National Marine Electronics Association" 532 "Onwa Marine" 540 "Webasto" 571 "Marinecraft (South Korea)" 573 "McMurdo Group aka Orolia" 578 "Advansea" 579 "KVH" 580 "San Jose Technology" 583 "Yacht Control" 586 "Suzuki Motor" 591 "US Coast Guard" 595 "Ship Module aka Customware" 600 "Aquatic AV" 605 "Aventics" 606 "Intellian" 612 "SamwonIT" 614 "Arlt Tecnologies" 637 "Bavaria Yachts" 641 "Diverse Yacht Services" 644 "Wema U.S.A dba KUS" 658 "Shenzhen Jiuzhou Himunication" 688 "Rockford" 699 "Harman International" 704 "JL Audio" 708 "Lars Thrane" 715 "Autonnic" 717 "Yacht Devices" 734 "REAP Systems" 735 "AEM Performance Electronics" 739 "LxNav" 741 "Littelfuse, Inc (formerly Carling Technologies)" 743 "DaeMyung" 744 "Woosung" 748 "ISOTTA IFRA srl" 773 "Clarion US" 776 "HMI Systems" 777 "Ocean Signal" 778 "Seakeeper" 781 "Poly Planar" 785 "Fischer Panda DE" 795 "Broyda Industries" 796 "Canadian Automotive" 797 "Tides Marine" 798 "Lumishore" 799 "Still Water Designs and Audio" 802 "BJ Technologies (Beneteau)" 803 "Gill Sensors" 811 "Blue Water Desalination" 815 "FLIR" 824 "Undheim Systems" 826 "Lewmar" 838 "TeamSurv" 844 "Fell Marine" 847 "Oceanvolt" 862 "Prospec" 868 "Data Panel" 890 "L3 Technologies" 894 "Rhodan Marine Systems" 896 "Nexfour Solutions" 905 "ASA Electronics" 909 "Marines Co (South Korea)" 911 "Nautic-on" 917 "Sentinel" 929 "JL Marine Systems" 930 "Ecotronix" 944 "Zontisa Marine" 951 "EXOR International" 962 "Timbolier Industries" 963 "TJC Micro" 968 "Cox Powertrain" 969 "Blue Seas" 981 "Kobelt Manufacturing" 992 "Blue Ocean IOT" 997 "Xenta Systems" 999 "Signal K" 1004 "Ultraflex" 1008 "Lintest SmartBoat" 1011 "Soundmax" 1020 "Team Italia Marine (Onyx Marine Automation s.r.l)" 1021 "Entratech" 1022 "ITC" 1029 "The Marine Guardian" 1047 "Sonic" 1051 "ProNav" 1053 "Vetus Maxwell INC." 1056 "Lithium Pros" 1059 "Boatrax" 1062 "Marol Co ltd" 1065 "CALYPSO Instruments" 1066 "Spot Zero Water" 1069 "Lithionics Battery" 1070 "Quick-teck Electronics" 1075 "Uniden America" 1083 "Nauticoncept" 1084 "Shadow-Caster LED lighting" 1085 "Wet Sounds" 1088 "E-T-A Circuit Breakers" 1092 "Scheiber" 1100 "Smart Yachts International Limited" 1109 "Dockmate" 1114 "Bobs Machine" 1118 "L3Harris ASV" 1119 "Balmar" 1120 "Elettromedia" 1127 "Electromaax" 1140 "Across Oceans Systems" 1145 "Kiwi Yachting" 1150 "BSB Artificial Intelligence" 1151 "Orca Technologies" 1154 "TBS Electronics" 1158 "Technoton Electroics" 1160 "MG Energy Systems" 1169 "Sea Machine Robotics" 1171 "Vista Manufacturing" 1183 "Zipwake" 1186 "Sailmon" 1192 "Airmoniq Pro Kft" 1194 "Sierra Marine" 1200 "Xinuo Information Technology (Xiamen)" 1218 "Septentrio" 1233 "NKE Marine Electronics" 1238 "SuperTrack Aps" 1239 "Honda Electronics" 1245 "Raritan Engineering" 1249 "Integrated Power Solutions AG" 1260 "Interactive Technologies" 1283 "LTG-Tech" 1299 "Energy Solutions (UK)" 1300 "WATT Fuel Cell" 1302 "Pro Mainer" 1305 "Dragonfly Energy" 1306 "Koden Electronics" 1311 "Humphree" 1316 "Hinkley Yachts" 1317 "Global Marine Management GmbH (GMM)" 1320 "Triskel Marine" 1330 "Warwick Control Technologies" 1331 "Dolphin Charger" 1337 "Barnacle Systems" 1348 "Radian IoT" 1353 "Ocean LED Marine" 1359 "BluNav" 1361 "OVA (Nantong Saiyang Electronics Co., Ltd)" 1368 "RAD Propulsion" 1369 "Electric Yacht" 1372 "Elco Motor Yachts" 1384 "Tecnoseal Foundry S.r.l" 1385 "Pro Charging Systems" 1389 "EVEX" 1398 "Gobius Sensor Technology" 1403 "Arco Marine" 1408 "Lenco Marine" 1413 "Naocontrol" 1417 "Revatek" 1438 "Aeolionics" 1439 "PredictWind" 1440 "Egis Mobile Electric" 1445 "Starboard Yacht Group" 1446 "Roswell Marine" 1451 "ePropulsion (Guangdong ePropulsion Technology Ltd.)" 1452 "Micro-Air" 1453 "Vital Battery" 1458 "Ride Controller" 1460 "Tocaro Blue" 1461 "Vanquish Yachts" 1471 "FT Technologies" 1478 "Alps Alpine" 1481 "E-Force Marine" 1482 "CMC Marine" 1483 "Nanjing Sandemarine Information Technology" 1850 "Teleflex Marine (SeaStar Solutions)" 1851 "Raymarine" 1852 "Navionics" 1853 "Japan Radio" 1854 "Northstar Technologies" 1855 "Furuno" 1856 "Trimble" 1857 "Simrad" 1858 "Litton" 1859 "Kvasar" 1860 "MMP" 1861 "Vector Cantech" 1862 "Yamaha Marine" 1863 "Faria Instruments" ;
VAL_ 2315198976 Industry_Code 0 "Global" 1 "Highway" 2 "Agriculture" 3 "Construction" 4 "Marine Industry" 5 "Industrial" ;
VAL_ 2315198976 Network_Group 0 "None" 1 "Default" 2 "Group 1" 3 "Group 2" 4 "Group 3" 5 "Group 4" 6 "Group 5" 7 "Group 6" ;
VAL_ 2315198976 Event_Type 2 "Follow Up" 10 "AP Command" 23 "Timer" 31 "Siren" 36 "AIS vessel selected" 255 "Alarm" ;
VAL_ 2315198976 Command 56 "Deactivate" 57 "Activate" 58 "Acknowledge" 68 "Silence" 88 "Tack/Gybe Confirm" 104 "Alarm History" 107 "MOB Activated" 108 "MOB Cancelled" ;
VAL_ 2315198976 Alarm_ID 10 "Shallow water" 11 "Deep water" 12 "Anchor depth" 13 "True wind shift" 14 "True wind high" 15 "True wind low" 16 "Low boat speed" 17 "High voltage" 18 "Low voltage" 19 "Depth data missing" 20 "Wind data missing" 21 "Nav data missing" 22 "Heading missing" 23 "XTE" 24 "Rudder data missing" 25 "Rudder controller fault" 26 "No rudder response" 27 "Rudder drive overload" 28 "High internal temperature" 29 "AP clutch overload" 30 "AP clutch disengaged" 31 "High drive supply" 32 "Low drive supply" 33 "No active autopilot control unit" 34 "No autopilot computer" 35 "Memory fail" 36 "Water temp missing" 37 "Low water temp" 38 "High water temp" 39 "Water temp rate" 40 "Fish" 41 "No GPS fix" 42 "WAAS/DGPS" 45 "Arrival" 46 "Anchor" 47 "Fuel low" 48 "Fuel high" 49 "Tank low" 50 "Tank high" 51 "BEP" 52 "Waypoint radius" 53 "CPA" 54 "AIS range to vessel" 55 "AIS vessel lost" 56 "Vessel message" 57 "Lightning" 58 "Severe weather" 59 "Storm" 61 "Engine Check" 62 "Engine over temperature" 63 "Engine low oil pressure" 64 "Engine low oil level" 65 "Engine low fuel pressure" 66 "Engine low voltage" 67 "Engine low coolant level" 68 "Engine water flow" 69 "Engine water in fuel" 70 "Engine charge" 71 "Engine preheat" 72 "Engine high boost pressure" 73 "Engine rev limit" 74 "Engine EGR system" 75 "Engine throttle position" 76 "Engine emergency stop" 77 "Engine warning level 1" 78 "Engine warning level 2" 79 "Engine power reduction" 80 "Engine maintenance" 81 "Engine comm error" 82 "Engine throttle" 83 "Engine start protect" 84 "Engine shutting down" 85 "Transmission Check" 86 "Transmission over temperature" 87 "Transmission low oil pressure" 88 "Transmission low oil level" 89 "Sail drive" 96 "Fresh water low" 97 "Fresh water high" 98 "Gray water low" 99 "Gray water high" 100 "Live well low" 101 "Live well high" 102 "Oil low" 103 "Oil high" 104 "Black water low" 105 "Black water high" 106 "Weather data missing" 107 "AP Position data missing" 108 "AP Speed data missing" 109 "AP Depth data missing" 110 "AP Heading data missing" 111 "AP Nav data missing" 112 "AP Off course" 113 "AP Rudder data missing" 114 "AP Wind data missing" 115 "Radar guard zone" 116 "MARPA target lost" 117 "MARPA unavailable" 118 "Dangerous vessel" 119 "Radar error" 120 "CZone critical" 121 "CZone important" 122 "CZone standard" 123 "CZone warning" 124 "True wind shift" 125 "EVC Com Error" 126 "EVC override" 127 "High drive temperature" 128 "Drive inhibit" 129 "CAN bus supply overload" 130 "Drive ref voltage missing" 131 "Rudder limit" 132 "Compass difference" 133 "AP Low boat speed" 134 "Monitor compass missing" 135 "Cross track distance limit" 137 "End of route" 138 "Compass alignment" 139 "R.A.I.M" 141 "Off heading" 142 "Supply voltage" 143 "Low CAN bus voltage" 144 "CAN bus failure" 145 "Drive ready missing" 146 "Drive computer missing" 147 "External mode illegal" 148 "Rudder too slow" 149 "Wheel over" 150 "Thruster inhibited" 151 "Check heading" 152 "True wind speed high" 153 "Override" 154 "Speed through water rationality fault" 155 "No drives available" 156 "Fuel remaining low" 157 "Fuel remaining high" 158 "Generator Check" 159 "Generator over temperature" 160 "Generator low oil pressure" 161 "Generator low oil level" 162 "Generator low fuel pressure" 163 "Generator low voltage" 164 "Generator low coolant level" 165 "Generator water flow" 166 "Generator water in fuel" 167 "Generator charge" 168 "Generator preheat" 169 "Generator high boost pressure" 170 "Generator rev limit" 171 "Generator EGR system" 172 "Generator throttle position" 173 "Generator emergency stop" 174 "Generator warning level 1" 175 "Generator warning level 2" 176 "Generator power reduction" 177 "Generator maintenance" 178 "Generator comm error" 179 "Generator throttle" 180 "Generator start protect" 181 "Generator shutting down" 182 "Shallow aft depth" 183 "Forward range" 245 "Alarm source missing" 246 "External" 247 "EVC Com Error" 248 "Wind sensor battery low" 266 "Gasoline low" 267 "Gasoline high" 268 "Charging System" 269 "Seawater Flow" 270 "Water in Drive Seal" 272 "Turnover" 273 "Helm ECU Detect Failure" 274 "Joystick ECU Detect Failure" 275 "Drive ECU Detect Failure" 276 "Hot Transmission" 277 "Low Gear Oil Pressure" 278 "Low Drive Lub Oil Level" 285 "Check Thermostat" 287 "Track offset active" 385 "Navigation Not Supported" ;
VAL_ 2315198976 Manufacturer_Code 69 "ARKS Enterprises" 78 "FW Murphy/Enovation Controls" 80 "Twin Disc" 85 "Kohler Power Systems" 88 "Hemisphere GPS" 135 "Airmar" 137 "Maretron" 140 "Lowrance" 144 "Mercury Marine" 147 "Nautibus Electronic" 148 "Blue Water Data" 154 "Westerbeke" 157 "ISSPRO" 161 "Offshore Systems (UK)" 163 "Evinrude/BRP" 165 "CPAC Systems" 168 "Xantrex Technology" 169 "Marlin Technologies" 172 "Yanmar Marine" 174 "Volvo Penta" 176 "Carling Technologies Inc. (Moritz Aerospace)" 185 "Beede Instruments" 192 "Floscan Instrument" 193 "Nobeltec" 198 "Mystic Valley Communications" 199 "Actia" 201 "Disenos Y Technologia" 211 "Digital Switching Systems" 215 "Xintex/Atena" 224 "EMMI NETWORK" 228 "ZF" 229 "Garmin" 233 "Yacht Monitoring Solutions" 235 "Sailormade Marine Telemetry/Tetra Technology" 243 "Eride" 257 "Honda Motor" 272 "Groco" 273 "Actisense" 274 "Amphenol LTW Technology" 275 "Navico" 283 "Hamilton Jet" 285 "Sea Recovery" 286 "Coelmo SRL Italy" 295 "BEP Marine" 304 "Empir Bus" 305 "NovAtel" 306 "Sleipner Motor" 307 "MBW Technologies" 315 "ICOM" 328 "Qwerty" 329 "Dief" 341 "Boening Automationstechnologie" 345 "Korean Maritime University" 351 "Thrane and Thrane" 355 "Mastervolt" 356 "Fischer Panda Generators" 358 "Victron Energy" 370 "Rolls Royce Marine" 373 "Electronic Design" 374 "Northern Lights" 378 "Glendinning" 381 "B & G" 384 "Rose Point Navigation Systems" 385 "Johnson Outdoors Marine Electronics Inc Geonav" 394 "Capi 2" 396 "Beyond Measure" 400 "Livorsi Marine" 404 "ComNav" 409 "Chetco" 419 "Fusion Electronics" 421 "Standard Horizon" 422 "True Heading" 426 "Egersund Marine Electronics" 427 "em-trak Marine Electronics" 431 "Tohatsu Co, JP" 437 "Digital Yacht" 438 "Comar Systems Limited" 440 "Cummins" 443 "VDO (aka Continental-Corporation)" 451 "Parker Hannifin aka Village Marine Tech" 459 "Alltek Marine Electronics" 460 "SAN GIORGIO S.E.I.N" 466 "Veethree Electronics & Marine" 470 "SI-TEX Marine Electronics" 471 "Sea Cross Marine" 475 "GME aka Standard Communications" 476 "Humminbird Marine Electronics" 478 "Ocean Sat" 481 "Chetco Digital Instruments" 493 "Watcheye" 499 "Lcj Capteurs" 502 "Attwood Marine" 503 "Naviop S.R.L." 504 "Vesper Marine" 510 "Marinesoft" 513 "Simarine" 517 "NoLand Engineering" 518 "Transas USA" 529 "National Instruments Korea" 530 "National Marine Electronics Association" 532 "Onwa Marine" 540 "Webasto" 571 "Marinecraft (South Korea)" 573 "McMurdo Group aka Orolia" 578 "Advansea" 579 "KVH" 580 "San Jose Technology" 583 "Yacht Control" 586 "Suzuki Motor" 591 "US Coast Guard" 595 "Ship Module aka Customware" 600 "Aquatic AV" 605 "Aventics" 606 "Intellian" 612 "SamwonIT" 614 "Arlt Tecnologies" 637 "Bavaria Yachts" 641 "Diverse Yacht Services" 644 "Wema U.S.A dba KUS" 658 "Shenzhen Jiuzhou Himunication" 688 "Rockford" 699 "Harman International" 704 "JL Audio" 708 "Lars Thrane" 715 "Autonnic" 717 "Yacht Devices" 734 "REAP Systems" 735 "AEM Performance Electronics" 739 "LxNav" 741 "Littelfuse, Inc (formerly Carling Technologies)" 743 "DaeMyung" 744 "Woosung" 748 "ISOTTA IFRA srl" 773 "Clarion US" 776 "HMI Systems" 777 "Ocean Signal" 778 "Seakeeper" 781 "Poly Planar" 785 "Fischer Panda DE" 795 "Broyda Industries" 796 "Canadian Automotive" 797 "Tides Marine" 798 "Lumishore" 799 "Still Water Designs and Audio" 802 "BJ Technologies (Beneteau)" 803 "Gill Sensors" 811 "Blue Water Desalination" 815 "FLIR" 824 "Undheim Systems" 826 "Lewmar" 838 "TeamSurv" 844 "Fell Marine" 847 "Oceanvolt" 862 "Prospec" 868 "Data Panel" 890 "L3 Technologies" 894 "Rhodan Marine Systems" 896 "Nexfour Solutions" 905 "ASA Electronics" 909 "Marines Co (South Korea)" 911 "Nautic-on" 917 "Sentinel" 929 "JL Marine Systems" 930 "Ecotronix" 944 "Zontisa Marine" 951 "EXOR International" 962 "Timbolier Industries" 963 "TJC Micro" 968 "Cox Powertrain" 969 "Blue Seas" 981 "Kobelt Manufacturing" 992 "Blue Ocean IOT" 997 "Xenta Systems" 999 "Signal K" 1004 "Ultraflex" 1008 "Lintest SmartBoat" 1011 "Soundmax" 1020 "Team Italia Marine (Onyx Marine Automation s.r.l)" 1021 "Entratech" 1022 "ITC" 1029 "The Marine Guardian" 1047 "Sonic" 1051 "ProNav" 1053 "Vetus Maxwell INC." 1056 "Lithium Pros" 1059 "Boatrax" 1062 "Marol Co ltd" 1065 "CALYPSO Instruments" 1066 "Spot Zero Water" 1069 "Lithionics Battery" 1070 "Quick-teck Electronics" 1075 "Uniden America" 1083 "Nauticoncept" 1084 "Shadow-Caster LED lighting" 1085 "Wet Sounds" 1088 "E-T-A Circuit Breakers" 1092 "Scheiber" 1100 "Smart Yachts International Limited" 1109 "Dockmate" 1114 "Bobs Machine" 1118 "L3Harris ASV" 1119 "Balmar" 1120 "Elettromedia" 1127 "Electromaax" 1140 "Across Oceans Systems" 1145 "Kiwi Yachting" 1150 "BSB Artificial Intelligence" 1151 "Orca Technologies" 1154 "TBS Electronics" 1158 "Technoton Electroics" 1160 "MG Energy Systems" 1169 "Sea Machine Robotics" 1171 "Vista Manufacturing" 1183 "Zipwake" 1186 "Sailmon" 1192 "Airmoniq Pro Kft" 1194 "Sierra Marine" 1200 "Xinuo Information Technology (Xiamen)" 1218 "Septentrio" 1233 "NKE Marine Electronics" 1238 "SuperTrack Aps" 1239 "Honda Electronics" 1245 "Raritan Engineering" 1249 "Integrated Power Solutions AG" 1260 "Interactive Technologies" 1283 "LTG-Tech" 1299 "Energy Solutions (UK)" 1300 "WATT Fuel Cell" 1302 "Pro Mainer" 1305 "Dragonfly Energy" 1306 "Koden Electronics" 1311 "Humphree" 1316 "Hinkley Yachts" 1317 "Global Marine Management GmbH (GMM)" 1320 "Triskel Marine" 1330 "Warwick Control Technologies" 1331 "Dolphin Charger" 1337 "Barnacle Systems" 1348 "Radian IoT" 1353 "Ocean LED Marine" 1359 "BluNav" 1361 "OVA (Nantong Saiyang Electronics Co., Ltd)" 1368 "RAD Propulsion" 1369 "Electric Yacht" 1372 "Elco Motor Yachts" 1384 "Tecnoseal Foundry S.r.l" 1385 "Pro Charging Systems" 1389 "EVEX" 1398 "Gobius Sensor Technology" 1403 "Arco Marine" 1408 "Lenco Marine" 1413 "Naocontrol" 1417 "Revatek" 1438 "Aeolionics" 1439 "PredictWind" 1440 "Egis Mobile Electric" 1445 "Starboard Yacht Group" 1446 "Roswell Marine" 1451 "ePropulsion (Guangdong ePropulsion Technology Ltd.)" 1452 "Micro-Air" 1453 "Vital Battery" 1458 "Ride Controller" 1460 "Tocaro Blue" 1461 "Vanquish Yachts" 1471 "FT Technologies" 1478 "Alps Alpine" 1481 "E-Force Marine" 1482 "CMC Marine" 1483 "Nanjing Sandemarine Information Technology" 1850 "Teleflex Marine (SeaStar Solutions)" 1851 "Raymarine" 1852 "Navionics" 1853 "Japan Radio" 1854 "Northstar Technologies" 1855 "Furuno" 1856 "Trimble" 1857 "Simrad" 1858 "Litton" 1859 "Kvasar" 1860 "MMP" 1861 "Vector Cantech" 1862 "Yamaha Marine" 1863 "Faria Instruments" ;
VAL_ 2315198976 Industry_Code 0 "Global" 1 "Highway" 2 "Agriculture" 3 "Construction" 4 "Marine Industry" 5 "Industrial" ;
VAL_ 2315198976 Network_Group 0 "None" 1 "Default" 2 "Group 1" 3 "Group 2" 4 "Group 3" 5 "Group 4" 6 "Group 5" 7 "Group 6" ;
VAL_ 2315198976 Command_Type 2 "Follow Up" 10 "AP Command" 23 "Timer" 31 "Siren" 36 "AIS vessel selected" 255 "Alarm" ;
VAL_ 2315198976 Event 2 "Follow/Non Follow" 6 "Standby" 9 "Heading mode" 10 "Nav mode" 12 "No Drift mode" 13 "Non Follow Up mode" 14 "Follow Up mode" 15 "Wind mode" 17 "Tack" 18 "Square (Turn)" 19 "C-Turn" 20 "U-Turn" 21 "Spiral (Turn)" 22 "Zig Zag (Turn)" 23 "Lazy-S (Turn)" 24 "Depth (Turn)" 26 "Change course" 61 "Timer sync" 107 "MOB Activated" 108 "MOB Deactivated" 112 "Ping port end" 113 "Ping starboard end" ;
VAL_ 2315198976 Manufacturer_Code 69 "ARKS Enterprises" 78 "FW Murphy/Enovation Controls" 80 "Twin Disc" 85 "Kohler Power Systems" 88 "Hemisphere GPS" 135 "Airmar" 137 "Maretron" 140 "Lowrance" 144 "Mercury Marine" 147 "Nautibus Electronic" 148 "Blue Water Data" 154 "Westerbeke" 157 "ISSPRO" 161 "Offshore Systems (UK)" 163 "Evinrude/BRP" 165 "CPAC Systems" 168 "Xantrex Technology" 169 "Marlin Technologies" 172 "Yanmar Marine" 174 "Volvo Penta" 176 "Carling Technologies Inc. (Moritz Aerospace)" 185 "Beede Instruments" 192 "Floscan Instrument" 193 "Nobeltec" 198 "Mystic Valley Communications" 199 "Actia" 201 "Disenos Y Technologia" 211 "Digital Switching Systems" 215 "Xintex/Atena" 224 "EMMI NETWORK" 228 "ZF" 229 "Garmin" 233 "Yacht Monitoring Solutions" 235 "Sailormade Marine Telemetry/Tetra Technology" 243 "Eride" 257 "Honda Motor" 272 "Groco" 273 "Actisense" 274 "Amphenol LTW Technology" 275 "Navico" 283 "Hamilton Jet" 285 "Sea Recovery" 286 "Coelmo SRL Italy" 295 "BEP Marine" 304 "Empir Bus" 305 "NovAtel" 306 "Sleipner Motor" 307 "MBW Technologies" 315 "ICOM" 328 "Qwerty" 329 "Dief" 341 "Boening Automationstechnologie" 345 "Korean Maritime University" 351 "Thrane and Thrane" 355 "Mastervolt" 356 "Fischer Panda Generators" 358 "Victron Energy" 370 "Rolls Royce Marine" 373 "Electronic Design" 374 "Northern Lights" 378 "Glendinning" 381 "B & G" 384 "Rose Point Navigation Systems" 385 "Johnson Outdoors Marine Electronics Inc Geonav" 394 "Capi 2" 396 "Beyond Measure" 400 "Livorsi Marine" 404 "ComNav" 409 "Chetco" 419 "Fusion Electronics" 421 "Standard Horizon" 422 "True Heading" 426 "Egersund Marine Electronics" 427 "em-trak Marine Electronics" 431 "Tohatsu Co, JP" 437 "Digital Yacht" 438 "Comar Systems Limited" 440 "Cummins" 443 "VDO (aka Continental-Corporation)" 451 "Parker Hannifin aka Village Marine Tech" 459 "Alltek Marine Electronics" 460 "SAN GIORGIO S.E.I.N" 466 "Veethree Electronics & Marine" 470 "SI-TEX Marine Electronics" 471 "Sea Cross Marine" 475 "GME aka Standard Communications" 476 "Humminbird Marine Electronics" 478 "Ocean Sat" 481 "Chetco Digital Instruments" 493 "Watcheye" 499 "Lcj Capteurs" 502 "Attwood Marine" 503 "Naviop S.R.L." 504 "Vesper Marine" 510 "Marinesoft" 513 "Simarine" 517 "NoLand Engineering" 518 "Transas USA" 529 "National Instruments Korea" 530 "National Marine Electronics Association" 532 "Onwa Marine" 540 "Webasto" 571 "Marinecraft (South Korea)" 573 "McMurdo Group aka Orolia" 578 "Advansea" 579 "KVH" 580 "San Jose Technology" 583 "Yacht Control" 586 "Suzuki Motor" 591 "US Coast Guard" 595 "Ship Module aka Customware" 600 "Aquatic AV" 605 "Aventics" 606 "Intellian" 612 "SamwonIT" 614 "Arlt Tecnologies" 637 "Bavaria Yachts" 641 "Diverse Yacht Services" 644 "Wema U.S.A dba KUS" 658 "Shenzhen Jiuzhou Himunication" 688 "Rockford" 699 "Harman International" 704 "JL Audio" 708 "Lars Thrane" 715 "Autonnic" 717 "Yacht Devices" 734 "REAP Systems" 735 "AEM Performance Electronics" 739 "LxNav" 741 "Littelfuse, Inc (formerly Carling Technologies)" 743 "DaeMyung" 744 "Woosung" 748 "ISOTTA IFRA srl" 773 "Clarion US" 776 "HMI Systems" 777 "Ocean Signal" 778 "Seakeeper" 781 "Poly Planar" 785 "Fischer Panda DE" 795 "Broyda Industries" 796 "Canadian Automotive" 797 "Tides Marine" 798 "Lumishore" 799 "Still Water Designs and Audio" 802 "BJ Technologies (Beneteau)" 803 "Gill Sensors" 811 "Blue Water Desalination" 815 "FLIR" 824 "Undheim Systems" 826 "Lewmar" 838 "TeamSurv" 844 "Fell Marine" 847 "Oceanvolt" 862 "Prospec" 868 "Data Panel" 890 "L3 Technologies" 894 "Rhodan Marine Systems" 896 "Nexfour Solutions" 905 "ASA Electronics" 909 "Marines Co (South Korea)" 911 "Nautic-on" 917 "Sentinel" 929 "JL Marine Systems" 930 "Ecotronix" 944 "Zontisa Marine" 951 "EXOR International" 962 "Timbolier Industries" 963 "TJC Micro" 968 "Cox Powertrain" 969 "Blue Seas" 981 "Kobelt Manufacturing" 992 "Blue Ocean IOT" 997 "Xenta Systems" 999 "Signal K" 1004 "Ultraflex" 1008 "Lintest SmartBoat" 1011 "Soundmax" 1020 "Team Italia Marine (Onyx Marine Automation s.r.l)" 1021 "Entratech" 1022 "ITC" 1029 "The Marine Guardian" 1047 "Sonic" 1051 "ProNav" 1053 "Vetus Maxwell INC." 1056 "Lithium Pros" 1059 "Boatrax" 1062 "Marol Co ltd" 1065 "CALYPSO Instruments" 1066 "Spot Zero Water" 1069 "Lithionics Battery" 1070 "Quick-teck Electronics" 1075 "Uniden America" 1083 "Nauticoncept" 1084 "Shadow-Caster LED lighting" 1085 "Wet Sounds" 1088 "E-T-A Circuit Breakers" 1092 "Scheiber" 1100 "Smart Yachts International Limited" 1109 "Dockmate" 1114 "Bobs Machine" 1118 "L3Harris ASV" 1119 "Balmar" 1120 "Elettromedia" 1127 "Electromaax" 1140 "Across Oceans Systems" 1145 "Kiwi Yachting" 1150 "BSB Artificial Intelligence" 1151 "Orca Technologies" 1154 "TBS Electronics" 1158 "Technoton Electroics" 1160 "MG Energy Systems" 1169 "Sea Machine Robotics" 1171 "Vista Manufacturing" 1183 "Zipwake" 1186 "Sailmon" 1192 "Airmoniq Pro Kft" 1194 "Sierra Marine" 1200 "Xinuo Information Technology (Xiamen)" 1218 "Septentrio" 1233 "NKE Marine Electronics" 1238 "SuperTrack Aps" 1239 "Honda Electronics" 1245 "Raritan Engineering" 1249 "Integrated Power Solutions AG" 1260 "Interactive Technologies" 1283 "LTG-Tech" 1299 "Energy Solutions (UK)" 1300 "WATT Fuel Cell" 1302 "Pro Mainer" 1305 "Dragonfly Energy" 1306 "Koden Electronics" 1311 "Humphree" 1316 "Hinkley Yachts" 1317 "Global Marine Management GmbH (GMM)" 1320 "Triskel Marine" 1330 "Warwick Control Technologies" 1331 "Dolphin Charger" 1337 "Barnacle Systems" 1348 "Radian IoT" 1353 "Ocean LED Marine" 1359 "BluNav" 1361 "OVA (Nantong Saiyang Electronics Co., Ltd)" 1368 "RAD Propulsion" 1369 "Electric Yacht" 1372 "Elco Motor Yachts" 1384 "Tecnoseal Foundry S.r.l" 1385 "Pro Charging Systems" 1389 "EVEX" 1398 "Gobius Sensor Technology" 1403 "Arco Marine" 1408 "Lenco Marine" 1413 "Naocontrol" 1417 "Revatek" 1438 "Aeolionics" 1439 "PredictWind" 1440 "Egis Mobile Electric" 1445 "Starboard Yacht Group" 1446 "Roswell Marine" 1451 "ePropulsion (Guangdong ePropulsion Technology Ltd.)" 1452 "Micro-Air" 1453 "Vital Battery" 1458 "Ride Controller" 1460 "Tocaro Blue" 1461 "Vanquish Yachts" 1471 "FT Technologies" 1478 "Alps Alpine" 1481 "E-Force Marine" 1482 "CMC Marine" 1483 "Nanjing Sandemarine Information Technology" 1850 "Teleflex Marine (SeaStar Solutions)" 1851 "Raymarine" 1852 "Navionics" 1853 "Japan Radio" 1854 "Northstar Technologies" 1855 "Furuno" 1856 "Trimble" 1857 "Simrad" 1858 "Litton" 1859 "Kvasar" 1860 "MMP" 1861 "Vector Cantech" 1862 "Yamaha Marine" 1863 "Faria Instruments" ;
VAL_ 2315198976 Industry_Code 0 "Global" 1 "Highway" 2 "Agriculture" 3 "Construction" 4 "Marine Industry" 5 "Industrial" ;
VAL_ 2315198976 Network_Group 0 "None" 1 "Default" 2 "Group 1" 3 "Group 2" 4 "Group 3" 5 "Group 4" 6 "Group 5" 7 "Group 6" ;
VAL_ 2315198976 Command_Type 2 "Follow Up" 10 "AP Command" 23 "Timer" 31 "Siren" 36 "AIS vessel selected" 255 "Alarm" ;
VAL_ 2315198976 Event 2 "Follow/Non Follow" 6 "Standby" 9 "Heading mode" 10 "Nav mode" 12 "No Drift mode" 13 "Non Follow Up mode" 14 "Follow Up mode" 15 "Wind mode" 17 "Tack" 18 "Square (Turn)" 19 "C-Turn" 20 "U-Turn" 21 "Spiral (Turn)" 22 "Zig Zag (Turn)" 23 "Lazy-S (Turn)" 24 "Depth (Turn)" 26 "Change course" 61 "Timer sync" 107 "MOB Activated" 108 "MOB Deactivated" 112 "Ping port end" 113 "Ping starboard end" ;
VAL_ 2315198976 Direction 2 "Port" 3 "Starboard" 4 "Left rudder (port)" 5 "Right rudder (starboard)" ;
VAL_ 2315198976 Manufacturer_Code 69 "ARKS Enterprises" 78 "FW Murphy/Enovation Controls" 80 "Twin Disc" 85 "Kohler Power Systems" 88 "Hemisphere GPS" 135 "Airmar" 137 "Maretron" 140 "Lowrance" 144 "Mercury Marine" 147 "Nautibus Electronic" 148 "Blue Water Data" 154 "Westerbeke" 157 "ISSPRO" 161 "Offshore Systems (UK)" 163 "Evinrude/BRP" 165 "CPAC Systems" 168 "Xantrex Technology" 169 "Marlin Technologies" 172 "Yanmar Marine" 174 "Volvo Penta" 176 "Carling Technologies Inc. (Moritz Aerospace)" 185 "Beede Instruments" 192 "Floscan Instrument" 193 "Nobeltec" 198 "Mystic Valley Communications" 199 "Actia" 201 "Disenos Y Technologia" 211 "Digital Switching Systems" 215 "Xintex/Atena" 224 "EMMI NETWORK" 228 "ZF" 229 "Garmin" 233 "Yacht Monitoring Solutions" 235 "Sailormade Marine Telemetry/Tetra Technology" 243 "Eride" 257 "Honda Motor" 272 "Groco" 273 "Actisense" 274 "Amphenol LTW Technology" 275 "Navico" 283 "Hamilton Jet" 285 "Sea Recovery" 286 "Coelmo SRL Italy" 295 "BEP Marine" 304 "Empir Bus" 305 "NovAtel" 306 "Sleipner Motor" 307 "MBW Technologies" 315 "ICOM" 328 "Qwerty" 329 "Dief" 341 "Boening Automationstechnologie" 345 "Korean Maritime University" 351 "Thrane and Thrane" 355 "Mastervolt" 356 "Fischer Panda Generators" 358 "Victron Energy" 370 "Rolls Royce Marine" 373 "Electronic Design" 374 "Northern Lights" 378 "Glendinning" 381 "B & G" 384 "Rose Point Navigation Systems" 385 "Johnson Outdoors Marine Electronics Inc Geonav" 394 "Capi 2" 396 "Beyond Measure" 400 "Livorsi Marine" 404 "ComNav" 409 "Chetco" 419 "Fusion Electronics" 421 "Standard Horizon" 422 "True Heading" 426 "Egersund Marine Electronics" 427 "em-trak Marine Electronics" 431 "Tohatsu Co, JP" 437 "Digital Yacht" 438 "Comar Systems Limited" 440 "Cummins" 443 "VDO (aka Continental-Corporation)" 451 "Parker Hannifin aka Village Marine Tech" 459 "Alltek Marine Electronics" 460 "SAN GIORGIO S.E.I.N" 466 "Veethree Electronics & Marine" 470 "SI-TEX Marine Electronics" 471 "Sea Cross Marine" 475 "GME aka Standard Communications" 476 "Humminbird Marine Electronics" 478 "Ocean Sat" 481 "Chetco Digital Instruments" 493 "Watcheye" 499 "Lcj Capteurs" 502 "Attwood Marine" 503 "Naviop S.R.L." 504 "Vesper Marine" 510 "Marinesoft" 513 "Simarine" 517 "NoLand Engineering" 518 "Transas USA" 529 "National Instruments Korea" 530 "National Marine Electronics Association" 532 "Onwa Marine" 540 "Webasto" 571 "Marinecraft (South Korea)" 573 "McMurdo Group aka Orolia" 578 "Advansea" 579 "KVH" 580 "San Jose Technology" 583 "Yacht Control" 586 "Suzuki Motor" 591 "US Coast Guard" 595 "Ship Module aka Customware" 600 "Aquatic AV" 605 "Aventics" 606 "Intellian" 612 "SamwonIT" 614 "Arlt Tecnologies" 637 "Bavaria Yachts" 641 "Diverse Yacht Services" 644 "Wema U.S.A dba KUS" 658 "Shenzhen Jiuzhou Himunication" 688 "Rockford" 699 "Harman International" 704 "JL Audio" 708 "Lars Thrane" 715 "Autonnic" 717 "Yacht Devices" 734 "REAP Systems" 735 "AEM Performance Electronics" 739 "LxNav" 741 "Littelfuse, Inc (formerly Carling Technologies)" 743 "DaeMyung" 744 "Woosung" 748 "ISOTTA IFRA srl" 773 "Clarion US" 776 "HMI Systems" 777 "Ocean Signal" 778 "Seakeeper" 781 "Poly Planar" 785 "Fischer Panda DE" 795 "Broyda Industries" 796 "Canadian Automotive" 797 "Tides Marine" 798 "Lumishore" 799 "Still Water Designs and Audio" 802 "BJ Technologies (Beneteau)" 803 "Gill Sensors" 811 "Blue Water Desalination" 815 "FLIR" 824 "Undheim Systems" 826 "Lewmar" 838 "TeamSurv" 844 "Fell Marine" 847 "Oceanvolt" 862 "Prospec" 868 "Data Panel" 890 "L3 Technologies" 894 "Rhodan Marine Systems" 896 "Nexfour Solutions" 905 "ASA Electronics" 909 "Marines Co (South Korea)" 911 "Nautic-on" 917 "Sentinel" 929 "JL Marine Systems" 930 "Ecotronix" 944 "Zontisa Marine" 951 "EXOR International" 962 "Timbolier Industries" 963 "TJC Micro" 968 "Cox Powertrain" 969 "Blue Seas" 981 "Kobelt Manufacturing" 992 "Blue Ocean IOT" 997 "Xenta Systems" 999 "Signal K" 1004 "Ultraflex" 1008 "Lintest SmartBoat" 1011 "Soundmax" 1020 "Team Italia Marine (Onyx Marine Automation s.r.l)" 1021 "Entratech" 1022 "ITC" 1029 "The Marine Guardian" 1047 "Sonic" 1051 "ProNav" 1053 "Vetus Maxwell INC." 1056 "Lithium Pros" 1059 "Boatrax" 1062 "Marol Co ltd" 1065 "CALYPSO Instruments" 1066 "Spot Zero Water" 1069 "Lithionics Battery" 1070 "Quick-teck Electronics" 1075 "Uniden America" 1083 "Nauticoncept" 1084 "Shadow-Caster LED lighting" 1085 "Wet Sounds" 1088 "E-T-A Circuit Breakers" 1092 "Scheiber" 1100 "Smart Yachts International Limited" 1109 "Dockmate" 1114 "Bobs Machine" 1118 "L3Harris ASV" 1119 "Balmar" 1120 "Elettromedia" 1127 "Electromaax" 1140 "Across Oceans Systems" 1145 "Kiwi Yachting" 1150 "BSB Artificial Intelligence" 1151 "Orca Technologies" 1154 "TBS Electronics" 1158 "Technoton Electroics" 1160 "MG Energy Systems" 1169 "Sea Machine Robotics" 1171 "Vista Manufacturing" 1183 "Zipwake" 1186 "Sailmon" 1192 "Airmoniq Pro Kft" 1194 "Sierra Marine" 1200 "Xinuo Information Technology (Xiamen)" 1218 "Septentrio" 1233 "NKE Marine Electronics" 1238 "SuperTrack Aps" 1239 "Honda Electronics" 1245 "Raritan Engineering" 1249 "Integrated Power Solutions AG" 1260 "Interactive Technologies" 1283 "LTG-Tech" 1299 "Energy Solutions (UK)" 1300 "WATT Fuel Cell" 1302 "Pro Mainer" 1305 "Dragonfly Energy" 1306 "Koden Electronics" 1311 "Humphree" 1316 "Hinkley Yachts" 1317 "Global Marine Management GmbH (GMM)" 1320 "Triskel Marine" 1330 "Warwick Control Technologies" 1331 "Dolphin Charger" 1337 "Barnacle Systems" 1348 "Radian IoT" 1353 "Ocean LED Marine" 1359 "BluNav" 1361 "OVA (Nantong Saiyang Electronics Co., Ltd)" 1368 "RAD Propulsion" 1369 "Electric Yacht" 1372 "Elco Motor Yachts" 1384 "Tecnoseal Foundry S.r.l" 1385 "Pro Charging Systems" 1389 "EVEX" 1398 "Gobius Sensor Technology" 1403 "Arco Marine" 1408 "Lenco Marine" 1413 "Naocontrol" 1417 "Revatek" 1438 "Aeolionics" 1439 "PredictWind" 1440 "Egis Mobile Electric" 1445 "Starboard Yacht Group" 1446 "Roswell Marine" 1451 "ePropulsion (Guangdong ePropulsion Technology Ltd.)" 1452 "Micro-Air" 1453 "Vital Battery" 1458 "Ride Controller" 1460 "Tocaro Blue" 1461 "Vanquish Yachts" 1471 "FT Technologies" 1478 "Alps Alpine" 1481 "E-Force Marine" 1482 "CMC Marine" 1483 "Nanjing Sandemarine Information Technology" 1850 "Teleflex Marine (SeaStar Solutions)" 1851 "Raymarine" 1852 "Navionics" 1853 "Japan Radio" 1854 "Northstar Technologies" 1855 "Furuno" 1856 "Trimble" 1857 "Simrad" 1858 "Litton" 1859 "Kvasar" 1860 "MMP" 1861 "Vector Cantech" 1862 "Yamaha Marine" 1863 "Faria Instruments" ;
VAL_ 2315198976 Industry_Code 0 "Global" 1 "Highway" 2 "Agriculture" 3 "Construction" 4 "Marine Industry" 5 "Industrial" ;
VAL_ 2315198976 Network_Group 0 "None" 1 "Default" 2 "Group 1" 3 "Group 2" 4 "Group 3" 5 "Group 4" 6 "Group 5" 7 "Group 6" ;
VAL_ 2315198976 Command_Type 2 "Follow Up" 10 "AP Command" 23 "Timer" 31 "Siren" 36 "AIS vessel selected" 255 "Alarm" ;
VAL_ 2315198976 Event 2 "Follow/Non Follow" 6 "Standby" 9 "Heading mode" 10 "Nav mode" 12 "No Drift mode" 13 "Non Follow Up mode" 14 "Follow Up mode" 15 "Wind mode" 17 "Tack" 18 "Square (Turn)" 19 "C-Turn" 20 "U-Turn" 21 "Spiral (Turn)" 22 "Zig Zag (Turn)" 23 "Lazy-S (Turn)" 24 "Depth (Turn)" 26 "Change course" 61 "Timer sync" 107 "MOB Activated" 108 "MOB Deactivated" 112 "Ping port end" 113 "Ping starboard end" ;
VAL_ 2315198976 Manufacturer_Code 69 "ARKS Enterprises" 78 "FW Murphy/Enovation Controls" 80 "Twin Disc" 85 "Kohler Power Systems" 88 "Hemisphere GPS" 135 "Airmar" 137 "Maretron" 140 "Lowrance" 144 "Mercury Marine" 147 "Nautibus Electronic" 148 "Blue Water Data" 154 "Westerbeke" 157 "ISSPRO" 161 "Offshore Systems (UK)" 163 "Evinrude/BRP" 165 "CPAC Systems" 168 "Xantrex Technology" 169 "Marlin Technologies" 172 "Yanmar Marine" 174 "Volvo Penta" 176 "Carling Technologies Inc. (Moritz Aerospace)" 185 "Beede Instruments" 192 "Floscan Instrument" 193 "Nobeltec" 198 "Mystic Valley Communications" 199 "Actia" 201 "Disenos Y Technologia" 211 "Digital Switching Systems" 215 "Xintex/Atena" 224 "EMMI NETWORK" 228 "ZF" 229 "Garmin" 233 "Yacht Monitoring Solutions" 235 "Sailormade Marine Telemetry/Tetra Technology" 243 "Eride" 257 "Honda Motor" 272 "Groco" 273 "Actisense" 274 "Amphenol LTW Technology" 275 "Navico" 283 "Hamilton Jet" 285 "Sea Recovery" 286 "Coelmo SRL Italy" 295 "BEP Marine" 304 "Empir Bus" 305 "NovAtel" 306 "Sleipner Motor" 307 "MBW Technologies" 315 "ICOM" 328 "Qwerty" 329 "Dief" 341 "Boening Automationstechnologie" 345 "Korean Maritime University" 351 "Thrane and Thrane" 355 "Mastervolt" 356 "Fischer Panda Generators" 358 "Victron Energy" 370 "Rolls Royce Marine" 373 "Electronic Design" 374 "Northern Lights" 378 "Glendinning" 381 "B & G" 384 "Rose Point Navigation Systems" 385 "Johnson Outdoors Marine Electronics Inc Geonav" 394 "Capi 2" 396 "Beyond Measure" 400 "Livorsi Marine" 404 "ComNav" 409 "Chetco" 419 "Fusion Electronics" 421 "Standard Horizon" 422 "True Heading" 426 "Egersund Marine Electronics" 427 "em-trak Marine Electronics" 431 "Tohatsu Co, JP" 437 "Digital Yacht" 438 "Comar Systems Limited" 440 "Cummins" 443 "VDO (aka Continental-Corporation)" 451 "Parker Hannifin aka Village Marine Tech" 459 "Alltek Marine Electronics" 460 "SAN GIORGIO S.E.I.N" 466 "Veethree Electronics & Marine" 470 "SI-TEX Marine Electronics" 471 "Sea Cross Marine" 475 "GME aka Standard Communications" 476 "Humminbird Marine Electronics" 478 "Ocean Sat" 481 "Chetco Digital Instruments" 493 "Watcheye" 499 "Lcj Capteurs" 502 "Attwood Marine" 503 "Naviop S.R.L." 504 "Vesper Marine" 510 "Marinesoft" 513 "Simarine" 517 "NoLand Engineering" 518 "Transas USA" 529 "National Instruments Korea" 530 "National Marine Electronics Association" 532 "Onwa Marine" 540 "Webasto" 571 "Marinecraft (South Korea)" 573 "McMurdo Group aka Orolia" 578 "Advansea" 579 "KVH" 580 "San Jose Technology" 583 "Yacht Control" 586 "Suzuki Motor" 591 "US Coast Guard" 595 "Ship Module aka Customware" 600 "Aquatic AV" 605 "Aventics" 606 "Intellian" 612 "SamwonIT" 614 "Arlt Tecnologies" 637 "Bavaria Yachts" 641 "Diverse Yacht Services" 644 "Wema U.S.A dba KUS" 658 "Shenzhen Jiuzhou Himunication" 688 "Rockford" 699 "Harman International" 704 "JL Audio" 708 "Lars Thrane" 715 "Autonnic" 717 "Yacht Devices" 734 "REAP Systems" 735 "AEM Performance Electronics" 739 "LxNav" 741 "Littelfuse, Inc (formerly Carling Technologies)" 743 "DaeMyung" 744 "Woosung" 748 "ISOTTA IFRA srl" 773 "Clarion US" 776 "HMI Systems" 777 "Ocean Signal" 778 "Seakeeper" 781 "Poly Planar" 785 "Fischer Panda DE" 795 "Broyda Industries" 796 "Canadian Automotive" 797 "Tides Marine" 798 "Lumishore" 799 "Still Water Designs and Audio" 802 "BJ Technologies (Beneteau)" 803 "Gill Sensors" 811 "Blue Water Desalination" 815 "FLIR" 824 "Undheim Systems" 826 "Lewmar" 838 "TeamSurv" 844 "Fell Marine" 847 "Oceanvolt" 862 "Prospec" 868 "Data Panel" 890 "L3 Technologies" 894 "Rhodan Marine Systems" 896 "Nexfour Solutions" 905 "ASA Electronics" 909 "Marines Co (South Korea)" 911 "Nautic-on" 917 "Sentinel" 929 "JL Marine Systems" 930 "Ecotronix" 944 "Zontisa Marine" 951 "EXOR International" 962 "Timbolier Industries" 963 "TJC Micro" 968 "Cox Powertrain" 969 "Blue Seas" 981 "Kobelt Manufacturing" 992 "Blue Ocean IOT" 997 "Xenta Systems" 999 "Signal K" 1004 "Ultraflex" 1008 "Lintest SmartBoat" 1011 "Soundmax" 1020 "Team Italia Marine (Onyx Marine Automation s.r.l)" 1021 "Entratech" 1022 "ITC" 1029 "The Marine Guardian" 1047 "Sonic" 1051 "ProNav" 1053 "Vetus Maxwell INC." 1056 "Lithium Pros" 1059 "Boatrax" 1062 "Marol Co ltd" 1065 "CALYPSO Instruments" 1066 "Spot Zero Water" 1069 "Lithionics Battery" 1070 "Quick-teck Electronics" 1075 "Uniden America" 1083 "Nauticoncept" 1084 "Shadow-Caster LED lighting" 1085 "Wet Sounds" 1088 "E-T-A Circuit Breakers" 1092 "Scheiber" 1100 "Smart Yachts International Limited" 1109 "Dockmate" 1114 "Bobs Machine" 1118 "L3Harris ASV" 1119 "Balmar" 1120 "Elettromedia" 1127 "Electromaax" 1140 "Across Oceans Systems" 1145 "Kiwi Yachting" 1150 "BSB Artificial Intelligence" 1151 "Orca Technologies" 1154 "TBS Electronics" 1158 "Technoton Electroics" 1160 "MG Energy Systems" 1169 "Sea Machine Robotics" 1171 "Vista Manufacturing" 1183 "Zipwake" 1186 "Sailmon" 1192 "Airmoniq Pro Kft" 1194 "Sierra Marine" 1200 "Xinuo Information Technology (Xiamen)" 1218 "Septentrio" 1233 "NKE Marine Electronics" 1238 "SuperTrack Aps" 1239 "Honda Electronics" 1245 "Raritan Engineering" 1249 "Integrated Power Solutions AG" 1260 "Interactive Technologies" 1283 "LTG-Tech" 1299 "Energy Solutions (UK)" 1300 "WATT Fuel Cell" 1302 "Pro Mainer" 1305 "Dragonfly Energy" 1306 "Koden Electronics" 1311 "Humphree" 1316 "Hinkley Yachts" 1317 "Global Marine Management GmbH (GMM)" 1320 "Triskel Marine" 1330 "Warwick Control Technologies" 1331 "Dolphin Charger" 1337 "Barnacle Systems" 1348 "Radian IoT" 1353 "Ocean LED Marine" 1359 "BluNav" 1361 "OVA (Nantong Saiyang Electronics Co., Ltd)" 1368 "RAD Propulsion" 1369 "Electric Yacht" 1372 "Elco Motor Yachts" 1384 "Tecnoseal Foundry S.r.l" 1385 "Pro Charging Systems" 1389 "EVEX" 1398 "Gobius Sensor Technology" 1403 "Arco Marine" 1408 "Lenco Marine" 1413 "Naocontrol" 1417 "Revatek" 1438 "Aeolionics" 1439 "PredictWind" 1440 "Egis Mobile Electric" 1445 "Starboard Yacht Group" 1446 "Roswell Marine" 1451 "ePropulsion (Guangdong ePropulsion Technology Ltd.)" 1452 "Micro-Air" 1453 "Vital Battery" 1458 "Ride Controller" 1460 "Tocaro Blue" 1461 "Vanquish Yachts" 1471 "FT Technologies" 1478 "Alps Alpine" 1481 "E-Force Marine" 1482 "CMC Marine" 1483 "Nanjing Sandemarine Information Technology" 1850 "Teleflex Marine (SeaStar Solutions)" 1851 "Raymarine" 1852 "Navionics" 1853 "Japan Radio" 1854 "Northstar Technologies" 1855 "Furuno" 1856 "Trimble" 1857 "Simrad" 1858 "Litton" 1859 "Kvasar" 1860 "MMP" 1861 "Vector Cantech" 1862 "Yamaha Marine" 1863 "Faria Instruments" ;
VAL_ 2315198976 Industry_Code 0 "Global" 1 "Highway" 2 "Agriculture" 3 "Construction" 4 "Marine Industry" 5 "Industrial" ;
VAL_ 2315198976 Network_Group 0 "None" 1 "Default" 2 "Group 1" 3 "Group 2" 4 "Group 3" 5 "Group 4" 6 "Group 5" 7 "Group 6" ;
VAL_ 2315198976 Command_Type 2 "Follow Up" 10 "AP Command" 23 "Timer" 31 "Siren" 36 "AIS vessel selected" 255 "Alarm" ;
VAL_ 2315198976 Event 2 "Follow/Non Follow" 6 "Standby" 9 "Heading mode" 10 "Nav mode" 12 "No Drift mode" 13 "Non Follow Up mode" 14 "Follow Up mode" 15 "Wind mode" 17 "Tack" 18 "Square (Turn)" 19 "C-Turn" 20 "U-Turn" 21 "Spiral (Turn)" 22 "Zig Zag (Turn)" 23 "Lazy-S (Turn)" 24 "Depth (Turn)" 26 "Change course" 61 "Timer sync" 107 "MOB Activated" 108 "MOB Deactivated" 112 "Ping port end" 113 "Ping starboard end" ;
VAL_ 2315198976 Manufacturer_Code 69 "ARKS Enterprises" 78 "FW Murphy/Enovation Controls" 80 "Twin Disc" 85 "Kohler Power Systems" 88 "Hemisphere GPS" 135 "Airmar" 137 "Maretron" 140 "Lowrance" 144 "Mercury Marine" 147 "Nautibus Electronic" 148 "Blue Water Data" 154 "Westerbeke" 157 "ISSPRO" 161 "Offshore Systems (UK)" 163 "Evinrude/BRP" 165 "CPAC Systems" 168 "Xantrex Technology" 169 "Marlin Technologies" 172 "Yanmar Marine" 174 "Volvo Penta" 176 "Carling Technologies Inc. (Moritz Aerospace)" 185 "Beede Instruments" 192 "Floscan Instrument" 193 "Nobeltec" 198 "Mystic Valley Communications" 199 "Actia" 201 "Disenos Y Technologia" 211 "Digital Switching Systems" 215 "Xintex/Atena" 224 "EMMI NETWORK" 228 "ZF" 229 "Garmin" 233 "Yacht Monitoring Solutions" 235 "Sailormade Marine Telemetry/Tetra Technology" 243 "Eride" 257 "Honda Motor" 272 "Groco" 273 "Actisense" 274 "Amphenol LTW Technology" 275 "Navico" 283 "Hamilton Jet" 285 "Sea Recovery" 286 "Coelmo SRL Italy" 295 "BEP Marine" 304 "Empir Bus" 305 "NovAtel" 306 "Sleipner Motor" 307 "MBW Technologies" 315 "ICOM" 328 "Qwerty" 329 "Dief" 341 "Boening Automationstechnologie" 345 "Korean Maritime University" 351 "Thrane and Thrane" 355 "Mastervolt" 356 "Fischer Panda Generators" 358 "Victron Energy" 370 "Rolls Royce Marine" 373 "Electronic Design" 374 "Northern Lights" 378 "Glendinning" 381 "B & G" 384 "Rose Point Navigation Systems" 385 "Johnson Outdoors Marine Electronics Inc Geonav" 394 "Capi 2" 396 "Beyond Measure" 400 "Livorsi Marine" 404 "ComNav" 409 "Chetco" 419 "Fusion Electronics" 421 "Standard Horizon" 422 "True Heading" 426 "Egersund Marine Electronics" 427 "em-trak Marine Electronics" 431 "Tohatsu Co, JP" 437 "Digital Yacht" 438 "Comar Systems Limited" 440 "Cummins" 443 "VDO (aka Continental-Corporation)" 451 "Parker Hannifin aka Village Marine Tech" 459 "Alltek Marine Electronics" 460 "SAN GIORGIO S.E.I.N" 466 "Veethree Electronics & Marine" 470 "SI-TEX Marine Electronics" 471 "Sea Cross Marine" 475 "GME aka Standard Communications" 476 "Humminbird Marine Electronics" 478 "Ocean Sat" 481 "Chetco Digital Instruments" 493 "Watcheye" 499 "Lcj Capteurs" 502 "Attwood Marine" 503 "Naviop S.R.L." 504 "Vesper Marine" 510 "Marinesoft" 513 "Simarine" 517 "NoLand Engineering" 518 "Transas USA" 529 "National Instruments Korea" 530 "National Marine Electronics Association" 532 "Onwa Marine" 540 "Webasto" 571 "Marinecraft (South Korea)" 573 "McMurdo Group aka Orolia" 578 "Advansea" 579 "KVH" 580 "San Jose Technology" 583 "Yacht Control" 586 "Suzuki Motor" 591 "US Coast Guard" 595 "Ship Module aka Customware" 600 "Aquatic AV" 605 "Aventics" 606 "Intellian" 612 "SamwonIT" 614 "Arlt Tecnologies" 637 "Bavaria Yachts" 641 "Diverse Yacht Services" 644 "Wema U.S.A dba KUS" 658 "Shenzhen Jiuzhou Himunication" 688 "Rockford" 699 "Harman International" 704 "JL Audio" 708 "Lars Thrane" 715 "Autonnic" 717 "Yacht Devices" 734 "REAP Systems" 735 "AEM Performance Electronics" 739 "LxNav" 741 "Littelfuse, Inc (formerly Carling Technologies)" 743 "DaeMyung" 744 "Woosung" 748 "ISOTTA IFRA srl" 773 "Clarion US" 776 "HMI Systems" 777 "Ocean Signal" 778 "Seakeeper" 781 "Poly Planar" 785 "Fischer Panda DE" 795 "Broyda Industries" 796 "Canadian Automotive" 797 "Tides Marine" 798 "Lumishore" 799 "Still Water Designs and Audio" 802 "BJ Technologies (Beneteau)" 803 "Gill Sensors" 811 "Blue Water Desalination" 815 "FLIR" 824 "Undheim Systems" 826 "Lewmar" 838 "TeamSurv" 844 "Fell Marine" 847 "Oceanvolt" 862 "Prospec" 868 "Data Panel" 890 "L3 Technologies" 894 "Rhodan Marine Systems" 896 "Nexfour Solutions" 905 "ASA Electronics" 909 "Marines Co (South Korea)" 911 "Nautic-on" 917 "Sentinel" 929 "JL Marine Systems" 930 "Ecotronix" 944 "Zontisa Marine" 951 "EXOR International" 962 "Timbolier Industries" 963 "TJC Micro" 968 "Cox Powertrain" 969 "Blue Seas" 981 "Kobelt Manufacturing" 992 "Blue Ocean IOT" 997 "Xenta Systems" 999 "Signal K" 1004 "Ultraflex" 1008 "Lintest SmartBoat" 1011 "Soundmax" 1020 "Team Italia Marine (Onyx Marine Automation s.r.l)" 1021 "Entratech" 1022 "ITC" 1029 "The Marine Guardian" 1047 "Sonic" 1051 "ProNav" 1053 "Vetus Maxwell INC." 1056 "Lithium Pros" 1059 "Boatrax" 1062 "Marol Co ltd" 1065 "CALYPSO Instruments" 1066 "Spot Zero Water" 1069 "Lithionics Battery" 1070 "Quick-teck Electronics" 1075 "Uniden America" 1083 "Nauticoncept" 1084 "Shadow-Caster LED lighting" 1085 "Wet Sounds" 1088 "E-T-A Circuit Breakers" 1092 "Scheiber" 1100 "Smart Yachts International Limited" 1109 "Dockmate" 1114 "Bobs Machine" 1118 "L3Harris ASV" 1119 "Balmar" 1120 "Elettromedia" 1127 "Electromaax" 1140 "Across Oceans Systems" 1145 "Kiwi Yachting" 1150 "BSB Artificial Intelligence" 1151 "Orca Technologies" 1154 "TBS Electronics" 1158 "Technoton Electroics" 1160 "MG Energy Systems" 1169 "Sea Machine Robotics" 1171 "Vista Manufacturing" 1183 "Zipwake" 1186 "Sailmon" 1192 "Airmoniq Pro Kft" 1194 "Sierra Marine" 1200 "Xinuo Information Technology (Xiamen)" 1218 "Septentrio" 1233 "NKE Marine Electronics" 1238 "SuperTrack Aps" 1239 "Honda Electronics" 1245 "Raritan Engineering" 1249 "Integrated Power Solutions AG" 1260 "Interactive Technologies" 1283 "LTG-Tech" 1299 "Energy Solutions (UK)" 1300 "WATT Fuel Cell" 1302 "Pro Mainer" 1305 "Dragonfly Energy" 1306 "Koden Electronics" 1311 "Humphree" 1316 "Hinkley Yachts" 1317 "Global Marine Management GmbH (GMM)" 1320 "Triskel Marine" 1330 "Warwick Control Technologies" 1331 "Dolphin Charger" 1337 "Barnacle Systems" 1348 "Radian IoT" 1353 "Ocean LED Marine" 1359 "BluNav" 1361 "OVA (Nantong Saiyang Electronics Co., Ltd)" 1368 "RAD Propulsion" 1369 "Electric Yacht" 1372 "Elco Motor Yachts" 1384 "Tecnoseal Foundry S.r.l" 1385 "Pro Charging Systems" 1389 "EVEX" 1398 "Gobius Sensor Technology" 1403 "Arco Marine" 1408 "Lenco Marine" 1413 "Naocontrol" 1417 "Revatek" 1438 "Aeolionics" 1439 "PredictWind" 1440 "Egis Mobile Electric" 1445 "Starboard Yacht Group" 1446 "Roswell Marine" 1451 "ePropulsion (Guangdong ePropulsion Technology Ltd.)" 1452 "Micro-Air" 1453 "Vital Battery" 1458 "Ride Controller" 1460 "Tocaro Blue" 1461 "Vanquish Yachts" 1471 "FT Technologies" 1478 "Alps Alpine" 1481 "E-Force Marine" 1482 "CMC Marine" 1483 "Nanjing Sandemarine Information Technology" 1850 "Teleflex Marine (SeaStar Solutions)" 1851 "Raymarine" 1852 "Navionics" 1853 "Japan Radio" 1854 "Northstar Technologies" 1855 "Furuno" 1856 "Trimble" 1857 "Simrad" 1858 "Litton" 1859 "Kvasar" 1860 "MMP" 1861 "Vector Cantech" 1862 "Yamaha Marine" 1863 "Faria Instruments" ;
VAL_ 2315198976 Industry_Code 0 "Global" 1 "Highway" 2 "Agriculture" 3 "Construction" 4 "Marine Industry" 5 "Industrial" ;
VAL_ 2315198976 Network_Group 0 "None" 1 "Default" 2 "Group 1" 3 "Group 2" 4 "Group 3" 5 "Group 4" 6 "Group 5" 7 "Group 6" ;
VAL_ 2315198976 Command_Type 2 "Follow Up" 10 "AP Command" 23 "Timer" 31 "Siren" 36 "AIS vessel selected" 255 "Alarm" ;
VAL_ 2315198976 Event 2 "Follow/Non Follow" 6 "Standby" 9 "Heading mode" 10 "Nav mode" 12 "No Drift mode" 13 "Non Follow Up mode" 14 "Follow Up mode" 15 "Wind mode" 17 "Tack" 18 "Square (Turn)" 19 "C-Turn" 20 "U-Turn" 21 "Spiral (Turn)" 22 "Zig Zag (Turn)" 23 "Lazy-S (Turn)" 24 "Depth (Turn)" 26 "Change course" 61 "Timer sync" 107 "MOB Activated" 108 "MOB Deactivated" 112 "Ping port end" 113 "Ping starboard end" ;
VAL_ 2315198976 Manufacturer_Code 69 "ARKS Enterprises" 78 "FW Murphy/Enovation Controls" 80 "Twin Disc" 85 "Kohler Power Systems" 88 "Hemisphere GPS" 135 "Airmar" 137 "Maretron" 140 "Lowrance" 144 "Mercury Marine" 147 "Nautibus Electronic" 148 "Blue Water Data" 154 "Westerbeke" 157 "ISSPRO" 161 "Offshore Systems (UK)" 163 "Evinrude/BRP" 165 "CPAC Systems" 168 "Xantrex Technology" 169 "Marlin Technologies" 172 "Yanmar Marine" 174 "Volvo Penta" 176 "Carling Technologies Inc. (Moritz Aerospace)" 185 "Beede Instruments" 192 "Floscan Instrument" 193 "Nobeltec" 198 "Mystic Valley Communications" 199 "Actia" 201 "Disenos Y Technologia" 211 "Digital Switching Systems" 215 "Xintex/Atena" 224 "EMMI NETWORK" 228 "ZF" 229 "Garmin" 233 "Yacht Monitoring Solutions" 235 "Sailormade Marine Telemetry/Tetra Technology" 243 "Eride" 257 "Honda Motor" 272 "Groco" 273 "Actisense" 274 "Amphenol LTW Technology" 275 "Navico" 283 "Hamilton Jet" 285 "Sea Recovery" 286 "Coelmo SRL Italy" 295 "BEP Marine" 304 "Empir Bus" 305 "NovAtel" 306 "Sleipner Motor" 307 "MBW Technologies" 315 "ICOM" 328 "Qwerty" 329 "Dief" 341 "Boening Automationstechnologie" 345 "Korean Maritime University" 351 "Thrane and Thrane" 355 "Mastervolt" 356 "Fischer Panda Generators" 358 "Victron Energy" 370 "Rolls Royce Marine" 373 "Electronic Design" 374 "Northern Lights" 378 "Glendinning" 381 "B & G" 384 "Rose Point Navigation Systems" 385 "Johnson Outdoors Marine Electronics Inc Geonav" 394 "Capi 2" 396 "Beyond Measure" 400 "Livorsi Marine" 404 "ComNav" 409 "Chetco" 419 "Fusion Electronics" 421 "Standard Horizon" 422 "True Heading" 426 "Egersund Marine Electronics" 427 "em-trak Marine Electronics" 431 "Tohatsu Co, JP" 437 "Digital Yacht" 438 "Comar Systems Limited" 440 "Cummins" 443 "VDO (aka Continental-Corporation)" 451 "Parker Hannifin aka Village Marine Tech" 459 "Alltek Marine Electronics" 460 "SAN GIORGIO S.E.I.N" 466 "Veethree Electronics & Marine" 470 "SI-TEX Marine Electronics" 471 "Sea Cross Marine" 475 "GME aka Standard Communications" 476 "Humminbird Marine Electronics" 478 "Ocean Sat" 481 "Chetco Digital Instruments" 493 "Watcheye" 499 "Lcj Capteurs" 502 "Attwood Marine" 503 "Naviop S.R.L." 504 "Vesper Marine" 510 "Marinesoft" 513 "Simarine" 517 "NoLand Engineering" 518 "Transas USA" 529 "National Instruments Korea" 530 "National Marine Electronics Association" 532 "Onwa Marine" 540 "Webasto" 571 "Marinecraft (South Korea)" 573 "McMurdo Group aka Orolia" 578 "Advansea" 579 "KVH" 580 "San Jose Technology" 583 "Yacht Control" 586 "Suzuki Motor" 591 "US Coast Guard" 595 "Ship Module aka Customware" 600 "Aquatic AV" 605 "Aventics" 606 "Intellian" 612 "SamwonIT" 614 "Arlt Tecnologies" 637 "Bavaria Yachts" 641 "Diverse Yacht Services" 644 "Wema U.S.A dba KUS" 658 "Shenzhen Jiuzhou Himunication" 688 "Rockford" 699 "Harman International" 704 "JL Audio" 708 "Lars Thrane" 715 "Autonnic" 717 "Yacht Devices" 734 "REAP Systems" 735 "AEM Performance Electronics" 739 "LxNav" 741 "Littelfuse, Inc (formerly Carling Technologies)" 743 "DaeMyung" 744 "Woosung" 748 "ISOTTA IFRA srl" 773 "Clarion US" 776 "HMI Systems" 777 "Ocean Signal" 778 "Seakeeper" 781 "Poly Planar" 785 "Fischer Panda DE" 795 "Broyda Industries" 796 "Canadian Automotive" 797 "Tides Marine" 798 "Lumishore" 799 "Still Water Designs and Audio" 802 "BJ Technologies (Beneteau)" 803 "Gill Sensors" 811 "Blue Water Desalination" 815 "FLIR" 824 "Undheim Systems" 826 "Lewmar" 838 "TeamSurv" 844 "Fell Marine" 847 "Oceanvolt" 862 "Prospec" 868 "Data Panel" 890 "L3 Technologies" 894 "Rhodan Marine Systems" 896 "Nexfour Solutions" 905 "ASA Electronics" 909 "Marines Co (South Korea)" 911 "Nautic-on" 917 "Sentinel" 929 "JL Marine Systems" 930 "Ecotronix" 944 "Zontisa Marine" 951 "EXOR International" 962 "Timbolier Industries" 963 "TJC Micro" 968 "Cox Powertrain" 969 "Blue Seas" 981 "Kobelt Manufacturing" 992 "Blue Ocean IOT" 997 "Xenta Systems" 999 "Signal K" 1004 "Ultraflex" 1008 "Lintest SmartBoat" 1011 "Soundmax" 1020 "Team Italia Marine (Onyx Marine Automation s.r.l)" 1021 "Entratech" 1022 "ITC" 1029 "The Marine Guardian" 1047 "Sonic" 1051 "ProNav" 1053 "Vetus Maxwell INC." 1056 "Lithium Pros" 1059 "Boatrax" 1062 "Marol Co ltd" 1065 "CALYPSO Instruments" 1066 "Spot Zero Water" 1069 "Lithionics Battery" 1070 "Quick-teck Electronics" 1075 "Uniden America" 1083 "Nauticoncept" 1084 "Shadow-Caster LED lighting" 1085 "Wet Sounds" 1088 "E-T-A Circuit Breakers" 1092 "Scheiber" 1100 "Smart Yachts International Limited" 1109 "Dockmate" 1114 "Bobs Machine" 1118 "L3Harris ASV" 1119 "Balmar" 1120 "Elettromedia" 1127 "Electromaax" 1140 "Across Oceans Systems" 1145 "Kiwi Yachting" 1150 "BSB Artificial Intelligence" 1151 "Orca Technologies" 1154 "TBS Electronics" 1158 "Technoton Electroics" 1160 "MG Energy Systems" 1169 "Sea Machine Robotics" 1171 "Vista Manufacturing" 1183 "Zipwake" 1186 "Sailmon" 1192 "Airmoniq Pro Kft" 1194 "Sierra Marine" 1200 "Xinuo Information Technology (Xiamen)" 1218 "Septentrio" 1233 "NKE Marine Electronics" 1238 "SuperTrack Aps" 1239 "Honda Electronics" 1245 "Raritan Engineering" 1249 "Integrated Power Solutions AG" 1260 "Interactive Technologies" 1283 "LTG-Tech" 1299 "Energy Solutions (UK)" 1300 "WATT Fuel Cell" 1302 "Pro Mainer" 1305 "Dragonfly Energy" 1306 "Koden Electronics" 1311 "Humphree" 1316 "Hinkley Yachts" 1317 "Global Marine Management GmbH (GMM)" 1320 "Triskel Marine" 1330 "Warwick Control Technologies" 1331 "Dolphin Charger" 1337 "Barnacle Systems" 1348 "Radian IoT" 1353 "Ocean LED Marine" 1359 "BluNav" 1361 "OVA (Nantong Saiyang Electronics Co., Ltd)" 1368 "RAD Propulsion" 1369 "Electric Yacht" 1372 "Elco Motor Yachts" 1384 "Tecnoseal Foundry S.r.l" 1385 "Pro Charging Systems" 1389 "EVEX" 1398 "Gobius Sensor Technology" 1403 "Arco Marine" 1408 "Lenco Marine" 1413 "Naocontrol" 1417 "Revatek" 1438 "Aeolionics" 1439 "PredictWind" 1440 "Egis Mobile Electric" 1445 "Starboard Yacht Group" 1446 "Roswell Marine" 1451 "ePropulsion (Guangdong ePropulsion Technology Ltd.)" 1452 "Micro-Air" 1453 "Vital Battery" 1458 "Ride Controller" 1460 "Tocaro Blue" 1461 "Vanquish Yachts" 1471 "FT Technologies" 1478 "Alps Alpine" 1481 "E-Force Marine" 1482 "CMC Marine" 1483 "Nanjing Sandemarine Information Technology" 1850 "Teleflex Marine (SeaStar Solutions)" 1851 "Raymarine" 1852 "Navionics" 1853 "Japan Radio" 1854 "Northstar Technologies" 1855 "Furuno" 1856 "Trimble" 1857 "Simrad" 1858 "Litton" 1859 "Kvasar" 1860 "MMP" 1861 "Vector Cantech" 1862 "Yamaha Marine" 1863 "Faria Instruments" ;
VAL_ 2315198976 Industry_Code 0 "Global" 1 "Highway" 2 "Agriculture" 3 "Construction" 4 "Marine Industry" 5 "Industrial" ;
VAL_ 2315198976 Network_Group 0 "None" 1 "Default" 2 "Group 1" 3 "Group 2" 4 "Group 3" 5 "Group 4" 6 "Group 5" 7 "Group 6" ;
VAL_ 2315198976 Command_Type 2 "Follow Up" 10 "AP Command" 23 "Timer" 31 "Siren" 36 "AIS vessel selected" 255 "Alarm" ;
VAL_ 2315198976 Event 2 "Follow/Non Follow" 6 "Standby" 9 "Heading mode" 10 "Nav mode" 12 "No Drift mode" 13 "Non Follow Up mode" 14 "Follow Up mode" 15 "Wind mode" 17 "Tack" 18 "Square (Turn)" 19 "C-Turn" 20 "U-Turn" 21 "Spiral (Turn)" 22 "Zig Zag (Turn)" 23 "Lazy-S (Turn)" 24 "Depth (Turn)" 26 "Change course" 61 "Timer sync" 107 "MOB Activated" 108 "MOB Deactivated" 112 "Ping port end" 113 "Ping starboard end" ;
VAL_ 2315198976 Manufacturer_Code 69 "ARKS Enterprises" 78 "FW Murphy/Enovation Controls" 80 "Twin Disc" 85 "Kohler Power Systems" 88 "Hemisphere GPS" 135 "Airmar" 137 "Maretron" 140 "Lowrance" 144 "Mercury Marine" 147 "Nautibus Electronic" 148 "Blue Water Data" 154 "Westerbeke" 157 "ISSPRO" 161 "Offshore Systems (UK)" 163 "Evinrude/BRP" 165 "CPAC Systems" 168 "Xantrex Technology" 169 "Marlin Technologies" 172 "Yanmar Marine" 174 "Volvo Penta" 176 "Carling Technologies Inc. (Moritz Aerospace)" 185 "Beede Instruments" 192 "Floscan Instrument" 193 "Nobeltec" 198 "Mystic Valley Communications" 199 "Actia" 201 "Disenos Y Technologia" 211 "Digital Switching Systems" 215 "Xintex/Atena" 224 "EMMI NETWORK" 228 "ZF" 229 "Garmin" 233 "Yacht Monitoring Solutions" 235 "Sailormade Marine Telemetry/Tetra Technology" 243 "Eride" 257 "Honda Motor" 272 "Groco" 273 "Actisense" 274 "Amphenol LTW Technology" 275 "Navico" 283 "Hamilton Jet" 285 "Sea Recovery" 286 "Coelmo SRL Italy" 295 "BEP Marine" 304 "Empir Bus" 305 "NovAtel" 306 "Sleipner Motor" 307 "MBW Technologies" 315 "ICOM" 328 "Qwerty" 329 "Dief" 341 "Boening Automationstechnologie" 345 "Korean Maritime University" 351 "Thrane and Thrane" 355 "Mastervolt" 356 "Fischer Panda Generators" 358 "Victron Energy" 370 "Rolls Royce Marine" 373 "Electronic Design" 374 "Northern Lights" 378 "Glendinning" 381 "B & G" 384 "Rose Point Navigation Systems" 385 "Johnson Outdoors Marine Electronics Inc Geonav" 394 "Capi 2" 396 "Beyond Measure" 400 "Livorsi Marine" 404 "ComNav" 409 "Chetco" 419 "Fusion Electronics" 421 "Standard Horizon" 422 "True Heading" 426 "Egersund Marine Electronics" 427 "em-trak Marine Electronics" 431 "Tohatsu Co, JP" 437 "Digital Yacht" 438 "Comar Systems Limited" 440 "Cummins" 443 "VDO (aka Continental-Corporation)" 451 "Parker Hannifin aka Village Marine Tech" 459 "Alltek Marine Electronics" 460 "SAN GIORGIO S.E.I.N" 466 "Veethree Electronics & Marine" 470 "SI-TEX Marine Electronics" 471 "Sea Cross Marine" 475 "GME aka Standard Communications" 476 "Humminbird Marine Electronics" 478 "Ocean Sat" 481 "Chetco Digital Instruments" 493 "Watcheye" 499 "Lcj Capteurs" 502 "Attwood Marine" 503 "Naviop S.R.L." 504 "Vesper Marine" 510 "Marinesoft" 513 "Simarine" 517 "NoLand Engineering" 518 "Transas USA" 529 "National Instruments Korea" 530 "National Marine Electronics Association" 532 "Onwa Marine" 540 "Webasto" 571 "Marinecraft (South Korea)" 573 "McMurdo Group aka Orolia" 578 "Advansea" 579 "KVH" 580 "San Jose Technology" 583 "Yacht Control" 586 "Suzuki Motor" 591 "US Coast Guard" 595 "Ship Module aka Customware" 600 "Aquatic AV" 605 "Aventics" 606 "Intellian" 612 "SamwonIT" 614 "Arlt Tecnologies" 637 "Bavaria Yachts" 641 "Diverse Yacht Services" 644 "Wema U.S.A dba KUS" 658 "Shenzhen Jiuzhou Himunication" 688 "Rockford" 699 "Harman International" 704 "JL Audio" 708 "Lars Thrane" 715 "Autonnic" 717 "Yacht Devices" 734 "REAP Systems" 735 "AEM Performance Electronics" 739 "LxNav" 741 "Littelfuse, Inc (formerly Carling Technologies)" 743 "DaeMyung" 744 "Woosung" 748 "ISOTTA IFRA srl" 773 "Clarion US" 776 "HMI Systems" 777 "Ocean Signal" 778 "Seakeeper" 781 "Poly Planar" 785 "Fischer Panda DE" 795 "Broyda Industries" 796 "Canadian Automotive" 797 "Tides Marine" 798 "Lumishore" 799 "Still Water Designs and Audio" 802 "BJ Technologies (Beneteau)" 803 "Gill Sensors" 811 "Blue Water Desalination" 815 "FLIR" 824 "Undheim Systems" 826 "Lewmar" 838 "TeamSurv" 844 "Fell Marine" 847 "Oceanvolt" 862 "Prospec" 868 "Data Panel" 890 "L3 Technologies" 894 "Rhodan Marine Systems" 896 "Nexfour Solutions" 905 "ASA Electronics" 909 "Marines Co (South Korea)" 911 "Nautic-on" 917 "Sentinel" 929 "JL Marine Systems" 930 "Ecotronix" 944 "Zontisa Marine" 951 "EXOR International" 962 "Timbolier Industries" 963 "TJC Micro" 968 "Cox Powertrain" 969 "Blue Seas" 981 "Kobelt Manufacturing" 992 "Blue Ocean IOT" 997 "Xenta Systems" 999 "Signal K" 1004 "Ultraflex" 1008 "Lintest SmartBoat" 1011 "Soundmax" 1020 "Team Italia Marine (Onyx Marine Automation s.r.l)" 1021 "Entratech" 1022 "ITC" 1029 "The Marine Guardian" 1047 "Sonic" 1051 "ProNav" 1053 "Vetus Maxwell INC." 1056 "Lithium Pros" 1059 "Boatrax" 1062 "Marol Co ltd" 1065 "CALYPSO Instruments" 1066 "Spot Zero Water" 1069 "Lithionics Battery" 1070 "Quick-teck Electronics" 1075 "Uniden America" 1083 "Nauticoncept" 1084 "Shadow-Caster LED lighting" 1085 "Wet Sounds" 1088 "E-T-A Circuit Breakers" 1092 "Scheiber" 1100 "Smart Yachts International Limited" 1109 "Dockmate" 1114 "Bobs Machine" 1118 "L3Harris ASV" 1119 "Balmar" 1120 "Elettromedia" 1127 "Electromaax" 1140 "Across Oceans Systems" 1145 "Kiwi Yachting" 1150 "BSB Artificial Intelligence" 1151 "Orca Technologies" 1154 "TBS Electronics" 1158 "Technoton Electroics" 1160 "MG Energy Systems" 1169 "Sea Machine Robotics" 1171 "Vista Manufacturing" 1183 "Zipwake" 1186 "Sailmon" 1192 "Airmoniq Pro Kft" 1194 "Sierra Marine" 1200 "Xinuo Information Technology (Xiamen)" 1218 "Septentrio" 1233 "NKE Marine Electronics" 1238 "SuperTrack Aps" 1239 "Honda Electronics" 1245 "Raritan Engineering" 1249 "Integrated Power Solutions AG" 1260 "Interactive Technologies" 1283 "LTG-Tech" 1299 "Energy Solutions (UK)" 1300 "WATT Fuel Cell" 1302 "Pro Mainer" 1305 "Dragonfly Energy" 1306 "Koden Electronics" 1311 "Humphree" 1316 "Hinkley Yachts" 1317 "Global Marine Management GmbH (GMM)" 1320 "Triskel Marine" 1330 "Warwick Control Technologies" 1331 "Dolphin Charger" 1337 "Barnacle Systems" 1348 "Radian IoT" 1353 "Ocean LED Marine" 1359 "BluNav" 1361 "OVA (Nantong Saiyang Electronics Co., Ltd)" 1368 "RAD Propulsion" 1369 "Electric Yacht" 1372 "Elco Motor Yachts" 1384 "Tecnoseal Foundry S.r.l" 1385 "Pro Charging Systems" 1389 "EVEX" 1398 "Gobius Sensor Technology" 1403 "Arco Marine" 1408 "Lenco Marine" 1413 "Naocontrol" 1417 "Revatek" 1438 "Aeolionics" 1439 "PredictWind" 1440 "Egis Mobile Electric" 1445 "Starboard Yacht Group" 1446 "Roswell Marine" 1451 "ePropulsion (Guangdong ePropulsion Technology Ltd.)" 1452 "Micro-Air" 1453 "Vital Battery" 1458 "Ride Controller" 1460 "Tocaro Blue" 1461 "Vanquish Yachts" 1471 "FT Technologies" 1478 "Alps Alpine" 1481 "E-Force Marine" 1482 "CMC Marine" 1483 "Nanjing Sandemarine Information Technology" 1850 "Teleflex Marine (SeaStar Solutions)" 1851 "Raymarine" 1852 "Navionics" 1853 "Japan Radio" 1854 "Northstar Technologies" 1855 "Furuno" 1856 "Trimble" 1857 "Simrad" 1858 "Litton" 1859 "Kvasar" 1860 "MMP" 1861 "Vector Cantech" 1862 "Yamaha Marine" 1863 "Faria Instruments" ;
VAL_ 2315198976 Industry_Code 0 "Global" 1 "Highway" 2 "Agriculture" 3 "Construction" 4 "Marine Industry" 5 "Industrial" ;
VAL_ 2315198976 Network_Group 0 "None" 1 "Default" 2 "Group 1" 3 "Group 2" 4 "Group 3" 5 "Group 4" 6 "Group 5" 7 "Group 6" ;
VAL_ 2315198976 Command_Type 2 "Follow Up" 10 "AP Command" 23 "Timer" 31 "Siren" 36 "AIS vessel selected" 255 "Alarm" ;
VAL_ 2315198976 Event 2 "Follow/Non Follow" 6 "Standby" 9 "Heading mode" 10 "Nav mode" 12 "No Drift mode" 13 "Non Follow Up mode" 14 "Follow Up mode" 15 "Wind mode" 17 "Tack" 18 "Square (Turn)" 19 "C-Turn" 20 "U-Turn" 21 "Spiral (Turn)" 22 "Zig Zag (Turn)" 23 "Lazy-S (Turn)" 24 "Depth (Turn)" 26 "Change course" 61 "Timer sync" 107 "MOB Activated" 108 "MOB Deactivated" 112 "Ping port end" 113 "Ping starboard end" ;
VAL_ 2315198976 Manufacturer_Code 69 "ARKS Enterprises" 78 "FW Murphy/Enovation Controls" 80 "Twin Disc" 85 "Kohler Power Systems" 88 "Hemisphere GPS" 135 "Airmar" 137 "Maretron" 140 "Lowrance" 144 "Mercury Marine" 147 "Nautibus Electronic" 148 "Blue Water Data" 154 "Westerbeke" 157 "ISSPRO" 161 "Offshore Systems (UK)" 163 "Evinrude/BRP" 165 "CPAC Systems" 168 "Xantrex Technology" 169 "Marlin Technologies" 172 "Yanmar Marine" 174 "Volvo Penta" 176 "Carling Technologies Inc. (Moritz Aerospace)" 185 "Beede Instruments" 192 "Floscan Instrument" 193 "Nobeltec" 198 "Mystic Valley Communications" 199 "Actia" 201 "Disenos Y Technologia" 211 "Digital Switching Systems" 215 "Xintex/Atena" 224 "EMMI NETWORK" 228 "ZF" 229 "Garmin" 233 "Yacht Monitoring Solutions" 235 "Sailormade Marine Telemetry/Tetra Technology" 243 "Eride" 257 "Honda Motor" 272 "Groco" 273 "Actisense" 274 "Amphenol LTW Technology" 275 "Navico" 283 "Hamilton Jet" 285 "Sea Recovery" 286 "Coelmo SRL Italy" 295 "BEP Marine" 304 "Empir Bus" 305 "NovAtel" 306 "Sleipner Motor" 307 "MBW Technologies" 315 "ICOM" 328 "Qwerty" 329 "Dief" 341 "Boening Automationstechnologie" 345 "Korean Maritime University" 351 "Thrane and Thrane" 355 "Mastervolt" 356 "Fischer Panda Generators" 358 "Victron Energy" 370 "Rolls Royce Marine" 373 "Electronic Design" 374 "Northern Lights" 378 "Glendinning" 381 "B & G" 384 "Rose Point Navigation Systems" 385 "Johnson Outdoors Marine Electronics Inc Geonav" 394 "Capi 2" 396 "Beyond Measure" 400 "Livorsi Marine" 404 "ComNav" 409 "Chetco" 419 "Fusion Electronics" 421 "Standard Horizon" 422 "True Heading" 426 "Egersund Marine Electronics" 427 "em-trak Marine Electronics" 431 "Tohatsu Co, JP" 437 "Digital Yacht" 438 "Comar Systems Limited" 440 "Cummins" 443 "VDO (aka Continental-Corporation)" 451 "Parker Hannifin aka Village Marine Tech" 459 "Alltek Marine Electronics" 460 "SAN GIORGIO S.E.I.N" 466 "Veethree Electronics & Marine" 470 "SI-TEX Marine Electronics" 471 "Sea Cross Marine" 475 "GME aka Standard Communications" 476 "Humminbird Marine Electronics" 478 "Ocean Sat" 481 "Chetco Digital Instruments" 493 "Watcheye" 499 "Lcj Capteurs" 502 "Attwood Marine" 503 "Naviop S.R.L." 504 "Vesper Marine" 510 "Marinesoft" 513 "Simarine" 517 "NoLand Engineering" 518 "Transas USA" 529 "National Instruments Korea" 530 "National Marine Electronics Association" 532 "Onwa Marine" 540 "Webasto" 571 "Marinecraft (South Korea)" 573 "McMurdo Group aka Orolia" 578 "Advansea" 579 "KVH" 580 "San Jose Technology" 583 "Yacht Control" 586 "Suzuki Motor" 591 "US Coast Guard" 595 "Ship Module aka Customware" 600 "Aquatic AV" 605 "Aventics" 606 "Intellian" 612 "SamwonIT" 614 "Arlt Tecnologies" 637 "Bavaria Yachts" 641 "Diverse Yacht Services" 644 "Wema U.S.A dba KUS" 658 "Shenzhen Jiuzhou Himunication" 688 "Rockford" 699 "Harman International" 704 "JL Audio" 708 "Lars Thrane" 715 "Autonnic" 717 "Yacht Devices" 734 "REAP Systems" 735 "AEM Performance Electronics" 739 "LxNav" 741 "Littelfuse, Inc (formerly Carling Technologies)" 743 "DaeMyung" 744 "Woosung" 748 "ISOTTA IFRA srl" 773 "Clarion US" 776 "HMI Systems" 777 "Ocean Signal" 778 "Seakeeper" 781 "Poly Planar" 785 "Fischer Panda DE" 795 "Broyda Industries" 796 "Canadian Automotive" 797 "Tides Marine" 798 "Lumishore" 799 "Still Water Designs and Audio" 802 "BJ Technologies (Beneteau)" 803 "Gill Sensors" 811 "Blue Water Desalination" 815 "FLIR" 824 "Undheim Systems" 826 "Lewmar" 838 "TeamSurv" 844 "Fell Marine" 847 "Oceanvolt" 862 "Prospec" 868 "Data Panel" 890 "L3 Technologies" 894 "Rhodan Marine Systems" 896 "Nexfour Solutions" 905 "ASA Electronics" 909 "Marines Co (South Korea)" 911 "Nautic-on" 917 "Sentinel" 929 "JL Marine Systems" 930 "Ecotronix" 944 "Zontisa Marine" 951 "EXOR International" 962 "Timbolier Industries" 963 "TJC Micro" 968 "Cox Powertrain" 969 "Blue Seas" 981 "Kobelt Manufacturing" 992 "Blue Ocean IOT" 997 "Xenta Systems" 999 "Signal K" 1004 "Ultraflex" 1008 "Lintest SmartBoat" 1011 "Soundmax" 1020 "Team Italia Marine (Onyx Marine Automation s.r.l)" 1021 "Entratech" 1022 "ITC" 1029 "The Marine Guardian" 1047 "Sonic" 1051 "ProNav" 1053 "Vetus Maxwell INC." 1056 "Lithium Pros" 1059 "Boatrax" 1062 "Marol Co ltd" 1065 "CALYPSO Instruments" 1066 "Spot Zero Water" 1069 "Lithionics Battery" 1070 "Quick-teck Electronics" 1075 "Uniden America" 1083 "Nauticoncept" 1084 "Shadow-Caster LED lighting" 1085 "Wet Sounds" 1088 "E-T-A Circuit Breakers" 1092 "Scheiber" 1100 "Smart Yachts International Limited" 1109 "Dockmate" 1114 "Bobs Machine" 1118 "L3Harris ASV" 1119 "Balmar" 1120 "Elettromedia" 1127 "Electromaax" 1140 "Across Oceans Systems" 1145 "Kiwi Yachting" 1150 "BSB Artificial Intelligence" 1151 "Orca Technologies" 1154 "TBS Electronics" 1158 "Technoton Electroics" 1160 "MG Energy Systems" 1169 "Sea Machine Robotics" 1171 "Vista Manufacturing" 1183 "Zipwake" 1186 "Sailmon" 1192 "Airmoniq Pro Kft" 1194 "Sierra Marine" 1200 "Xinuo Information Technology (Xiamen)" 1218 "Septentrio" 1233 "NKE Marine Electronics" 1238 "SuperTrack Aps" 1239 "Honda Electronics" 1245 "Raritan Engineering" 1249 "Integrated Power Solutions AG" 1260 "Interactive Technologies" 1283 "LTG-Tech" 1299 "Energy Solutions (UK)" 1300 "WATT Fuel Cell" 1302 "Pro Mainer" 1305 "Dragonfly Energy" 1306 "Koden Electronics" 1311 "Humphree" 1316 "Hinkley Yachts" 1317 "Global Marine Management GmbH (GMM)" 1320 "Triskel Marine" 1330 "Warwick Control Technologies" 1331 "Dolphin Charger" 1337 "Barnacle Systems" 1348 "Radian IoT" 1353 "Ocean LED Marine" 1359 "BluNav" 1361 "OVA (Nantong Saiyang Electronics Co., Ltd)" 1368 "RAD Propulsion" 1369 "Electric Yacht" 1372 "Elco Motor Yachts" 1384 "Tecnoseal Foundry S.r.l" 1385 "Pro Charging Systems" 1389 "EVEX" 1398 "Gobius Sensor Technology" 1403 "Arco Marine" 1408 "Lenco Marine" 1413 "Naocontrol" 1417 "Revatek" 1438 "Aeolionics" 1439 "PredictWind" 1440 "Egis Mobile Electric" 1445 "Starboard Yacht Group" 1446 "Roswell Marine" 1451 "ePropulsion (Guangdong ePropulsion Technology Ltd.)" 1452 "Micro-Air" 1453 "Vital Battery" 1458 "Ride Controller" 1460 "Tocaro Blue" 1461 "Vanquish Yachts" 1471 "FT Technologies" 1478 "Alps Alpine" 1481 "E-Force Marine" 1482 "CMC Marine" 1483 "Nanjing Sandemarine Information Technology" 1850 "Teleflex Marine (SeaStar Solutions)" 1851 "Raymarine" 1852 "Navionics" 1853 "Japan Radio" 1854 "Northstar Technologies" 1855 "Furuno" 1856 "Trimble" 1857 "Simrad" 1858 "Litton" 1859 "Kvasar" 1860 "MMP" 1861 "Vector Cantech" 1862 "Yamaha Marine" 1863 "Faria Instruments" ;
VAL_ 2315198976 Industry_Code 0 "Global" 1 "Highway" 2 "Agriculture" 3 "Construction" 4 "Marine Industry" 5 "Industrial" ;
VAL_ 2315198976 Network_Group 0 "None" 1 "Default" 2 "Group 1" 3 "Group 2" 4 "Group 3" 5 "Group 4" 6 "Group 5" 7 "Group 6" ;
VAL_ 2315198976 Command_Type 2 "Follow Up" 10 "AP Command" 23 "Timer" 31 "Siren" 36 "AIS vessel selected" 255 "Alarm" ;
VAL_ 2315198976 Event 2 "Follow/Non Follow" 6 "Standby" 9 "Heading mode" 10 "Nav mode" 12 "No Drift mode" 13 "Non Follow Up mode" 14 "Follow Up mode" 15 "Wind mode" 17 "Tack" 18 "Square (Turn)" 19 "C-Turn" 20 "U-Turn" 21 "Spiral (Turn)" 22 "Zig Zag (Turn)" 23 "Lazy-S (Turn)" 24 "Depth (Turn)" 26 "Change course" 61 "Timer sync" 107 "MOB Activated" 108 "MOB Deactivated" 112 "Ping port end" 113 "Ping starboard end" ;
VAL_ 2315198976 Manufacturer_Code 69 "ARKS Enterprises" 78 "FW Murphy/Enovation Controls" 80 "Twin Disc" 85 "Kohler Power Systems" 88 "Hemisphere GPS" 135 "Airmar" 137 "Maretron" 140 "Lowrance" 144 "Mercury Marine" 147 "Nautibus Electronic" 148 "Blue Water Data" 154 "Westerbeke" 157 "ISSPRO" 161 "Offshore Systems (UK)" 163 "Evinrude/BRP" 165 "CPAC Systems" 168 "Xantrex Technology" 169 "Marlin Technologies" 172 "Yanmar Marine" 174 "Volvo Penta" 176 "Carling Technologies Inc. (Moritz Aerospace)" 185 "Beede Instruments" 192 "Floscan Instrument" 193 "Nobeltec" 198 "Mystic Valley Communications" 199 "Actia" 201 "Disenos Y Technologia" 211 "Digital Switching Systems" 215 "Xintex/Atena" 224 "EMMI NETWORK" 228 "ZF" 229 "Garmin" 233 "Yacht Monitoring Solutions" 235 "Sailormade Marine Telemetry/Tetra Technology" 243 "Eride" 257 "Honda Motor" 272 "Groco" 273 "Actisense" 274 "Amphenol LTW Technology" 275 "Navico" 283 "Hamilton Jet" 285 "Sea Recovery" 286 "Coelmo SRL Italy" 295 "BEP Marine" 304 "Empir Bus" 305 "NovAtel" 306 "Sleipner Motor" 307 "MBW Technologies" 315 "ICOM" 328 "Qwerty" 329 "Dief" 341 "Boening Automationstechnologie" 345 "Korean Maritime University" 351 "Thrane and Thrane" 355 "Mastervolt" 356 "Fischer Panda Generators" 358 "Victron Energy" 370 "Rolls Royce Marine" 373 "Electronic Design" 374 "Northern Lights" 378 "Glendinning" 381 "B & G" 384 "Rose Point Navigation Systems" 385 "Johnson Outdoors Marine Electronics Inc Geonav" 394 "Capi 2" 396 "Beyond Measure" 400 "Livorsi Marine" 404 "ComNav" 409 "Chetco" 419 "Fusion Electronics" 421 "Standard Horizon" 422 "True Heading" 426 "Egersund Marine Electronics" 427 "em-trak Marine Electronics" 431 "Tohatsu Co, JP" 437 "Digital Yacht" 438 "Comar Systems Limited" 440 "Cummins" 443 "VDO (aka Continental-Corporation)" 451 "Parker Hannifin aka Village Marine Tech" 459 "Alltek Marine Electronics" 460 "SAN GIORGIO S.E.I.N" 466 "Veethree Electronics & Marine" 470 "SI-TEX Marine Electronics" 471 "Sea Cross Marine" 475 "GME aka Standard Communications" 476 "Humminbird Marine Electronics" 478 "Ocean Sat" 481 "Chetco Digital Instruments" 493 "Watcheye" 499 "Lcj Capteurs" 502 "Attwood Marine" 503 "Naviop S.R.L." 504 "Vesper Marine" 510 "Marinesoft" 513 "Simarine" 517 "NoLand Engineering" 518 "Transas USA" 529 "National Instruments Korea" 530 "National Marine Electronics Association" 532 "Onwa Marine" 540 "Webasto" 571 "Marinecraft (South Korea)" 573 "McMurdo Group aka Orolia" 578 "Advansea" 579 "KVH" 580 "San Jose Technology" 583 "Yacht Control" 586 "Suzuki Motor" 591 "US Coast Guard" 595 "Ship Module aka Customware" 600 "Aquatic AV" 605 "Aventics" 606 "Intellian" 612 "SamwonIT" 614 "Arlt Tecnologies" 637 "Bavaria Yachts" 641 "Diverse Yacht Services" 644 "Wema U.S.A dba KUS" 658 "Shenzhen Jiuzhou Himunication" 688 "Rockford" 699 "Harman International" 704 "JL Audio" 708 "Lars Thrane" 715 "Autonnic" 717 "Yacht Devices" 734 "REAP Systems" 735 "AEM Performance Electronics" 739 "LxNav" 741 "Littelfuse, Inc (formerly Carling Technologies)" 743 "DaeMyung" 744 "Woosung" 748 "ISOTTA IFRA srl" 773 "Clarion US" 776 "HMI Systems" 777 "Ocean Signal" 778 "Seakeeper" 781 "Poly Planar" 785 "Fischer Panda DE" 795 "Broyda Industries" 796 "Canadian Automotive" 797 "Tides Marine" 798 "Lumishore" 799 "Still Water Designs and Audio" 802 "BJ Technologies (Beneteau)" 803 "Gill Sensors" 811 "Blue Water Desalination" 815 "FLIR" 824 "Undheim Systems" 826 "Lewmar" 838 "TeamSurv" 844 "Fell Marine" 847 "Oceanvolt" 862 "Prospec" 868 "Data Panel" 890 "L3 Technologies" 894 "Rhodan Marine Systems" 896 "Nexfour Solutions" 905 "ASA Electronics" 909 "Marines Co (South Korea)" 911 "Nautic-on" 917 "Sentinel" 929 "JL Marine Systems" 930 "Ecotronix" 944 "Zontisa Marine" 951 "EXOR International" 962 "Timbolier Industries" 963 "TJC Micro" 968 "Cox Powertrain" 969 "Blue Seas" 981 "Kobelt Manufacturing" 992 "Blue Ocean IOT" 997 "Xenta Systems" 999 "Signal K" 1004 "Ultraflex" 1008 "Lintest SmartBoat" 1011 "Soundmax" 1020 "Team Italia Marine (Onyx Marine Automation s.r.l)" 1021 "Entratech" 1022 "ITC" 1029 "The Marine Guardian" 1047 "Sonic" 1051 "ProNav" 1053 "Vetus Maxwell INC." 1056 "Lithium Pros" 1059 "Boatrax" 1062 "Marol Co ltd" 1065 "CALYPSO Instruments" 1066 "Spot Zero Water" 1069 "Lithionics Battery" 1070 "Quick-teck Electronics" 1075 "Uniden America" 1083 "Nauticoncept" 1084 "Shadow-Caster LED lighting" 1085 "Wet Sounds" 1088 "E-T-A Circuit Breakers" 1092 "Scheiber" 1100 "Smart Yachts International Limited" 1109 "Dockmate" 1114 "Bobs Machine" 1118 "L3Harris ASV" 1119 "Balmar" 1120 "Elettromedia" 1127 "Electromaax" 1140 "Across Oceans Systems" 1145 "Kiwi Yachting" 1150 "BSB Artificial Intelligence" 1151 "Orca Technologies" 1154 "TBS Electronics" 1158 "Technoton Electroics" 1160 "MG Energy Systems" 1169 "Sea Machine Robotics" 1171 "Vista Manufacturing" 1183 "Zipwake" 1186 "Sailmon" 1192 "Airmoniq Pro Kft" 1194 "Sierra Marine" 1200 "Xinuo Information Technology (Xiamen)" 1218 "Septentrio" 1233 "NKE Marine Electronics" 1238 "SuperTrack Aps" 1239 "Honda Electronics" 1245 "Raritan Engineering" 1249 "Integrated Power Solutions AG" 1260 "Interactive Technologies" 1283 "LTG-Tech" 1299 "Energy Solutions (UK)" 1300 "WATT Fuel Cell" 1302 "Pro Mainer" 1305 "Dragonfly Energy" 1306 "Koden Electronics" 1311 "Humphree" 1316 "Hinkley Yachts" 1317 "Global Marine Management GmbH (GMM)" 1320 "Triskel Marine" 1330 "Warwick Control Technologies" 1331 "Dolphin Charger" 1337 "Barnacle Systems" 1348 "Radian IoT" 1353 "Ocean LED Marine" 1359 "BluNav" 1361 "OVA (Nantong Saiyang Electronics Co., Ltd)" 1368 "RAD Propulsion" 1369 "Electric Yacht" 1372 "Elco Motor Yachts" 1384 "Tecnoseal Foundry S.r.l" 1385 "Pro Charging Systems" 1389 "EVEX" 1398 "Gobius Sensor Technology" 1403 "Arco Marine" 1408 "Lenco Marine" 1413 "Naocontrol" 1417 "Revatek" 1438 "Aeolionics" 1439 "PredictWind" 1440 "Egis Mobile Electric" 1445 "Starboard Yacht Group" 1446 "Roswell Marine" 1451 "ePropulsion (Guangdong ePropulsion Technology Ltd.)" 1452 "Micro-Air" 1453 "Vital Battery" 1458 "Ride Controller" 1460 "Tocaro Blue" 1461 "Vanquish Yachts" 1471 "FT Technologies" 1478 "Alps Alpine" 1481 "E-Force Marine" 1482 "CMC Marine" 1483 "Nanjing Sandemarine Information Technology" 1850 "Teleflex Marine (SeaStar Solutions)" 1851 "Raymarine" 1852 "Navionics" 1853 "Japan Radio" 1854 "Northstar Technologies" 1855 "Furuno" 1856 "Trimble" 1857 "Simrad" 1858 "Litton" 1859 "Kvasar" 1860 "MMP" 1861 "Vector Cantech" 1862 "Yamaha Marine" 1863 "Faria Instruments" ;
VAL_ 2315198976 Industry_Code 0 "Global" 1 "Highway" 2 "Agriculture" 3 "Construction" 4 "Marine Industry" 5 "Industrial" ;
VAL_ 2315198976 Network_Group 0 "None" 1 "Default" 2 "Group 1" 3 "Group 2" 4 "Group 3" 5 "Group 4" 6 "Group 5" 7 "Group 6" ;
VAL_ 2315198976 Command_Type 2 "Follow Up" 10 "AP Command" 23 "Timer" 31 "Siren" 36 "AIS vessel selected" 255 "Alarm" ;
VAL_ 2315198976 Event 2 "Follow/Non Follow" 6 "Standby" 9 "Heading mode" 10 "Nav mode" 12 "No Drift mode" 13 "Non Follow Up mode" 14 "Follow Up mode" 15 "Wind mode" 17 "Tack" 18 "Square (Turn)" 19 "C-Turn" 20 "U-Turn" 21 "Spiral (Turn)" 22 "Zig Zag (Turn)" 23 "Lazy-S (Turn)" 24 "Depth (Turn)" 26 "Change course" 61 "Timer sync" 107 "MOB Activated" 108 "MOB Deactivated" 112 "Ping port end" 113 "Ping starboard end" ;
VAL_ 2315198976 Manufacturer_Code 69 "ARKS Enterprises" 78 "FW Murphy/Enovation Controls" 80 "Twin Disc" 85 "Kohler Power Systems" 88 "Hemisphere GPS" 135 "Airmar" 137 "Maretron" 140 "Lowrance" 144 "Mercury Marine" 147 "Nautibus Electronic" 148 "Blue Water Data" 154 "Westerbeke" 157 "ISSPRO" 161 "Offshore Systems (UK)" 163 "Evinrude/BRP" 165 "CPAC Systems" 168 "Xantrex Technology" 169 "Marlin Technologies" 172 "Yanmar Marine" 174 "Volvo Penta" 176 "Carling Technologies Inc. (Moritz Aerospace)" 185 "Beede Instruments" 192 "Floscan Instrument" 193 "Nobeltec" 198 "Mystic Valley Communications" 199 "Actia" 201 "Disenos Y Technologia" 211 "Digital Switching Systems" 215 "Xintex/Atena" 224 "EMMI NETWORK" 228 "ZF" 229 "Garmin" 233 "Yacht Monitoring Solutions" 235 "Sailormade Marine Telemetry/Tetra Technology" 243 "Eride" 257 "Honda Motor" 272 "Groco" 273 "Actisense" 274 "Amphenol LTW Technology" 275 "Navico" 283 "Hamilton Jet" 285 "Sea Recovery" 286 "Coelmo SRL Italy" 295 "BEP Marine" 304 "Empir Bus" 305 "NovAtel" 306 "Sleipner Motor" 307 "MBW Technologies" 315 "ICOM" 328 "Qwerty" 329 "Dief" 341 "Boening Automationstechnologie" 345 "Korean Maritime University" 351 "Thrane and Thrane" 355 "Mastervolt" 356 "Fischer Panda Generators" 358 "Victron Energy" 370 "Rolls Royce Marine" 373 "Electronic Design" 374 "Northern Lights" 378 "Glendinning" 381 "B & G" 384 "Rose Point Navigation Systems" 385 "Johnson Outdoors Marine Electronics Inc Geonav" 394 "Capi 2" 396 "Beyond Measure" 400 "Livorsi Marine" 404 "ComNav" 409 "Chetco" 419 "Fusion Electronics" 421 "Standard Horizon" 422 "True Heading" 426 "Egersund Marine Electronics" 427 "em-trak Marine Electronics" 431 "Tohatsu Co, JP" 437 "Digital Yacht" 438 "Comar Systems Limited" 440 "Cummins" 443 "VDO (aka Continental-Corporation)" 451 "Parker Hannifin aka Village Marine Tech" 459 "Alltek Marine Electronics" 460 "SAN GIORGIO S.E.I.N" 466 "Veethree Electronics & Marine" 470 "SI-TEX Marine Electronics" 471 "Sea Cross Marine" 475 "GME aka Standard Communications" 476 "Humminbird Marine Electronics" 478 "Ocean Sat" 481 "Chetco Digital Instruments" 493 "Watcheye" 499 "Lcj Capteurs" 502 "Attwood Marine" 503 "Naviop S.R.L." 504 "Vesper Marine" 510 "Marinesoft" 513 "Simarine" 517 "NoLand Engineering" 518 "Transas USA" 529 "National Instruments Korea" 530 "National Marine Electronics Association" 532 "Onwa Marine" 540 "Webasto" 571 "Marinecraft (South Korea)" 573 "McMurdo Group aka Orolia" 578 "Advansea" 579 "KVH" 580 "San Jose Technology" 583 "Yacht Control" 586 "Suzuki Motor" 591 "US Coast Guard" 595 "Ship Module aka Customware" 600 "Aquatic AV" 605 "Aventics" 606 "Intellian" 612 "SamwonIT" 614 "Arlt Tecnologies" 637 "Bavaria Yachts" 641 "Diverse Yacht Services" 644 "Wema U.S.A dba KUS" 658 "Shenzhen Jiuzhou Himunication" 688 "Rockford" 699 "Harman International" 704 "JL Audio" 708 "Lars Thrane" 715 "Autonnic" 717 "Yacht Devices" 734 "REAP Systems" 735 "AEM Performance Electronics" 739 "LxNav" 741 "Littelfuse, Inc (formerly Carling Technologies)" 743 "DaeMyung" 744 "Woosung" 748 "ISOTTA IFRA srl" 773 "Clarion US" 776 "HMI Systems" 777 "Ocean Signal" 778 "Seakeeper" 781 "Poly Planar" 785 "Fischer Panda DE" 795 "Broyda Industries" 796 "Canadian Automotive" 797 "Tides Marine" 798 "Lumishore" 799 "Still Water Designs and Audio" 802 "BJ Technologies (Beneteau)" 803 "Gill Sensors" 811 "Blue Water Desalination" 815 "FLIR" 824 "Undheim Systems" 826 "Lewmar" 838 "TeamSurv" 844 "Fell Marine" 847 "Oceanvolt" 862 "Prospec" 868 "Data Panel" 890 "L3 Technologies" 894 "Rhodan Marine Systems" 896 "Nexfour Solutions" 905 "ASA Electronics" 909 "Marines Co (South Korea)" 911 "Nautic-on" 917 "Sentinel" 929 "JL Marine Systems" 930 "Ecotronix" 944 "Zontisa Marine" 951 "EXOR International" 962 "Timbolier Industries" 963 "TJC Micro" 968 "Cox Powertrain" 969 "Blue Seas" 981 "Kobelt Manufacturing" 992 "Blue Ocean IOT" 997 "Xenta Systems" 999 "Signal K" 1004 "Ultraflex" 1008 "Lintest SmartBoat" 1011 "Soundmax" 1020 "Team Italia Marine (Onyx Marine Automation s.r.l)" 1021 "Entratech" 1022 "ITC" 1029 "The Marine Guardian" 1047 "Sonic" 1051 "ProNav" 1053 "Vetus Maxwell INC." 1056 "Lithium Pros" 1059 "Boatrax" 1062 "Marol Co ltd" 1065 "CALYPSO Instruments" 1066 "Spot Zero Water" 1069 "Lithionics Battery" 1070 "Quick-teck Electronics" 1075 "Uniden America" 1083 "Nauticoncept" 1084 "Shadow-Caster LED lighting" 1085 "Wet Sounds" 1088 "E-T-A Circuit Breakers" 1092 "Scheiber" 1100 "Smart Yachts International Limited" 1109 "Dockmate" 1114 "Bobs Machine" 1118 "L3Harris ASV" 1119 "Balmar" 1120 "Elettromedia" 1127 "Electromaax" 1140 "Across Oceans Systems" 1145 "Kiwi Yachting" 1150 "BSB Artificial Intelligence" 1151 "Orca Technologies" 1154 "TBS Electronics" 1158 "Technoton Electroics" 1160 "MG Energy Systems" 1169 "Sea Machine Robotics" 1171 "Vista Manufacturing" 1183 "Zipwake" 1186 "Sailmon" 1192 "Airmoniq Pro Kft" 1194 "Sierra Marine" 1200 "Xinuo Information Technology (Xiamen)" 1218 "Septentrio" 1233 "NKE Marine Electronics" 1238 "SuperTrack Aps" 1239 "Honda Electronics" 1245 "Raritan Engineering" 1249 "Integrated Power Solutions AG" 1260 "Interactive Technologies" 1283 "LTG-Tech" 1299 "Energy Solutions (UK)" 1300 "WATT Fuel Cell" 1302 "Pro Mainer" 1305 "Dragonfly Energy" 1306 "Koden Electronics" 1311 "Humphree" 1316 "Hinkley Yachts" 1317 "Global Marine Management GmbH (GMM)" 1320 "Triskel Marine" 1330 "Warwick Control Technologies" 1331 "Dolphin Charger" 1337 "Barnacle Systems" 1348 "Radian IoT" 1353 "Ocean LED Marine" 1359 "BluNav" 1361 "OVA (Nantong Saiyang Electronics Co., Ltd)" 1368 "RAD Propulsion" 1369 "Electric Yacht" 1372 "Elco Motor Yachts" 1384 "Tecnoseal Foundry S.r.l" 1385 "Pro Charging Systems" 1389 "EVEX" 1398 "Gobius Sensor Technology" 1403 "Arco Marine" 1408 "Lenco Marine" 1413 "Naocontrol" 1417 "Revatek" 1438 "Aeolionics" 1439 "PredictWind" 1440 "Egis Mobile Electric" 1445 "Starboard Yacht Group" 1446 "Roswell Marine" 1451 "ePropulsion (Guangdong ePropulsion Technology Ltd.)" 1452 "Micro-Air" 1453 "Vital Battery" 1458 "Ride Controller" 1460 "Tocaro Blue" 1461 "Vanquish Yachts" 1471 "FT Technologies" 1478 "Alps Alpine" 1481 "E-Force Marine" 1482 "CMC Marine" 1483 "Nanjing Sandemarine Information Technology" 1850 "Teleflex Marine (SeaStar Solutions)" 1851 "Raymarine" 1852 "Navionics" 1853 "Japan Radio" 1854 "Northstar Technologies" 1855 "Furuno" 1856 "Trimble" 1857 "Simrad" 1858 "Litton" 1859 "Kvasar" 1860 "MMP" 1861 "Vector Cantech" 1862 "Yamaha Marine" 1863 "Faria Instruments" ;
VAL_ 2315198976 Industry_Code 0 "Global" 1 "Highway" 2 "Agriculture" 3 "Construction" 4 "Marine Industry" 5 "Industrial" ;
VAL_ 2315198976 Network_Group 0 "None" 1 "Default" 2 "Group 1" 3 "Group 2" 4 "Group 3" 5 "Group 4" 6 "Group 5" 7 "Group 6" ;
VAL_ 2315198976 Manufacturer_Code 69 "ARKS Enterprises" 78 "FW Murphy/Enovation Controls" 80 "Twin Disc" 85 "Kohler Power Systems" 88 "Hemisphere GPS" 135 "Airmar" 137 "Maretron" 140 "Lowrance" 144 "Mercury Marine" 147 "Nautibus Electronic" 148 "Blue Water Data" 154 "Westerbeke" 157 "ISSPRO" 161 "Offshore Systems (UK)" 163 "Evinrude/BRP" 165 "CPAC Systems" 168 "Xantrex Technology" 169 "Marlin Technologies" 172 "Yanmar Marine" 174 "Volvo Penta" 176 "Carling Technologies Inc. (Moritz Aerospace)" 185 "Beede Instruments" 192 "Floscan Instrument" 193 "Nobeltec" 198 "Mystic Valley Communications" 199 "Actia" 201 "Disenos Y Technologia" 211 "Digital Switching Systems" 215 "Xintex/Atena" 224 "EMMI NETWORK" 228 "ZF" 229 "Garmin" 233 "Yacht Monitoring Solutions" 235 "Sailormade Marine Telemetry/Tetra Technology" 243 "Eride" 257 "Honda Motor" 272 "Groco" 273 "Actisense" 274 "Amphenol LTW Technology" 275 "Navico" 283 "Hamilton Jet" 285 "Sea Recovery" 286 "Coelmo SRL Italy" 295 "BEP Marine" 304 "Empir Bus" 305 "NovAtel" 306 "Sleipner Motor" 307 "MBW Technologies" 315 "ICOM" 328 "Qwerty" 329 "Dief" 341 "Boening Automationstechnologie" 345 "Korean Maritime University" 351 "Thrane and Thrane" 355 "Mastervolt" 356 "Fischer Panda Generators" 358 "Victron Energy" 370 "Rolls Royce Marine" 373 "Electronic Design" 374 "Northern Lights" 378 "Glendinning" 381 "B & G" 384 "Rose Point Navigation Systems" 385 "Johnson Outdoors Marine Electronics Inc Geonav" 394 "Capi 2" 396 "Beyond Measure" 400 "Livorsi Marine" 404 "ComNav" 409 "Chetco" 419 "Fusion Electronics" 421 "Standard Horizon" 422 "True Heading" 426 "Egersund Marine Electronics" 427 "em-trak Marine Electronics" 431 "Tohatsu Co, JP" 437 "Digital Yacht" 438 "Comar Systems Limited" 440 "Cummins" 443 "VDO (aka Continental-Corporation)" 451 "Parker Hannifin aka Village Marine Tech" 459 "Alltek Marine Electronics" 460 "SAN GIORGIO S.E.I.N" 466 "Veethree Electronics & Marine" 470 "SI-TEX Marine Electronics" 471 "Sea Cross Marine" 475 "GME aka Standard Communications" 476 "Humminbird Marine Electronics" 478 "Ocean Sat" 481 "Chetco Digital Instruments" 493 "Watcheye" 499 "Lcj Capteurs" 502 "Attwood Marine" 503 "Naviop S.R.L." 504 "Vesper Marine" 510 "Marinesoft" 513 "Simarine" 517 "NoLand Engineering" 518 "Transas USA" 529 "National Instruments Korea" 530 "National Marine Electronics Association" 532 "Onwa Marine" 540 "Webasto" 571 "Marinecraft (South Korea)" 573 "McMurdo Group aka Orolia" 578 "Advansea" 579 "KVH" 580 "San Jose Technology" 583 "Yacht Control" 586 "Suzuki Motor" 591 "US Coast Guard" 595 "Ship Module aka Customware" 600 "Aquatic AV" 605 "Aventics" 606 "Intellian" 612 "SamwonIT" 614 "Arlt Tecnologies" 637 "Bavaria Yachts" 641 "Diverse Yacht Services" 644 "Wema U.S.A dba KUS" 658 "Shenzhen Jiuzhou Himunication" 688 "Rockford" 699 "Harman International" 704 "JL Audio" 708 "Lars Thrane" 715 "Autonnic" 717 "Yacht Devices" 734 "REAP Systems" 735 "AEM Performance Electronics" 739 "LxNav" 741 "Littelfuse, Inc (formerly Carling Technologies)" 743 "DaeMyung" 744 "Woosung" 748 "ISOTTA IFRA srl" 773 "Clarion US" 776 "HMI Systems" 777 "Ocean Signal" 778 "Seakeeper" 781 "Poly Planar" 785 "Fischer Panda DE" 795 "Broyda Industries" 796 "Canadian Automotive" 797 "Tides Marine" 798 "Lumishore" 799 "Still Water Designs and Audio" 802 "BJ Technologies (Beneteau)" 803 "Gill Sensors" 811 "Blue Water Desalination" 815 "FLIR" 824 "Undheim Systems" 826 "Lewmar" 838 "TeamSurv" 844 "Fell Marine" 847 "Oceanvolt" 862 "Prospec" 868 "Data Panel" 890 "L3 Technologies" 894 "Rhodan Marine Systems" 896 "Nexfour Solutions" 905 "ASA Electronics" 909 "Marines Co (South Korea)" 911 "Nautic-on" 917 "Sentinel" 929 "JL Marine Systems" 930 "Ecotronix" 944 "Zontisa Marine" 951 "EXOR International" 962 "Timbolier Industries" 963 "TJC Micro" 968 "Cox Powertrain" 969 "Blue Seas" 981 "Kobelt Manufacturing" 992 "Blue Ocean IOT" 997 "Xenta Systems" 999 "Signal K" 1004 "Ultraflex" 1008 "Lintest SmartBoat" 1011 "Soundmax" 1020 "Team Italia Marine (Onyx Marine Automation s.r.l)" 1021 "Entratech" 1022 "ITC" 1029 "The Marine Guardian" 1047 "Sonic" 1051 "ProNav" 1053 "Vetus Maxwell INC." 1056 "Lithium Pros" 1059 "Boatrax" 1062 "Marol Co ltd" 1065 "CALYPSO Instruments" 1066 "Spot Zero Water" 1069 "Lithionics Battery" 1070 "Quick-teck Electronics" 1075 "Uniden America" 1083 "Nauticoncept" 1084 "Shadow-Caster LED lighting" 1085 "Wet Sounds" 1088 "E-T-A Circuit Breakers" 1092 "Scheiber" 1100 "Smart Yachts International Limited" 1109 "Dockmate" 1114 "Bobs Machine" 1118 "L3Harris ASV" 1119 "Balmar" 1120 "Elettromedia" 1127 "Electromaax" 1140 "Across Oceans Systems" 1145 "Kiwi Yachting" 1150 "BSB Artificial Intelligence" 1151 "Orca Technologies" 1154 "TBS Electronics" 1158 "Technoton Electroics" 1160 "MG Energy Systems" 1169 "Sea Machine Robotics" 1171 "Vista Manufacturing" 1183 "Zipwake" 1186 "Sailmon" 1192 "Airmoniq Pro Kft" 1194 "Sierra Marine" 1200 "Xinuo Information Technology (Xiamen)" 1218 "Septentrio" 1233 "NKE Marine Electronics" 1238 "SuperTrack Aps" 1239 "Honda Electronics" 1245 "Raritan Engineering" 1249 "Integrated Power Solutions AG" 1260 "Interactive Technologies" 1283 "LTG-Tech" 1299 "Energy Solutions (UK)" 1300 "WATT Fuel Cell" 1302 "Pro Mainer" 1305 "Dragonfly Energy" 1306 "Koden Electronics" 1311 "Humphree" 1316 "Hinkley Yachts" 1317 "Global Marine Management GmbH (GMM)" 1320 "Triskel Marine" 1330 "Warwick Control Technologies" 1331 "Dolphin Charger" 1337 "Barnacle Systems" 1348 "Radian IoT" 1353 "Ocean LED Marine" 1359 "BluNav" 1361 "OVA (Nantong Saiyang Electronics Co., Ltd)" 1368 "RAD Propulsion" 1369 "Electric Yacht" 1372 "Elco Motor Yachts" 1384 "Tecnoseal Foundry S.r.l" 1385 "Pro Charging Systems" 1389 "EVEX" 1398 "Gobius Sensor Technology" 1403 "Arco Marine" 1408 "Lenco Marine" 1413 "Naocontrol" 1417 "Revatek" 1438 "Aeolionics" 1439 "PredictWind" 1440 "Egis Mobile Electric" 1445 "Starboard Yacht Group" 1446 "Roswell Marine" 1451 "ePropulsion (Guangdong ePropulsion Technology Ltd.)" 1452 "Micro-Air" 1453 "Vital Battery" 1458 "Ride Controller" 1460 "Tocaro Blue" 1461 "Vanquish Yachts" 1471 "FT Technologies" 1478 "Alps Alpine" 1481 "E-Force Marine" 1482 "CMC Marine" 1483 "Nanjing Sandemarine Information Technology" 1850 "Teleflex Marine (SeaStar Solutions)" 1851 "Raymarine" 1852 "Navionics" 1853 "Japan Radio" 1854 "Northstar Technologies" 1855 "Furuno" 1856 "Trimble" 1857 "Simrad" 1858 "Litton" 1859 "Kvasar" 1860 "MMP" 1861 "Vector Cantech" 1862 "Yamaha Marine" 1863 "Faria Instruments" ;
VAL_ 2315198976 Industry_Code 0 "Global" 1 "Highway" 2 "Agriculture" 3 "Construction" 4 "Marine Industry" 5 "Industrial" ;
VAL_ 2315198976 Network_Group 0 "None" 1 "Default" 2 "Group 1" 3 "Group 2" 4 "Group 3" 5 "Group 4" 6 "Group 5" 7 "Group 6" ;
VAL_ 2315198976 Event_Type 2 "Follow Up" 10 "AP Command" 23 "Timer" 31 "Siren" 36 "AIS vessel selected" 255 "Alarm" ;
VAL_ 2315198976 Event 61 "Race Timer Start" 62 "Race Timer Stop" 63 "Race Timer Sync" 64 "Race Timer Reset" 65 "Trip Timer Reset All" 100 "Trip Timer Enable" 101 "Trip Timer Disable" ;
VAL_ 2650743552 Manufacturer_Code 69 "ARKS Enterprises" 78 "FW Murphy/Enovation Controls" 80 "Twin Disc" 85 "Kohler Power Systems" 88 "Hemisphere GPS" 135 "Airmar" 137 "Maretron" 140 "Lowrance" 144 "Mercury Marine" 147 "Nautibus Electronic" 148 "Blue Water Data" 154 "Westerbeke" 157 "ISSPRO" 161 "Offshore Systems (UK)" 163 "Evinrude/BRP" 165 "CPAC Systems" 168 "Xantrex Technology" 169 "Marlin Technologies" 172 "Yanmar Marine" 174 "Volvo Penta" 176 "Carling Technologies Inc. (Moritz Aerospace)" 185 "Beede Instruments" 192 "Floscan Instrument" 193 "Nobeltec" 198 "Mystic Valley Communications" 199 "Actia" 201 "Disenos Y Technologia" 211 "Digital Switching Systems" 215 "Xintex/Atena" 224 "EMMI NETWORK" 228 "ZF" 229 "Garmin" 233 "Yacht Monitoring Solutions" 235 "Sailormade Marine Telemetry/Tetra Technology" 243 "Eride" 257 "Honda Motor" 272 "Groco" 273 "Actisense" 274 "Amphenol LTW Technology" 275 "Navico" 283 "Hamilton Jet" 285 "Sea Recovery" 286 "Coelmo SRL Italy" 295 "BEP Marine" 304 "Empir Bus" 305 "NovAtel" 306 "Sleipner Motor" 307 "MBW Technologies" 315 "ICOM" 328 "Qwerty" 329 "Dief" 341 "Boening Automationstechnologie" 345 "Korean Maritime University" 351 "Thrane and Thrane" 355 "Mastervolt" 356 "Fischer Panda Generators" 358 "Victron Energy" 370 "Rolls Royce Marine" 373 "Electronic Design" 374 "Northern Lights" 378 "Glendinning" 381 "B & G" 384 "Rose Point Navigation Systems" 385 "Johnson Outdoors Marine Electronics Inc Geonav" 394 "Capi 2" 396 "Beyond Measure" 400 "Livorsi Marine" 404 "ComNav" 409 "Chetco" 419 "Fusion Electronics" 421 "Standard Horizon" 422 "True Heading" 426 "Egersund Marine Electronics" 427 "em-trak Marine Electronics" 431 "Tohatsu Co, JP" 437 "Digital Yacht" 438 "Comar Systems Limited" 440 "Cummins" 443 "VDO (aka Continental-Corporation)" 451 "Parker Hannifin aka Village Marine Tech" 459 "Alltek Marine Electronics" 460 "SAN GIORGIO S.E.I.N" 466 "Veethree Electronics & Marine" 470 "SI-TEX Marine Electronics" 471 "Sea Cross Marine" 475 "GME aka Standard Communications" 476 "Humminbird Marine Electronics" 478 "Ocean Sat" 481 "Chetco Digital Instruments" 493 "Watcheye" 499 "Lcj Capteurs" 502 "Attwood Marine" 503 "Naviop S.R.L." 504 "Vesper Marine" 510 "Marinesoft" 513 "Simarine" 517 "NoLand Engineering" 518 "Transas USA" 529 "National Instruments Korea" 530 "National Marine Electronics Association" 532 "Onwa Marine" 540 "Webasto" 571 "Marinecraft (South Korea)" 573 "McMurdo Group aka Orolia" 578 "Advansea" 579 "KVH" 580 "San Jose Technology" 583 "Yacht Control" 586 "Suzuki Motor" 591 "US Coast Guard" 595 "Ship Module aka Customware" 600 "Aquatic AV" 605 "Aventics" 606 "Intellian" 612 "SamwonIT" 614 "Arlt Tecnologies" 637 "Bavaria Yachts" 641 "Diverse Yacht Services" 644 "Wema U.S.A dba KUS" 658 "Shenzhen Jiuzhou Himunication" 688 "Rockford" 699 "Harman International" 704 "JL Audio" 708 "Lars Thrane" 715 "Autonnic" 717 "Yacht Devices" 734 "REAP Systems" 735 "AEM Performance Electronics" 739 "LxNav" 741 "Littelfuse, Inc (formerly Carling Technologies)" 743 "DaeMyung" 744 "Woosung" 748 "ISOTTA IFRA srl" 773 "Clarion US" 776 "HMI Systems" 777 "Ocean Signal" 778 "Seakeeper" 781 "Poly Planar" 785 "Fischer Panda DE" 795 "Broyda Industries" 796 "Canadian Automotive" 797 "Tides Marine" 798 "Lumishore" 799 "Still Water Designs and Audio" 802 "BJ Technologies (Beneteau)" 803 "Gill Sensors" 811 "Blue Water Desalination" 815 "FLIR" 824 "Undheim Systems" 826 "Lewmar" 838 "TeamSurv" 844 "Fell Marine" 847 "Oceanvolt" 862 "Prospec" 868 "Data Panel" 890 "L3 Technologies" 894 "Rhodan Marine Systems" 896 "Nexfour Solutions" 905 "ASA Electronics" 909 "Marines Co (South Korea)" 911 "Nautic-on" 917 "Sentinel" 929 "JL Marine Systems" 930 "Ecotronix" 944 "Zontisa Marine" 951 "EXOR International" 962 "Timbolier Industries" 963 "TJC Micro" 968 "Cox Powertrain" 969 "Blue Seas" 981 "Kobelt Manufacturing" 992 "Blue Ocean IOT" 997 "Xenta Systems" 999 "Signal K" 1004 "Ultraflex" 1008 "Lintest SmartBoat" 1011 "Soundmax" 1020 "Team Italia Marine (Onyx Marine Automation s.r.l)" 1021 "Entratech" 1022 "ITC" 1029 "The Marine Guardian" 1047 "Sonic" 1051 "ProNav" 1053 "Vetus Maxwell INC." 1056 "Lithium Pros" 1059 "Boatrax" 1062 "Marol Co ltd" 1065 "CALYPSO Instruments" 1066 "Spot Zero Water" 1069 "Lithionics Battery" 1070 "Quick-teck Electronics" 1075 "Uniden America" 1083 "Nauticoncept" 1084 "Shadow-Caster LED lighting" 1085 "Wet Sounds" 1088 "E-T-A Circuit Breakers" 1092 "Scheiber" 1100 "Smart Yachts International Limited" 1109 "Dockmate" 1114 "Bobs Machine" 1118 "L3Harris ASV" 1119 "Balmar" 1120 "Elettromedia" 1127 "Electromaax" 1140 "Across Oceans Systems" 1145 "Kiwi Yachting" 1150 "BSB Artificial Intelligence" 1151 "Orca Technologies" 1154 "TBS Electronics" 1158 "Technoton Electroics" 1160 "MG Energy Systems" 1169 "Sea Machine Robotics" 1171 "Vista Manufacturing" 1183 "Zipwake" 1186 "Sailmon" 1192 "Airmoniq Pro Kft" 1194 "Sierra Marine" 1200 "Xinuo Information Technology (Xiamen)" 1218 "Septentrio" 1233 "NKE Marine Electronics" 1238 "SuperTrack Aps" 1239 "Honda Electronics" 1245 "Raritan Engineering" 1249 "Integrated Power Solutions AG" 1260 "Interactive Technologies" 1283 "LTG-Tech" 1299 "Energy Solutions (UK)" 1300 "WATT Fuel Cell" 1302 "Pro Mainer" 1305 "Dragonfly Energy" 1306 "Koden Electronics" 1311 "Humphree" 1316 "Hinkley Yachts" 1317 "Global Marine Management GmbH (GMM)" 1320 "Triskel Marine" 1330 "Warwick Control Technologies" 1331 "Dolphin Charger" 1337 "Barnacle Systems" 1348 "Radian IoT" 1353 "Ocean LED Marine" 1359 "BluNav" 1361 "OVA (Nantong Saiyang Electronics Co., Ltd)" 1368 "RAD Propulsion" 1369 "Electric Yacht" 1372 "Elco Motor Yachts" 1384 "Tecnoseal Foundry S.r.l" 1385 "Pro Charging Systems" 1389 "EVEX" 1398 "Gobius Sensor Technology" 1403 "Arco Marine" 1408 "Lenco Marine" 1413 "Naocontrol" 1417 "Revatek" 1438 "Aeolionics" 1439 "PredictWind" 1440 "Egis Mobile Electric" 1445 "Starboard Yacht Group" 1446 "Roswell Marine" 1451 "ePropulsion (Guangdong ePropulsion Technology Ltd.)" 1452 "Micro-Air" 1453 "Vital Battery" 1458 "Ride Controller" 1460 "Tocaro Blue" 1461 "Vanquish Yachts" 1471 "FT Technologies" 1478 "Alps Alpine" 1481 "E-Force Marine" 1482 "CMC Marine" 1483 "Nanjing Sandemarine Information Technology" 1850 "Teleflex Marine (SeaStar Solutions)" 1851 "Raymarine" 1852 "Navionics" 1853 "Japan Radio" 1854 "Northstar Technologies" 1855 "Furuno" 1856 "Trimble" 1857 "Simrad" 1858 "Litton" 1859 "Kvasar" 1860 "MMP" 1861 "Vector Cantech" 1862 "Yamaha Marine" 1863 "Faria Instruments" ;
VAL_ 2650743552 Industry_Code 0 "Global" 1 "Highway" 2 "Agriculture" 3 "Construction" 4 "Marine Industry" 5 "Industrial" ;
VAL_ 2650743552 Network_Group 0 "None" 1 "Default" 2 "Group 1" 3 "Group 2" 4 "Group 3" 5 "Group 4" 6 "Group 5" 7 "Group 6" ;
VAL_ 2650743552 Command_Type 2 "Follow Up" 10 "AP Command" 23 "Timer" 31 "Siren" 36 "AIS vessel selected" 255 "Alarm" ;
VAL_ 2650743552 Event 2 "Follow/Non Follow" 6 "Standby" 9 "Heading mode" 10 "Nav mode" 12 "No Drift mode" 13 "Non Follow Up mode" 14 "Follow Up mode" 15 "Wind mode" 17 "Tack" 18 "Square (Turn)" 19 "C-Turn" 20 "U-Turn" 21 "Spiral (Turn)" 22 "Zig Zag (Turn)" 23 "Lazy-S (Turn)" 24 "Depth (Turn)" 26 "Change course" 61 "Timer sync" 107 "MOB Activated" 108 "MOB Deactivated" 112 "Ping port end" 113 "Ping starboard end" ;
VAL_ 2650743552 Manufacturer_Code 69 "ARKS Enterprises" 78 "FW Murphy/Enovation Controls" 80 "Twin Disc" 85 "Kohler Power Systems" 88 "Hemisphere GPS" 135 "Airmar" 137 "Maretron" 140 "Lowrance" 144 "Mercury Marine" 147 "Nautibus Electronic" 148 "Blue Water Data" 154 "Westerbeke" 157 "ISSPRO" 161 "Offshore Systems (UK)" 163 "Evinrude/BRP" 165 "CPAC Systems" 168 "Xantrex Technology" 169 "Marlin Technologies" 172 "Yanmar Marine" 174 "Volvo Penta" 176 "Carling Technologies Inc. (Moritz Aerospace)" 185 "Beede Instruments" 192 "Floscan Instrument" 193 "Nobeltec" 198 "Mystic Valley Communications" 199 "Actia" 201 "Disenos Y Technologia" 211 "Digital Switching Systems" 215 "Xintex/Atena" 224 "EMMI NETWORK" 228 "ZF" 229 "Garmin" 233 "Yacht Monitoring Solutions" 235 "Sailormade Marine Telemetry/Tetra Technology" 243 "Eride" 257 "Honda Motor" 272 "Groco" 273 "Actisense" 274 "Amphenol LTW Technology" 275 "Navico" 283 "Hamilton Jet" 285 "Sea Recovery" 286 "Coelmo SRL Italy" 295 "BEP Marine" 304 "Empir Bus" 305 "NovAtel" 306 "Sleipner Motor" 307 "MBW Technologies" 315 "ICOM" 328 "Qwerty" 329 "Dief" 341 "Boening Automationstechnologie" 345 "Korean Maritime University" 351 "Thrane and Thrane" 355 "Mastervolt" 356 "Fischer Panda Generators" 358 "Victron Energy" 370 "Rolls Royce Marine" 373 "Electronic Design" 374 "Northern Lights" 378 "Glendinning" 381 "B & G" 384 "Rose Point Navigation Systems" 385 "Johnson Outdoors Marine Electronics Inc Geonav" 394 "Capi 2" 396 "Beyond Measure" 400 "Livorsi Marine" 404 "ComNav" 409 "Chetco" 419 "Fusion Electronics" 421 "Standard Horizon" 422 "True Heading" 426 "Egersund Marine Electronics" 427 "em-trak Marine Electronics" 431 "Tohatsu Co, JP" 437 "Digital Yacht" 438 "Comar Systems Limited" 440 "Cummins" 443 "VDO (aka Continental-Corporation)" 451 "Parker Hannifin aka Village Marine Tech" 459 "Alltek Marine Electronics" 460 "SAN GIORGIO S.E.I.N" 466 "Veethree Electronics & Marine" 470 "SI-TEX Marine Electronics" 471 "Sea Cross Marine" 475 "GME aka Standard Communications" 476 "Humminbird Marine Electronics" 478 "Ocean Sat" 481 "Chetco Digital Instruments" 493 "Watcheye" 499 "Lcj Capteurs" 502 "Attwood Marine" 503 "Naviop S.R.L." 504 "Vesper Marine" 510 "Marinesoft" 513 "Simarine" 517 "NoLand Engineering" 518 "Transas USA" 529 "National Instruments Korea" 530 "National Marine Electronics Association" 532 "Onwa Marine" 540 "Webasto" 571 "Marinecraft (South Korea)" 573 "McMurdo Group aka Orolia" 578 "Advansea" 579 "KVH" 580 "San Jose Technology" 583 "Yacht Control" 586 "Suzuki Motor" 591 "US Coast Guard" 595 "Ship Module aka Customware" 600 "Aquatic AV" 605 "Aventics" 606 "Intellian" 612 "SamwonIT" 614 "Arlt Tecnologies" 637 "Bavaria Yachts" 641 "Diverse Yacht Services" 644 "Wema U.S.A dba KUS" 658 "Shenzhen Jiuzhou Himunication" 688 "Rockford" 699 "Harman International" 704 "JL Audio" 708 "Lars Thrane" 715 "Autonnic" 717 "Yacht Devices" 734 "REAP Systems" 735 "AEM Performance Electronics" 739 "LxNav" 741 "Littelfuse, Inc (formerly Carling Technologies)" 743 "DaeMyung" 744 "Woosung" 748 "ISOTTA IFRA srl" 773 "Clarion US" 776 "HMI Systems" 777 "Ocean Signal" 778 "Seakeeper" 781 "Poly Planar" 785 "Fischer Panda DE" 795 "Broyda Industries" 796 "Canadian Automotive" 797 "Tides Marine" 798 "Lumishore" 799 "Still Water Designs and Audio" 802 "BJ Technologies (Beneteau)" 803 "Gill Sensors" 811 "Blue Water Desalination" 815 "FLIR" 824 "Undheim Systems" 826 "Lewmar" 838 "TeamSurv" 844 "Fell Marine" 847 "Oceanvolt" 862 "Prospec" 868 "Data Panel" 890 "L3 Technologies" 894 "Rhodan Marine Systems" 896 "Nexfour Solutions" 905 "ASA Electronics" 909 "Marines Co (South Korea)" 911 "Nautic-on" 917 "Sentinel" 929 "JL Marine Systems" 930 "Ecotronix" 944 "Zontisa Marine" 951 "EXOR International" 962 "Timbolier Industries" 963 "TJC Micro" 968 "Cox Powertrain" 969 "Blue Seas" 981 "Kobelt Manufacturing" 992 "Blue Ocean IOT" 997 "Xenta Systems" 999 "Signal K" 1004 "Ultraflex" 1008 "Lintest SmartBoat" 1011 "Soundmax" 1020 "Team Italia Marine (Onyx Marine Automation s.r.l)" 1021 "Entratech" 1022 "ITC" 1029 "The Marine Guardian" 1047 "Sonic" 1051 "ProNav" 1053 "Vetus Maxwell INC." 1056 "Lithium Pros" 1059 "Boatrax" 1062 "Marol Co ltd" 1065 "CALYPSO Instruments" 1066 "Spot Zero Water" 1069 "Lithionics Battery" 1070 "Quick-teck Electronics" 1075 "Uniden America" 1083 "Nauticoncept" 1084 "Shadow-Caster LED lighting" 1085 "Wet Sounds" 1088 "E-T-A Circuit Breakers" 1092 "Scheiber" 1100 "Smart Yachts International Limited" 1109 "Dockmate" 1114 "Bobs Machine" 1118 "L3Harris ASV" 1119 "Balmar" 1120 "Elettromedia" 1127 "Electromaax" 1140 "Across Oceans Systems" 1145 "Kiwi Yachting" 1150 "BSB Artificial Intelligence" 1151 "Orca Technologies" 1154 "TBS Electronics" 1158 "Technoton Electroics" 1160 "MG Energy Systems" 1169 "Sea Machine Robotics" 1171 "Vista Manufacturing" 1183 "Zipwake" 1186 "Sailmon" 1192 "Airmoniq Pro Kft" 1194 "Sierra Marine" 1200 "Xinuo Information Technology (Xiamen)" 1218 "Septentrio" 1233 "NKE Marine Electronics" 1238 "SuperTrack Aps" 1239 "Honda Electronics" 1245 "Raritan Engineering" 1249 "Integrated Power Solutions AG" 1260 "Interactive Technologies" 1283 "LTG-Tech" 1299 "Energy Solutions (UK)" 1300 "WATT Fuel Cell" 1302 "Pro Mainer" 1305 "Dragonfly Energy" 1306 "Koden Electronics" 1311 "Humphree" 1316 "Hinkley Yachts" 1317 "Global Marine Management GmbH (GMM)" 1320 "Triskel Marine" 1330 "Warwick Control Technologies" 1331 "Dolphin Charger" 1337 "Barnacle Systems" 1348 "Radian IoT" 1353 "Ocean LED Marine" 1359 "BluNav" 1361 "OVA (Nantong Saiyang Electronics Co., Ltd)" 1368 "RAD Propulsion" 1369 "Electric Yacht" 1372 "Elco Motor Yachts" 1384 "Tecnoseal Foundry S.r.l" 1385 "Pro Charging Systems" 1389 "EVEX" 1398 "Gobius Sensor Technology" 1403 "Arco Marine" 1408 "Lenco Marine" 1413 "Naocontrol" 1417 "Revatek" 1438 "Aeolionics" 1439 "PredictWind" 1440 "Egis Mobile Electric" 1445 "Starboard Yacht Group" 1446 "Roswell Marine" 1451 "ePropulsion (Guangdong ePropulsion Technology Ltd.)" 1452 "Micro-Air" 1453 "Vital Battery" 1458 "Ride Controller" 1460 "Tocaro Blue" 1461 "Vanquish Yachts" 1471 "FT Technologies" 1478 "Alps Alpine" 1481 "E-Force Marine" 1482 "CMC Marine" 1483 "Nanjing Sandemarine Information Technology" 1850 "Teleflex Marine (SeaStar Solutions)" 1851 "Raymarine" 1852 "Navionics" 1853 "Japan Radio" 1854 "Northstar Technologies" 1855 "Furuno" 1856 "Trimble" 1857 "Simrad" 1858 "Litton" 1859 "Kvasar" 1860 "MMP" 1861 "Vector Cantech" 1862 "Yamaha Marine" 1863 "Faria Instruments" ;
VAL_ 2650743552 Industry_Code 0 "Global" 1 "Highway" 2 "Agriculture" 3 "Construction" 4 "Marine Industry" 5 "Industrial" ;
VAL_ 2650743552 Network_Group 0 "None" 1 "Default" 2 "Group 1" 3 "Group 2" 4 "Group 3" 5 "Group 4" 6 "Group 5" 7 "Group 6" ;
VAL_ 2650743552 Command_Type 2 "Follow Up" 10 "AP Command" 23 "Timer" 31 "Siren" 36 "AIS vessel selected" 255 "Alarm" ;
VAL_ 2650743552 Event 2 "Follow/Non Follow" 6 "Standby" 9 "Heading mode" 10 "Nav mode" 12 "No Drift mode" 13 "Non Follow Up mode" 14 "Follow Up mode" 15 "Wind mode" 17 "Tack" 18 "Square (Turn)" 19 "C-Turn" 20 "U-Turn" 21 "Spiral (Turn)" 22 "Zig Zag (Turn)" 23 "Lazy-S (Turn)" 24 "Depth (Turn)" 26 "Change course" 61 "Timer sync" 107 "MOB Activated" 108 "MOB Deactivated" 112 "Ping port end" 113 "Ping starboard end" ;
VAL_ 2650743552 Direction 2 "Port" 3 "Starboard" 4 "Left rudder (port)" 5 "Right rudder (starboard)" ;
VAL_ 2583634944 Manufacturer_Code 69 "ARKS Enterprises" 78 "FW Murphy/Enovation Controls" 80 "Twin Disc" 85 "Kohler Power Systems" 88 "Hemisphere GPS" 135 "Airmar" 137 "Maretron" 140 "Lowrance" 144 "Mercury Marine" 147 "Nautibus Electronic" 148 "Blue Water Data" 154 "Westerbeke" 157 "ISSPRO" 161 "Offshore Systems (UK)" 163 "Evinrude/BRP" 165 "CPAC Systems" 168 "Xantrex Technology" 169 "Marlin Technologies" 172 "Yanmar Marine" 174 "Volvo Penta" 176 "Carling Technologies Inc. (Moritz Aerospace)" 185 "Beede Instruments" 192 "Floscan Instrument" 193 "Nobeltec" 198 "Mystic Valley Communications" 199 "Actia" 201 "Disenos Y Technologia" 211 "Digital Switching Systems" 215 "Xintex/Atena" 224 "EMMI NETWORK" 228 "ZF" 229 "Garmin" 233 "Yacht Monitoring Solutions" 235 "Sailormade Marine Telemetry/Tetra Technology" 243 "Eride" 257 "Honda Motor" 272 "Groco" 273 "Actisense" 274 "Amphenol LTW Technology" 275 "Navico" 283 "Hamilton Jet" 285 "Sea Recovery" 286 "Coelmo SRL Italy" 295 "BEP Marine" 304 "Empir Bus" 305 "NovAtel" 306 "Sleipner Motor" 307 "MBW Technologies" 315 "ICOM" 328 "Qwerty" 329 "Dief" 341 "Boening Automationstechnologie" 345 "Korean Maritime University" 351 "Thrane and Thrane" 355 "Mastervolt" 356 "Fischer Panda Generators" 358 "Victron Energy" 370 "Rolls Royce Marine" 373 "Electronic Design" 374 "Northern Lights" 378 "Glendinning" 381 "B & G" 384 "Rose Point Navigation Systems" 385 "Johnson Outdoors Marine Electronics Inc Geonav" 394 "Capi 2" 396 "Beyond Measure" 400 "Livorsi Marine" 404 "ComNav" 409 "Chetco" 419 "Fusion Electronics" 421 "Standard Horizon" 422 "True Heading" 426 "Egersund Marine Electronics" 427 "em-trak Marine Electronics" 431 "Tohatsu Co, JP" 437 "Digital Yacht" 438 "Comar Systems Limited" 440 "Cummins" 443 "VDO (aka Continental-Corporation)" 451 "Parker Hannifin aka Village Marine Tech" 459 "Alltek Marine Electronics" 460 "SAN GIORGIO S.E.I.N" 466 "Veethree Electronics & Marine" 470 "SI-TEX Marine Electronics" 471 "Sea Cross Marine" 475 "GME aka Standard Communications" 476 "Humminbird Marine Electronics" 478 "Ocean Sat" 481 "Chetco Digital Instruments" 493 "Watcheye" 499 "Lcj Capteurs" 502 "Attwood Marine" 503 "Naviop S.R.L." 504 "Vesper Marine" 510 "Marinesoft" 513 "Simarine" 517 "NoLand Engineering" 518 "Transas USA" 529 "National Instruments Korea" 530 "National Marine Electronics Association" 532 "Onwa Marine" 540 "Webasto" 571 "Marinecraft (South Korea)" 573 "McMurdo Group aka Orolia" 578 "Advansea" 579 "KVH" 580 "San Jose Technology" 583 "Yacht Control" 586 "Suzuki Motor" 591 "US Coast Guard" 595 "Ship Module aka Customware" 600 "Aquatic AV" 605 "Aventics" 606 "Intellian" 612 "SamwonIT" 614 "Arlt Tecnologies" 637 "Bavaria Yachts" 641 "Diverse Yacht Services" 644 "Wema U.S.A dba KUS" 658 "Shenzhen Jiuzhou Himunication" 688 "Rockford" 699 "Harman International" 704 "JL Audio" 708 "Lars Thrane" 715 "Autonnic" 717 "Yacht Devices" 734 "REAP Systems" 735 "AEM Performance Electronics" 739 "LxNav" 741 "Littelfuse, Inc (formerly Carling Technologies)" 743 "DaeMyung" 744 "Woosung" 748 "ISOTTA IFRA srl" 773 "Clarion US" 776 "HMI Systems" 777 "Ocean Signal" 778 "Seakeeper" 781 "Poly Planar" 785 "Fischer Panda DE" 795 "Broyda Industries" 796 "Canadian Automotive" 797 "Tides Marine" 798 "Lumishore" 799 "Still Water Designs and Audio" 802 "BJ Technologies (Beneteau)" 803 "Gill Sensors" 811 "Blue Water Desalination" 815 "FLIR" 824 "Undheim Systems" 826 "Lewmar" 838 "TeamSurv" 844 "Fell Marine" 847 "Oceanvolt" 862 "Prospec" 868 "Data Panel" 890 "L3 Technologies" 894 "Rhodan Marine Systems" 896 "Nexfour Solutions" 905 "ASA Electronics" 909 "Marines Co (South Korea)" 911 "Nautic-on" 917 "Sentinel" 929 "JL Marine Systems" 930 "Ecotronix" 944 "Zontisa Marine" 951 "EXOR International" 962 "Timbolier Industries" 963 "TJC Micro" 968 "Cox Powertrain" 969 "Blue Seas" 981 "Kobelt Manufacturing" 992 "Blue Ocean IOT" 997 "Xenta Systems" 999 "Signal K" 1004 "Ultraflex" 1008 "Lintest SmartBoat" 1011 "Soundmax" 1020 "Team Italia Marine (Onyx Marine Automation s.r.l)" 1021 "Entratech" 1022 "ITC" 1029 "The Marine Guardian" 1047 "Sonic" 1051 "ProNav" 1053 "Vetus Maxwell INC." 1056 "Lithium Pros" 1059 "Boatrax" 1062 "Marol Co ltd" 1065 "CALYPSO Instruments" 1066 "Spot Zero Water" 1069 "Lithionics Battery" 1070 "Quick-teck Electronics" 1075 "Uniden America" 1083 "Nauticoncept" 1084 "Shadow-Caster LED lighting" 1085 "Wet Sounds" 1088 "E-T-A Circuit Breakers" 1092 "Scheiber" 1100 "Smart Yachts International Limited" 1109 "Dockmate" 1114 "Bobs Machine" 1118 "L3Harris ASV" 1119 "Balmar" 1120 "Elettromedia" 1127 "Electromaax" 1140 "Across Oceans Systems" 1145 "Kiwi Yachting" 1150 "BSB Artificial Intelligence" 1151 "Orca Technologies" 1154 "TBS Electronics" 1158 "Technoton Electroics" 1160 "MG Energy Systems" 1169 "Sea Machine Robotics" 1171 "Vista Manufacturing" 1183 "Zipwake" 1186 "Sailmon" 1192 "Airmoniq Pro Kft" 1194 "Sierra Marine" 1200 "Xinuo Information Technology (Xiamen)" 1218 "Septentrio" 1233 "NKE Marine Electronics" 1238 "SuperTrack Aps" 1239 "Honda Electronics" 1245 "Raritan Engineering" 1249 "Integrated Power Solutions AG" 1260 "Interactive Technologies" 1283 "LTG-Tech" 1299 "Energy Solutions (UK)" 1300 "WATT Fuel Cell" 1302 "Pro Mainer" 1305 "Dragonfly Energy" 1306 "Koden Electronics" 1311 "Humphree" 1316 "Hinkley Yachts" 1317 "Global Marine Management GmbH (GMM)" 1320 "Triskel Marine" 1330 "Warwick Control Technologies" 1331 "Dolphin Charger" 1337 "Barnacle Systems" 1348 "Radian IoT" 1353 "Ocean LED Marine" 1359 "BluNav" 1361 "OVA (Nantong Saiyang Electronics Co., Ltd)" 1368 "RAD Propulsion" 1369 "Electric Yacht" 1372 "Elco Motor Yachts" 1384 "Tecnoseal Foundry S.r.l" 1385 "Pro Charging Systems" 1389 "EVEX" 1398 "Gobius Sensor Technology" 1403 "Arco Marine" 1408 "Lenco Marine" 1413 "Naocontrol" 1417 "Revatek" 1438 "Aeolionics" 1439 "PredictWind" 1440 "Egis Mobile Electric" 1445 "Starboard Yacht Group" 1446 "Roswell Marine" 1451 "ePropulsion (Guangdong ePropulsion Technology Ltd.)" 1452 "Micro-Air" 1453 "Vital Battery" 1458 "Ride Controller" 1460 "Tocaro Blue" 1461 "Vanquish Yachts" 1471 "FT Technologies" 1478 "Alps Alpine" 1481 "E-Force Marine" 1482 "CMC Marine" 1483 "Nanjing Sandemarine Information Technology" 1850 "Teleflex Marine (SeaStar Solutions)" 1851 "Raymarine" 1852 "Navionics" 1853 "Japan Radio" 1854 "Northstar Technologies" 1855 "Furuno" 1856 "Trimble" 1857 "Simrad" 1858 "Litton" 1859 "Kvasar" 1860 "MMP" 1861 "Vector Cantech" 1862 "Yamaha Marine" 1863 "Faria Instruments" ;
VAL_ 2583634944 Industry_Code 0 "Global" 1 "Highway" 2 "Agriculture" 3 "Construction" 4 "Marine Industry" 5 "Industrial" ;
CM_ SG_ 2650742784 Waypoint_Name "STRING field: decode bytes as ASCII (0x00/@/0xFF = terminator); canboat type: STRING_FIX";
CM_ SG_ 2650742784 Waypoint_Sequence "STRING field: decode bytes as ASCII (0x00/@/0xFF = terminator); canboat type: STRING_FIX";

BA_DEF_ BO_ "GenMsgCycleTime" INT 0 60000;
BA_DEF_ BO_ "ProtocolType" STRING;

BA_DEF_ BO_ "J1939PGN" INT 0 262143;
BA_ "J1939PGN" BO_ 2583633408 130846;
BA_ "J1939PGN" BO_ 2583633408 130846;
BA_ "J1939PGN" BO_ 2583633408 130846;
BA_ "J1939PGN" BO_ 2650742528 130847;
BA_ "J1939PGN" BO_ 2583633664 130847;
BA_ "J1939PGN" BO_ 2650742784 130848;
BA_ "GenMsgCycleTime" BO_ 2650742784 1000;
BA_ "J1939PGN" BO_ 2583634176 130849;
BA_ "J1939PGN" BO_ 2315198976 130850;
BA_ "J1939PGN" BO_ 2315198976 130850;
BA_ "J1939PGN" BO_ 2315198976 130850;
BA_ "J1939PGN" BO_ 2315198976 130850;
BA_ "J1939PGN" BO_ 2315198976 130850;
BA_ "J1939PGN" BO_ 2315198976 130850;
BA_ "J1939PGN" BO_ 2315198976 130850;
BA_ "J1939PGN" BO_ 2315198976 130850;
BA_ "J1939PGN" BO_ 2315198976 130850;
BA_ "J1939PGN" BO_ 2315198976 130850;
BA_ "J1939PGN" BO_ 2315198976 130850;
BA_ "J1939PGN" BO_ 2315198976 130850;
BA_ "J1939PGN" BO_ 2650743552 130851;
BA_ "J1939PGN" BO_ 2650743552 130851;
BA_ "J1939PGN" BO_ 2583634944 130852;
